VERSION ""

NS_ :

BS_:

BU_: L_DHRR_FD L_UWB_BLE_MST_FD L_UWB_RR_FD L_UWB_BLE_SLV_FD L_UWB_FR_FD L_ROA_FR_FD L_ROA_FD L_DHRL_FD L_UWB_TRNK_FD L_UWB_FRNK_FD L_EDT_FD L_UWB_FL_FD GW_BDC_FD L_UWB_RL_FD L_SAL_FD L_WPC_FD L_TPMS_FD L_DHL_FD L_DHR_FD

BO_ 830 SBCM_RL_FD_01_200ms: 24 GW_BDC_FD
 SG_ SBCM_RL_FD_Crc1Val : 0|16@1+ (1,0) [0|0] "" Vector__XXX
 SG_ USM_RLGhostDoorSta_Copy_0 : 100|2@1+ (1,0) [0|0] "" Vector__XXX
 SG_ DoorLock_PDSLkSwSta_RL_Copy_0 : 104|2@1+ (1,0) [0|0] "" Vector__XXX
 SG_ PDS_TypeOption_RL_Copy_0 : 106|2@1+ (1,0) [0|0] "" Vector__XXX
 SG_ RL_CrashMRActAlarm_Copy_0 : 138|2@1+ (1,0) [0|0] "" Vector__XXX
 SG_ PwrDRBuzzerOut_RL_Copy_0 : 140|2@1+ (1,0) [0|0] "" Vector__XXX
 SG_ PwrDRClosingRLDrSta_Copy_0 : 144|3@1+ (1,0) [0|0] "" Vector__XXX
 SG_ AFH_RL_FldUnfldSta_Copy_0 : 150|2@1+ (1,0) [0|0] "" Vector__XXX
 SG_ SBCM_RL_FD_AlvCnt1Val : 16|8@1+ (1,0) [0|0] "" Vector__XXX
 SG_ DoorLock_RrLtLkOutSta_SBCM_Copy_ : 166|2@1+ (1,0) [0|0] "" Vector__XXX
 SG_ RrLt_DrLkRetryFail_SBCM_Copy_0 : 171|2@1+ (1,0) [0|0] "" Vector__XXX
 SG_ RL_DetectObj_warn : 24|2@1+ (1,0) [0|0] "" Vector__XXX
 SG_ RLRrDrCurtainPosition : 26|2@1+ (1,0) [0|0] "" Vector__XXX
 SG_ RDC_TypeOption : 28|2@1+ (1,0) [0|0] "" Vector__XXX
 SG_ RLRrDrCurtainDownInitState : 30|2@1+ (1,0) [0|0] "" Vector__XXX
 SG_ PwrDRBuzzerOut_RL_New : 32|3@1+ (1,0) [0|0] "" Vector__XXX
 SG_ PwrDrSta_RrLt : 38|2@1+ (1,0) [0|0] "" Vector__XXX
 SG_ SBCM_RL_SlidePosition : 40|8@1+ (1,0) [0|0] "%" Vector__XXX
 SG_ SBCM_RL_DoorAngle : 48|7@1+ (1,0) [0|0] "вк" Vector__XXX
 SG_ RLDoorPushAlarm_Copy_0 : 72|2@1+ (1,0) [0|0] "" Vector__XXX
 SG_ RL_CrashUnlockCmd_Copy_0 : 74|1@1+ (1,0) [0|0] "" Vector__XXX
 SG_ Warn_RrLftDrSwSta_SBCM_Copy_0 : 80|2@1+ (1,0) [0|0] ""  L_UWB_BLE_MST_FD
 SG_ DoorLock_RrLftDrUnLkSta_SBCM_Cop : 82|2@1+ (1,0) [0|0] ""  L_UWB_BLE_MST_FD
 SG_ RL_SEAActivated_Copy_0 : 84|2@1+ (1,0) [0|0] "" Vector__XXX
 SG_ RL_SEAWarn_Copy_0 : 86|2@1+ (1,0) [0|0] "" Vector__XXX
 SG_ RL_SEWWarn_Copy_0 : 88|2@1+ (1,0) [0|0] "" Vector__XXX
 SG_ RL_ReleaseWarn_Copy_0 : 90|2@1+ (1,0) [0|0] "" Vector__XXX
 SG_ RL_SWFailAlarm_Copy_0 : 92|2@1+ (1,0) [0|0] "" Vector__XXX
 SG_ RL_ChildLock_ActnFlSta_Copy_0 : 94|2@1+ (1,0) [0|0] "" Vector__XXX
 SG_ RL_MRActivationAlarm_Copy_0 : 96|2@1+ (1,0) [0|0] "" Vector__XXX
 SG_ RL_ChildLock_Status_Copy_0 : 98|2@1+ (1,0) [0|0] "" Vector__XXX

BO_ 813 SBCM_DRV_FD_01_200ms: 32 GW_BDC_FD
 SG_ SBCM_DRV_FD_Crc1Val : 0|16@1+ (1,0) [0|0] "" Vector__XXX
 SG_ Latch_TypeOption_DRV_Copy_0 : 100|2@1+ (1,0) [0|0] ""  L_UWB_BLE_MST_FD
 SG_ DRV_SWFailAlarm_Copy_0 : 102|2@1+ (1,0) [0|0] "" Vector__XXX
 SG_ USM_PwrDRApprOpnSetSta_Copy_0 : 104|2@1+ (1,0) [0|0] "" Vector__XXX
 SG_ USM_PwrDRApprOpnSetOpt_Copy_0 : 106|2@1+ (1,0) [0|0] "" Vector__XXX
 SG_ USM_PwrDRCloseByRKELockSta_Copy_ : 108|2@1+ (1,0) [0|0] "" Vector__XXX
 SG_ USM_PwrDRCloseByRKELockOpt_Copy_ : 110|2@1+ (1,0) [0|0] "" Vector__XXX
 SG_ USM_PwrDRCloseByBrakeSta_Copy_0 : 112|2@1+ (1,0) [0|0] "" Vector__XXX
 SG_ USM_PwrDRCloseByBrakeOpt_Copy_0 : 114|2@1+ (1,0) [0|0] "" Vector__XXX
 SG_ USM_PwrDRBuzzerSta_Copy_0 : 116|2@1+ (1,0) [0|0] "" Vector__XXX
 SG_ USM_PwrDRBuzzerOpt_Copy_0 : 118|2@1+ (1,0) [0|0] "" Vector__XXX
 SG_ PDS_TypeOption_DRV_Copy_0 : 120|2@1+ (1,0) [0|0] "" Vector__XXX
 SG_ C_DrvDoorApproachOpen_Copy_0 : 122|2@1+ (1,0) [0|0] "" Vector__XXX
 SG_ C_DrvDoorApproachClose_Copy_0 : 124|2@1+ (1,0) [0|0] "" Vector__XXX
 SG_ DoorLock_PDSLkSwSta_DRV_Copy_0 : 126|2@1+ (1,0) [0|0] "" Vector__XXX
 SG_ SBCM_DRV_DiagSta_Copy_0 : 136|2@1+ (1,0) [0|0] "" Vector__XXX
 SG_ DoorLock_CtrlDrLkUnLkSwSta_SBCM_ : 138|2@1+ (1,0) [0|0] "" Vector__XXX
 SG_ SBCM_PsvDrLkReq_Copy_0 : 144|2@1+ (1,0) [0|0] "" Vector__XXX
 SG_ CDMAutoWashModeSet_SBCM_Copy_0 : 146|3@1+ (1,0) [0|0] "" Vector__XXX
 SG_ USM_DrvGhostDoorSta_Copy_0 : 150|2@1+ (1,0) [0|0] "" Vector__XXX
 SG_ Mirror_LH_FoldingSta_Copy_0 : 152|2@1+ (1,0) [0|0] "" Vector__XXX
 SG_ Mirror_LH_UnfoldingSta_Copy_0 : 154|2@1+ (1,0) [0|0] "" Vector__XXX
 SG_ DRV_CrashMRActAlarm_Copy_0 : 156|2@1+ (1,0) [0|0] "" Vector__XXX
 SG_ AFH_DRV_FldUnFldSta_Copy_0 : 158|2@1+ (1,0) [0|0] "" Vector__XXX
 SG_ SBCM_DRV_FD_AlvCnt1Val : 16|8@1+ (1,0) [0|0] "" Vector__XXX
 SG_ MirrorFldReq_Copy_0 : 160|2@1+ (1,0) [0|0] "" Vector__XXX
 SG_ OMU_TypeOption_DRV_Copy_0 : 162|2@1+ (1,0) [0|0] "" Vector__XXX
 SG_ IMS_OSMirPlayBackSta_LH_Copy_0 : 164|4@1+ (1,0) [0|0] "" Vector__XXX
 SG_ ECMMRR_PLUS_Copy_0 : 168|8@1+ (1,0) [0|0] "" Vector__XXX
 SG_ EHL_TxInfo_SBCM_DRV_Copy_0 : 176|3@1+ (1,0) [0|0] "" Vector__XXX
 SG_ IMS_OSMirPlayBackSta_LH_New_Copy : 184|4@1+ (1,0) [0|0] "" Vector__XXX
 SG_ CDM_InsideOpnSwSta_Copy_0 : 200|2@1+ (1,0) [0|0] "" Vector__XXX
 SG_ CDM_TypeOption_Copy_0 : 202|2@1+ (1,0) [0|0] "" Vector__XXX
 SG_ CDM_ImmeChgSw_SBCM_Copy_0 : 208|2@1+ (1,0) [0|0] "" Vector__XXX
 SG_ CDM_FobSrchReq_DRV_Copy_0 : 210|2@1+ (1,0) [0|0] "" Vector__XXX
 SG_ CDM_OpnClsState_SBCM_Copy_0 : 212|2@1+ (1,0) [0|0] "" Vector__XXX
 SG_ CDM_WarnMsg_SBCM_Copy_0 : 214|2@1+ (1,0) [0|0] "" Vector__XXX
 SG_ CDM_AutoWashModeSta_Copy_0 : 216|3@1+ (1,0) [0|0] "" Vector__XXX
 SG_ CDM_CmdStatus_SBCM_Copy_0 : 220|4@1+ (1,0) [0|0] "" Vector__XXX
 SG_ CDM_OutsideOpnSwSta_Copy_0 : 224|2@1+ (1,0) [0|0] "" Vector__XXX
 SG_ PwrDRBuzzerOut_DRV_Copy_0 : 226|2@1+ (1,0) [0|0] "" Vector__XXX
 SG_ Warn_HoodSwSta_SBCM_Copy_0 : 228|2@1+ (1,0) [0|0] ""  L_UWB_BLE_MST_FD
 SG_ Hood_TypeOption_Copy_0 : 230|2@1+ (1,0) [0|0] ""  L_UWB_BLE_MST_FD
 SG_ SBCM_FrunkSta_Copy_0 : 232|2@1+ (1,0) [0|0] "" Vector__XXX
 SG_ Warn_HoodSwFullSta_SBCM_Copy_0 : 234|2@1+ (1,0) [0|0] "" Vector__XXX
 SG_ FrunkWarning_SBCM_Copy_0 : 236|2@1+ (1,0) [0|0] "" Vector__XXX
 SG_ SBCM_Longkey_DRVDrAtClsSwSta_Cop : 238|2@1+ (1,0) [0|0] "" Vector__XXX
 SG_ FrunkReleaseSwSta_SBCM : 24|2@1+ (1,0) [0|0] "" Vector__XXX
 SG_ PwrDRClosingDRVDrSta_Copy_0 : 240|3@1+ (1,0) [0|0] "" Vector__XXX
 SG_ Drv_DrLkRetryFail_SBCM_Copy_0 : 243|2@1+ (1,0) [0|0] "" Vector__XXX
 SG_ CDM_GbtImmeChgSw_SBCM_Copy_0 : 246|2@1+ (1,0) [0|0] "" Vector__XXX
 SG_ CDM_GbtOpnClsState_SBCM_Copy_0 : 248|2@1+ (1,0) [0|0] "" Vector__XXX
 SG_ CDM_GbtWarnMsg_SBCM_Copy_0 : 250|2@1+ (1,0) [0|0] "" Vector__XXX
 SG_ CDM_GbtOutsideOpnSwSta_Copy_0 : 252|2@1+ (1,0) [0|0] "" Vector__XXX
 SG_ DoorLock_DrvLkOutSta_SBCM_Copy_0 : 254|2@1+ (1,0) [0|0] "" Vector__XXX
 SG_ FrunkEmergencySwSta_SBCM : 28|2@1+ (1,0) [0|0] "" Vector__XXX
 SG_ DRV_DetectObj_warn_LH : 30|2@1+ (1,0) [0|0] "" Vector__XXX
 SG_ PwrDROpenClosingDdvSdDRSta : 32|3@1+ (1,0) [0|0] "" Vector__XXX
 SG_ PwrDRBuzzerOut_DRV_New : 35|3@1+ (1,0) [0|0] "" Vector__XXX
 SG_ Coach_TypeOption_DRV : 38|2@1+ (1,0) [0|0] "" Vector__XXX
 SG_ PwrDrSta_Drv : 40|2@1+ (1,0) [0|0] "" Vector__XXX
 SG_ PwrDrSta_DrvSd : 42|2@1+ (1,0) [0|0] "" Vector__XXX
 SG_ USM_PwrDrOpnTypSta : 44|2@1+ (1,0) [0|0] "" Vector__XXX
 SG_ DischrgDr_OpnClsState_SBCM : 46|2@1+ (1,0) [0|0] "" Vector__XXX
 SG_ SBCM_FL_DoorAngle : 48|7@1+ (1,0) [0|0] "вк" Vector__XXX
 SG_ SBCM_DoorType_DRV : 60|2@1+ (1,0) [0|0] "" Vector__XXX
 SG_ CDM_DrType_DRV : 62|2@1+ (1,0) [0|0] "" Vector__XXX
 SG_ DRVDoorPushAlarm_Copy_0 : 72|2@1+ (1,0) [0|0] "" Vector__XXX
 SG_ DRV_CrashUnlockCmd_Copy_0 : 74|1@1+ (1,0) [0|0] "" Vector__XXX
 SG_ C_ApprOpenStatus_Copy_0 : 75|1@1+ (1,0) [0|0] "" Vector__XXX
 SG_ DoorLock_DrvKeyLkSwSta_SBCM_Copy : 80|2@1+ (1,0) [0|0] "" Vector__XXX
 SG_ DoorLock_DrvKeyUnLkSwSta_SBCM_Co : 82|2@1+ (1,0) [0|0] "" Vector__XXX
 SG_ Warn_DrvDrSwSta_SBCM_Copy_0 : 84|2@1+ (1,0) [0|0] ""  L_UWB_BLE_MST_FD
 SG_ DoorLock_DrvDrUnLkSta_SBCM_Copy_ : 86|2@1+ (1,0) [0|0] ""  L_UWB_BLE_MST_FD
 SG_ DRV_SEAWarn_LH_Copy_0 : 88|2@1+ (1,0) [0|0] "" Vector__XXX
 SG_ DRV_SEAWarn_RH_Copy_0 : 90|2@1+ (1,0) [0|0] "" Vector__XXX
 SG_ DRV_SEWWarn_LH_Copy_0 : 92|2@1+ (1,0) [0|0] "" Vector__XXX
 SG_ DRV_SEWWarn_RH_Copy_0 : 94|2@1+ (1,0) [0|0] "" Vector__XXX
 SG_ DRV_MRActivationAlarm_Copy_0 : 96|2@1+ (1,0) [0|0] "" Vector__XXX
 SG_ DRV_ReleaseWarn_Copy_0 : 98|2@1+ (1,0) [0|0] "" Vector__XXX

BO_ 811 SBCM_AST_FD_01_200ms: 32 GW_BDC_FD
 SG_ SBCM_AST_FD_Crc1Val : 0|16@1+ (1,0) [0|0] "" Vector__XXX
 SG_ USM_AstGhostDoorSta_Copy_0 : 100|2@1+ (1,0) [0|0] "" Vector__XXX
 SG_ AST_SWFailAlarm_Copy_0 : 102|2@1+ (1,0) [0|0] "" Vector__XXX
 SG_ DoorLock_PDSLkSwSta_AST_Copy_0 : 104|2@1+ (1,0) [0|0] "" Vector__XXX
 SG_ PDS_TypeOption_AST_Copy_0 : 106|2@1+ (1,0) [0|0] "" Vector__XXX
 SG_ AFCU_AutoWashModeSta_SBCM_AST_Co : 120|3@1+ (1,0) [0|0] "" Vector__XXX
 SG_ CDM_AutoWashModeSta_SBCM_AST_Cop : 123|3@1+ (1,0) [0|0] "" Vector__XXX
 SG_ AFH_AST_FldUnFldSta_Copy_0 : 126|2@1+ (1,0) [0|0] "" Vector__XXX
 SG_ SBCM_AST_DiagSta_Copy_0 : 136|2@1+ (1,0) [0|0] "" Vector__XXX
 SG_ CDM_TypeOption_AST_Copy_0 : 138|2@1+ (1,0) [0|0] "" Vector__XXX
 SG_ CDM_ImmeChgSw_AST_Copy_0 : 144|2@1+ (1,0) [0|0] "" Vector__XXX
 SG_ CDM_FobSrchReq_AST_Copy_0 : 146|2@1+ (1,0) [0|0] "" Vector__XXX
 SG_ CDM_OpnClsState_AST_Copy_0 : 148|2@1+ (1,0) [0|0] "" Vector__XXX
 SG_ CDM_WarnMsg_AST_Copy_0 : 150|2@1+ (1,0) [0|0] "" Vector__XXX
 SG_ Mirror_RH_FoldingSta_Copy_0 : 152|2@1+ (1,0) [0|0] "" Vector__XXX
 SG_ Mirror_RH_UnfoldingSta_Copy_0 : 154|2@1+ (1,0) [0|0] "" Vector__XXX
 SG_ CDM_CmdStatus_AST_Copy_0 : 156|4@1+ (1,0) [0|0] "" Vector__XXX
 SG_ SBCM_AST_FD_AlvCnt1Val : 16|8@1+ (1,0) [0|0] "" Vector__XXX
 SG_ AST_CrashMRActAlarm_Copy_0 : 160|2@1+ (1,0) [0|0] "" Vector__XXX
 SG_ PwrDRBuzzerOut_AST_Copy_0 : 162|2@1+ (1,0) [0|0] "" Vector__XXX
 SG_ IMS_OSMirPlayBackSta_RH_Copy_0 : 164|4@1+ (1,0) [0|0] "" Vector__XXX
 SG_ PwrDRClosingASTDrSta_Copy_0 : 168|3@1+ (1,0) [0|0] "" Vector__XXX
 SG_ CDM_OutsideOpnSwSta_AST_Copy_0 : 172|2@1+ (1,0) [0|0] "" Vector__XXX
 SG_ SBCM_Longkey_ASTDrAtClsSwSta_Cop : 174|2@1+ (1,0) [0|0] "" Vector__XXX
 SG_ Hood_TypeOption_AST_Copy_0 : 176|2@1+ (1,0) [0|0] "" Vector__XXX
 SG_ Warn_HoodSwSta_AST_Copy_0 : 178|2@1+ (1,0) [0|0] "" Vector__XXX
 SG_ FrunkWarning_AST_Copy_0 : 180|2@1+ (1,0) [0|0] "" Vector__XXX
 SG_ SBCM_FrunkSta_AST_Copy_0 : 182|2@1+ (1,0) [0|0] "" Vector__XXX
 SG_ IMS_OSMirPlayBackSta_RH_New_Copy : 184|4@1+ (1,0) [0|0] "" Vector__XXX
 SG_ Ast_DrLkRetryFail_SBCM_Copy_0 : 188|2@1+ (1,0) [0|0] "" Vector__XXX
 SG_ DoorLock_AstLkOutSta_SBCM_Copy_0 : 190|2@1+ (1,0) [0|0] "" Vector__XXX
 SG_ FrunkReleaseSwSta_SBCM_AST : 192|2@1+ (1,0) [0|0] "" Vector__XXX
 SG_ FrunkInsideRelSwSta_SBCM_AST : 194|2@1+ (1,0) [0|0] "" Vector__XXX
 SG_ FrunkEmergencySwSta_SBCM_AST : 196|2@1+ (1,0) [0|0] "" Vector__XXX
 SG_ PwrDrSta_Ast : 24|2@1+ (1,0) [0|0] "" Vector__XXX
 SG_ PwrDrSta_AstSd : 26|2@1+ (1,0) [0|0] "" Vector__XXX
 SG_ DischrgDr_OpnClsState_SBCM_AST : 28|2@1+ (1,0) [0|0] "" Vector__XXX
 SG_ AST_DetectObj_warn_LH : 30|2@1+ (1,0) [0|0] "" Vector__XXX
 SG_ PwrDROpenClosingAstSdDRSta : 32|3@1+ (1,0) [0|0] "" Vector__XXX
 SG_ PwrDRBuzzerOut_AST_New : 35|3@1+ (1,0) [0|0] "" Vector__XXX
 SG_ SBCM_FR_DoorAngle : 40|7@1+ (1,0) [0|0] "вк" Vector__XXX
 SG_ EHL_TxInfo_SBCM_AST : 47|3@1+ (1,0) [0|0] "" Vector__XXX
 SG_ CDM_DrType_AST : 62|2@1+ (1,0) [0|0] "" Vector__XXX
 SG_ ASTDoorPushAlarm_Copy_0 : 72|2@1+ (1,0) [0|0] "" Vector__XXX
 SG_ AST_CrashUnlockCmd_Copy_0 : 74|1@1+ (1,0) [0|0] "" Vector__XXX
 SG_ DoorLock_CtrlDrLkSwSta_SBCM_Copy : 80|2@1+ (1,0) [0|0] "" Vector__XXX
 SG_ DoorLock_CtrlDrUnLkSwSta_SBCM_Co : 82|2@1+ (1,0) [0|0] "" Vector__XXX
 SG_ Warn_AsstDrSwSta_SBCM_Copy_0 : 84|2@1+ (1,0) [0|0] ""  L_UWB_BLE_MST_FD
 SG_ DoorLock_AsstDrUnLkSta_SBCM_Copy : 86|2@1+ (1,0) [0|0] "" Vector__XXX
 SG_ AST_SEAWarn_RH_Copy_0 : 88|2@1+ (1,0) [0|0] "" Vector__XXX
 SG_ AST_SEAWarn_LH_Copy_0 : 90|2@1+ (1,0) [0|0] "" Vector__XXX
 SG_ AST_SEWWarn_LH_Copy_0 : 92|2@1+ (1,0) [0|0] "" Vector__XXX
 SG_ AST_SEWWarn_RH_Copy_0 : 94|2@1+ (1,0) [0|0] "" Vector__XXX
 SG_ AST_MRActivationAlarm_Copy_0 : 96|2@1+ (1,0) [0|0] "" Vector__XXX
 SG_ AST_ReleaseWarn_Copy_0 : 98|2@1+ (1,0) [0|0] "" Vector__XXX

BO_ 2525341953 L_UWB_FR_FD_05_00ms: 32 L_UWB_FR_FD
 SG_ L_UWB_FR_FD_Crc5Val : 0|16@1+ (1,0) [0|0] "" Vector__XXX
 SG_ L_UWB_FR_FD_AlvCnt5Val : 16|8@1+ (1,0) [0|0] "" Vector__XXX
 SG_ FR_SWID_3_IVD_2 : 24|24@1+ (1,0) [0|0] ""  L_UWB_BLE_MST_FD

BO_ 2521141761 L_UWB_BLE_MST_FD_23_200ms: 32 L_UWB_BLE_MST_FD
 SG_ L_UWB_BLE_MST_FD_Crc23Val : 0|16@1+ (1,0) [0|0] "" Vector__XXX
 SG_ L_UWB_BLE_MST_FD_AlvCnt23Val : 16|8@1+ (1,0) [0|0] "" Vector__XXX
 SG_ MST_DTC : 24|8@1+ (1,0) [0|0] ""  L_EDT_FD
 SG_ MST_DTC_BLE : 32|8@1+ (1,0) [0|0] ""  L_EDT_FD
 SG_ Pulse_Shape_Combo_Info : 40|9@1+ (1,0) [0|0] ""  GW_BDC_FD,L_EDT_FD

BO_ 2214592770 L_UWB_RR_FD_03_00ms: 32 L_UWB_RR_FD
 SG_ L_UWB_RR_FD_Crc3Val : 0|16@1+ (1,0) [0|0] "0" Vector__XXX
 SG_ L_UWB_RR_FD_AlvCnt3Val : 16|8@1+ (1,0) [0|0] "0" Vector__XXX
 SG_ UWB_RR_Ranging_Enc_Result2 : 216|40@1+ (1,0) [0|0] ""  GW_BDC_FD,L_UWB_BLE_MST_FD
 SG_ UWB_RR_Ranging_Enc_Result : 24|192@1+ (1,0) [0|0] ""  GW_BDC_FD,L_UWB_BLE_MST_FD

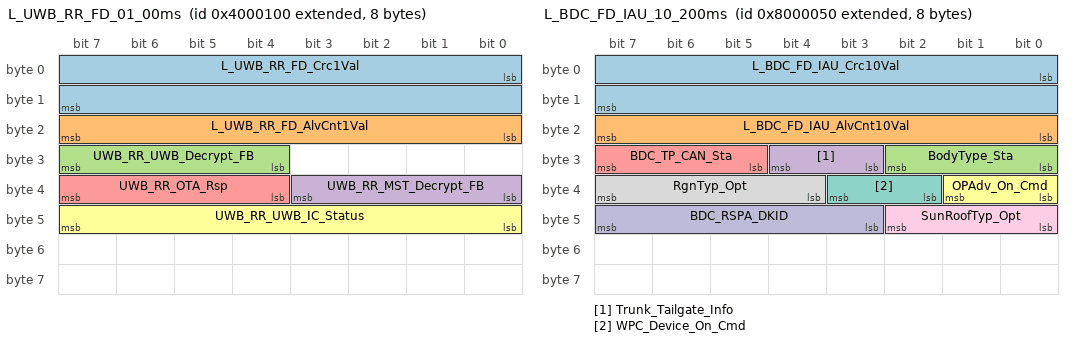
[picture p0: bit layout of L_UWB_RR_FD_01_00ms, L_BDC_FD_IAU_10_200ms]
BO_ 2214592768 L_UWB_RR_FD_01_00ms: 8 L_UWB_RR_FD
 SG_ L_UWB_RR_FD_Crc1Val : 0|16@1+ (1,0) [0|0] "0" Vector__XXX
 SG_ L_UWB_RR_FD_AlvCnt1Val : 16|8@1+ (1,0) [0|0] "0" Vector__XXX
 SG_ UWB_RR_UWB_Decrypt_FB : 28|4@1+ (1,0) [0|0] ""  GW_BDC_FD
 SG_ UWB_RR_MST_Decrypt_FB : 32|4@1+ (1,0) [0|0] ""  L_UWB_BLE_MST_FD
 SG_ UWB_RR_OTA_Rsp : 36|4@1+ (1,0) [0|0] ""  L_UWB_BLE_MST_FD
 SG_ UWB_RR_UWB_IC_Status : 40|8@1+ (1,0) [0|0] ""  L_EDT_FD

BO_ 2683310106 BDC_FD_DEV_1_TX: 32 GW_BDC_FD
 SG_ Devmsg_FD_1_TX : 0|256@1+ (1,0) [0|0] ""  L_EDT_FD,L_UWB_BLE_MST_FD

BO_ 2214592769 L_UWB_RR_FD_02_00ms: 16 L_UWB_RR_FD
 SG_ L_UWB_RR_FD_Crc2Val : 0|16@1+ (1,0) [0|0] "0" Vector__XXX
 SG_ L_UWB_RR_FD_AlvCnt2Val : 16|8@1+ (1,0) [0|0] "0" Vector__XXX
 SG_ UWB_RR_FOB_RSD_Enc_Result : 24|64@1+ (1,0) [0|0] ""  GW_BDC_FD

BO_ 2214592783 L_UWB_RR_FD_Dvp_01_00ms: 32 L_UWB_RR_FD
 SG_ UWB_RR_Dvp_Data : 0|256@1+ (1,0) [0|0] ""  L_EDT_FD

BO_ 2281701456 L_BDC_FD_IAU_10_200ms: 8 GW_BDC_FD
 SG_ L_BDC_FD_IAU_Crc10Val : 0|16@1+ (1,0) [0|0] "0" Vector__XXX
 SG_ L_BDC_FD_IAU_AlvCnt10Val : 16|8@1+ (1,0) [0|0] "0" Vector__XXX
 SG_ BodyType_Sta : 24|3@1+ (1,0) [0|0] ""  L_ROA_FD,L_ROA_FR_FD,L_UWB_BLE_MST_FD
 SG_ Trunk_Tailgate_Info : 27|2@1+ (1,0) [0|0] ""  L_UWB_BLE_MST_FD
 SG_ BDC_TP_CAN_Sta : 29|3@1+ (1,0) [0|0] ""  L_DHL_FD,L_DHRL_FD,L_DHRR_FD,L_DHR_FD,L_UWB_BLE_MST_FD,L_UWB_BLE_SLV_FD,L_UWB_FL_FD,L_UWB_FRNK_FD,L_UWB_FR_FD,L_UWB_RL_FD,L_UWB_RR_FD,L_UWB_TRNK_FD,L_WPC_FD
 SG_ OPAdv_On_Cmd : 32|2@1+ (1,0) [0|0] ""  L_UWB_BLE_MST_FD,L_UWB_BLE_SLV_FD,L_WPC_FD
 SG_ WPC_Device_On_Cmd : 34|2@1+ (1,0) [0|0] ""  L_WPC_FD
 SG_ RgnTyp_Opt : 36|4@1+ (1,0) [0|0] ""  L_ROA_FD,L_ROA_FR_FD,L_UWB_BLE_MST_FD,L_UWB_BLE_SLV_FD
 SG_ SunRoofTyp_Opt : 40|3@1+ (1,0) [0|0] ""  L_ROA_FD,L_ROA_FR_FD,L_UWB_BLE_MST_FD
 SG_ BDC_RSPA_DKID : 43|5@1+ (1,0) [0|0] ""  L_UWB_BLE_MST_FD,L_UWB_BLE_SLV_FD

BO_ 2281701457 L_BDC_FD_IAU_11_200ms: 16 GW_BDC_FD
 SG_ L_BDC_FD_IAU_Crc11Val : 0|16@1+ (1,0) [0|0] "0" Vector__XXX
 SG_ L_BDC_FD_IAU_AlvCnt11Val : 16|8@1+ (1,0) [0|0] "0" Vector__XXX
 SG_ UWB_Ranging_RndNum : 24|48@1+ (1,0) [0|0] ""  L_UWB_BLE_MST_FD

BO_ 2683310089 BDC_FD_IAU_DEV_2_RX: 32 L_EDT_FD
 SG_ Devmsg_FD_IAU_2_RX : 0|256@1+ (1,0) [0|0] ""  GW_BDC_FD

BO_ 2214592786 L_UWB_TRNK_FD_03_00ms: 32 L_UWB_TRNK_FD
 SG_ L_UWB_TRNK_FD_Crc3Val : 0|16@1+ (1,0) [0|0] "0" Vector__XXX
 SG_ L_UWB_TRNK_FD_AlvCnt3Val : 16|8@1+ (1,0) [0|0] "0" Vector__XXX
 SG_ UWB_TRNK_Ranging_Enc_Result2 : 216|40@1+ (1,0) [0|0] ""  GW_BDC_FD,L_UWB_BLE_MST_FD
 SG_ UWB_TRNK_Ranging_Enc_Result : 24|192@1+ (1,0) [0|0] ""  GW_BDC_FD,L_UWB_BLE_MST_FD

BO_ 2214592785 L_UWB_TRNK_FD_02_00ms: 16 L_UWB_TRNK_FD
 SG_ L_UWB_TRNK_FD_Crc2Val : 0|16@1+ (1,0) [0|0] "0" Vector__XXX
 SG_ L_UWB_TRNK_FD_AlvCnt2Val : 16|8@1+ (1,0) [0|0] "0" Vector__XXX
 SG_ UWB_TRNK_FOB_RSD_Enc_Result : 24|64@1+ (1,0) [0|0] ""  GW_BDC_FD

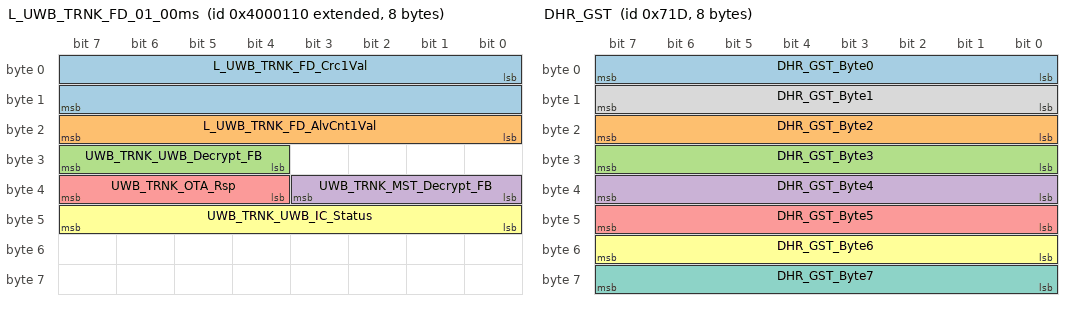
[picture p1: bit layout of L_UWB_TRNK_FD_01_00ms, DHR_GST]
BO_ 2214592784 L_UWB_TRNK_FD_01_00ms: 8 L_UWB_TRNK_FD
 SG_ L_UWB_TRNK_FD_Crc1Val : 0|16@1+ (1,0) [0|0] "0" Vector__XXX
 SG_ L_UWB_TRNK_FD_AlvCnt1Val : 16|8@1+ (1,0) [0|0] "0" Vector__XXX
 SG_ UWB_TRNK_UWB_Decrypt_FB : 28|4@1+ (1,0) [0|0] ""  GW_BDC_FD
 SG_ UWB_TRNK_MST_Decrypt_FB : 32|4@1+ (1,0) [0|0] ""  L_UWB_BLE_MST_FD
 SG_ UWB_TRNK_OTA_Rsp : 36|4@1+ (1,0) [0|0] ""  L_UWB_BLE_MST_FD
 SG_ UWB_TRNK_UWB_IC_Status : 40|8@1+ (1,0) [0|0] ""  L_EDT_FD

BO_ 2214592799 L_UWB_TRNK_FD_Dvp_01_00ms: 32 L_UWB_TRNK_FD
 SG_ UWB_TRNK_Dvp_Data : 0|255@1+ (1,0) [0|0] ""  L_EDT_FD

BO_ 2683310087 BDC_FD_IAU_DEV_1_RX: 32 L_EDT_FD
 SG_ Devmsg_FD_IAU_1_RX : 0|256@1+ (1,0) [0|0] ""  GW_BDC_FD

BO_ 2533738497 L_UWB_FRNK_FD_04_00ms: 32 L_UWB_FRNK_FD
 SG_ L_UWB_FRNK_FD_Crc4Val : 0|16@1+ (1,0) [0|0] "" Vector__XXX
 SG_ L_UWB_FRNK_FD_AlvCnt4Val : 16|8@1+ (1,0) [0|0] "" Vector__XXX
 SG_ FRNK_SWID_3_IVD_1 : 24|232@1+ (1,0) [0|0] ""  L_UWB_BLE_MST_FD

BO_ 2529540097 L_UWB_RR_FD_04_00ms: 32 L_UWB_RR_FD
 SG_ L_UWB_RR_FD_Crc4Val : 0|16@1+ (1,0) [0|0] "" Vector__XXX
 SG_ L_UWB_RR_FD_AlvCnt4Val : 16|8@1+ (1,0) [0|0] "" Vector__XXX
 SG_ RR_SWID_3_IVD_1 : 24|232@1+ (1,0) [0|0] ""  L_UWB_BLE_MST_FD

BO_ 1337 UWB_RR_FD_30_500ms: 16 L_UWB_RR_FD
 SG_ UWB_RR_FD_Crc30Val : 0|16@1+ (1,0) [0|0] "" Vector__XXX
 SG_ UWB_RR_FD_AlvCnt30Val : 16|8@1+ (1,0) [0|0] "" Vector__XXX
 SG_ UWB_RR_ResetOpsta : 24|2@1+ (1,0) [0|0] ""  GW_BDC_FD

BO_ 1336 UWB_RL_FD_30_500ms: 16 L_UWB_RL_FD
 SG_ UWB_RL_FD_Crc30Val : 0|16@1+ (1,0) [0|0] "" Vector__XXX
 SG_ UWB_RL_FD_AlvCnt30Val : 16|8@1+ (1,0) [0|0] "" Vector__XXX
 SG_ UWB_RL_ResetOpsta : 24|2@1+ (1,0) [0|0] ""  GW_BDC_FD

BO_ 850 IAU_FD_05_200ms: 32 GW_BDC_FD
 SG_ IAU_FD_Crc5Val : 0|16@1+ (1,0) [0|0] "" Vector__XXX
 SG_ IAU_DigitalKeyProfileRval_Copy_0 : 112|4@1+ (1,0) [0|0] "" Vector__XXX
 SG_ IAU_SharedPhnRegStat_Copy_0 : 116|2@1+ (1,0) [0|0] ""  L_DHL_FD,L_DHRL_FD,L_DHRR_FD,L_DHR_FD,L_UWB_BLE_MST_FD,L_UWB_BLE_SLV_FD,L_UWB_FL_FD,L_UWB_FRNK_FD,L_UWB_FR_FD,L_UWB_RL_FD,L_UWB_RR_FD,L_UWB_TRNK_FD,L_WPC_FD
 SG_ IAU_CardKeyEnblRVal_Copy_0 : 118|2@1+ (1,0) [0|0] ""  L_DHL_FD,L_DHRL_FD,L_DHRR_FD,L_DHR_FD
 SG_ IAU_DrvDHLPhnDetect_Copy_0 : 120|2@1+ (1,0) [0|0] "" Vector__XXX
 SG_ IAU_AstDHLPhnDetect_Copy_0 : 122|2@1+ (1,0) [0|0] "" Vector__XXX
 SG_ IAU_RLDHLPhnDetect_Copy_0 : 124|2@1+ (1,0) [0|0] "" Vector__XXX
 SG_ IAU_RRDHLPhnDetect_Copy_0 : 126|2@1+ (1,0) [0|0] "" Vector__XXX
 SG_ IAU_Manufacturer_Copy_0 : 128|8@1+ (1,0) [0|0] "" Vector__XXX
 SG_ IAU_VendorCode_Copy_0 : 136|24@1+ (1,0) [0|0] "" Vector__XXX
 SG_ IAU_FD_AlvCnt5Val : 16|8@1+ (1,0) [0|0] "" Vector__XXX
 SG_ IAU_Serial_Copy_0 : 160|32@1+ (1,0) [0|0] "" Vector__XXX
 SG_ IAU_Year_Copy_0 : 192|16@1+ (1,0) [0|0] "" Vector__XXX
 SG_ IAU_Month_Copy_0 : 208|8@1+ (1,0) [0|0] "" Vector__XXX
 SG_ IAU_Date_Copy_0 : 216|16@1+ (1,0) [0|0] "" Vector__XXX
 SG_ IAU_SWVerMajor1_Copy_0 : 232|7@1+ (1,0) [0|0] "" Vector__XXX
 SG_ IAU_DrvDhsRainStat : 24|1@1+ (1,0) [0|0] "" Vector__XXX
 SG_ IAU_SWVerMinor1_Copy_0 : 240|7@1+ (1,0) [0|0] "" Vector__XXX
 SG_ IAU_SWVerMinor2_Copy_0 : 248|7@1+ (1,0) [0|0] "" Vector__XXX
 SG_ IAU_AstDhsRainStat : 25|1@1+ (1,0) [0|0] "" Vector__XXX
 SG_ IAU_RLDhsRainStat : 26|1@1+ (1,0) [0|0] "" Vector__XXX
 SG_ IAU_RRDhsRainStat : 27|1@1+ (1,0) [0|0] "" Vector__XXX

BO_ 1821 DHR_GST: 8 L_DHR_FD
 SG_ DHR_GST_Byte0 : 0|8@1+ (1,0) [0|0] ""  GW_BDC_FD
 SG_ DHR_GST_Byte2 : 16|8@1+ (1,0) [0|0] ""  GW_BDC_FD
 SG_ DHR_GST_Byte3 : 24|8@1+ (1,0) [0|0] ""  GW_BDC_FD
 SG_ DHR_GST_Byte4 : 32|8@1+ (1,0) [0|0] ""  GW_BDC_FD
 SG_ DHR_GST_Byte5 : 40|8@1+ (1,0) [0|0] ""  GW_BDC_FD
 SG_ DHR_GST_Byte6 : 48|8@1+ (1,0) [0|0] ""  GW_BDC_FD
 SG_ DHR_GST_Byte7 : 56|8@1+ (1,0) [0|0] ""  GW_BDC_FD
 SG_ DHR_GST_Byte1 : 8|8@1+ (1,0) [0|0] ""  GW_BDC_FD

CM_ BO_ 830 "[PE] Periodic and On Event";
CM_ SG_ 830 SBCM_RL_FD_Crc1Val "SBCM_RL_FD_CyclicRedundancyCheck1Value";
CM_ SG_ 830 SBCM_RL_FD_AlvCnt1Val "SBCM_RL_FD_AliveCounter1Value";
CM_ SG_ 830 RL_CrashUnlockCmd_Copy_0 "Rear Lefr Crash Unlock Command";
CM_ SG_ 830 Warn_RrLftDrSwSta_SBCM_Copy_0 "Warn_RearLeftDoorSwitchStatus ##2G## -  - C_RLDrSw,CF_Gway_RLDrSw,Warn_RrLftDrSwSta";
CM_ SG_ 830 DoorLock_RrLftDrUnLkSta_SBCM_Cop "DoorLock_RearLeftDoorUnLockStatus ##2G## -  - C_RLUnlockState,DoorLock_RrLftDrUnLkSta";
CM_ SG_ 830 RL_SEAActivated_Copy_0 "RearLeftSEAActivated";
CM_ SG_ 830 RL_SEAWarn_Copy_0 "Rear Left SEA Warning";
CM_ BO_ 813 "[PE] Periodic and On Event";
CM_ SG_ 813 SBCM_DRV_FD_Crc1Val "SBCM_DRV_FD_CyclicRedundancyCheck1Value";
CM_ SG_ 813 C_DrvDoorApproachOpen_Copy_0 "Approach open";
CM_ SG_ 813 DoorLock_CtrlDrLkUnLkSwSta_SBCM_ "Central Door Lock/Unlock Switch State";
CM_ SG_ 813 CDMAutoWashModeSet_SBCM_Copy_0 "Auto wash mode set signal for CDM from SBCM_DRV";
CM_ SG_ 813 SBCM_DRV_FD_AlvCnt1Val "SBCM_DRV_FD_AliveCounter1Value";
CM_ SG_ 813 ECMMRR_PLUS_Copy_0 "ECM Voltage value";
CM_ SG_ 813 EHL_TxInfo_SBCM_DRV_Copy_0 "Electronic hood latch status signal transfer for dual hood latch type (Copy to CANFD)";
CM_ SG_ 813 CDM_TypeOption_Copy_0 "CDM_HS_OptionType";
CM_ SG_ 813 CDM_ImmeChgSw_SBCM_Copy_0 "State of Immediate Charging Switch";
CM_ SG_ 813 CDM_OpnClsState_SBCM_Copy_0 "CDM_HS_ OpenCloseState";
CM_ SG_ 813 CDM_WarnMsg_SBCM_Copy_0 "CDM_HS_WarningMessage";
CM_ SG_ 813 CDM_CmdStatus_SBCM_Copy_0 "CDM_HS_CommandStatus";
CM_ SG_ 813 Hood_TypeOption_Copy_0 "E-Hood_Option Type";
CM_ SG_ 813 FrunkReleaseSwSta_SBCM "FrunkReleaseState";
CM_ SG_ 813 CDM_GbtImmeChgSw_SBCM_Copy_0 "State of Immediate Charging Switch";
CM_ SG_ 813 CDM_GbtOpnClsState_SBCM_Copy_0 "CDM_HS_ OpenCloseState";
CM_ SG_ 813 CDM_GbtWarnMsg_SBCM_Copy_0 "CDM_HS_WarningMessage";
CM_ SG_ 813 FrunkEmergencySwSta_SBCM "FrunkEmergencySwState";
CM_ SG_ 813 C_ApprOpenStatus_Copy_0 "Stop fob searching signal";
CM_ SG_ 813 DoorLock_DrvKeyLkSwSta_SBCM_Copy "DoorLock_DriverKeyLockSwitchStatus ##2G## -  - C_DrvKeyLockSw";
CM_ SG_ 813 DoorLock_DrvKeyUnLkSwSta_SBCM_Co "DoorLock_DriverKeyUnLockSwitchStatus ##2G## -  - C_DrvKeyUnlockSw";
CM_ SG_ 813 Warn_DrvDrSwSta_SBCM_Copy_0 "DoorLock_DriverDoorSwitchStatus ##2G## -  - C_DrvDrSw,CF_Gway_DrvDrSw,Warn_DrvDrSwSta";
CM_ SG_ 813 DoorLock_DrvDrUnLkSta_SBCM_Copy_ "DoorLock_DriverDoorUnLockStatus ##2G## -  - C_DrvUnlockState,CF_Gway_DrvUnlockState";
CM_ BO_ 811 "[PE] Periodic and On Event";
CM_ SG_ 811 SBCM_AST_FD_Crc1Val "SBCM_AST_FD_CyclicRedundancyCheck1Value";
CM_ SG_ 811 SBCM_AST_FD_AlvCnt1Val "SBCM_AST_FD_AliveCounter1Value";
CM_ SG_ 811 SBCM_Longkey_ASTDrAtClsSwSta_Cop "FCS Power Door Long key Status";
CM_ SG_ 811 Hood_TypeOption_AST_Copy_0 "E-Hood_Option Type";
CM_ SG_ 811 FrunkReleaseSwSta_SBCM_AST "FrunkReleaseState (SBCM_AST_FD to SBCM_DRV_FD) RHD Spec";
CM_ SG_ 811 FrunkInsideRelSwSta_SBCM_AST "FrunkInsideReleaseSwState (SBCM_AST_FD to SBCM_DRV_FD) RHD Spec";
CM_ SG_ 811 FrunkEmergencySwSta_SBCM_AST "FrunkEmergencySwState (SBCM_AST_FD to SBCM_DRV_FD) RHD Spec";
CM_ SG_ 811 EHL_TxInfo_SBCM_AST "Electronic hood latch status signal transfer for dual hood latch type";
CM_ SG_ 811 AST_CrashUnlockCmd_Copy_0 "AssistCrashUnlockCommand";
CM_ SG_ 811 DoorLock_CtrlDrLkSwSta_SBCM_Copy "DoorLock_CentralDoorLockAssistSwitchStatus";
CM_ SG_ 811 DoorLock_CtrlDrUnLkSwSta_SBCM_Co "DoorLock_CentralDoorUnLockAssistSwitchStatus";
CM_ SG_ 811 Warn_AsstDrSwSta_SBCM_Copy_0 "Warn_AssistDoorSwitchStatus ##2G## -  - C_AstDrSw,CF_Gway_AstDrSw,Warn_AsstDrSwSta";
CM_ SG_ 811 DoorLock_AsstDrUnLkSta_SBCM_Copy "DoorLock_AssistDoorUnLockStatus ##2G## -  - C_AstUnlockState,DoorLock_AsstDrUnLkSta";
CM_ SG_ 811 AST_SEAWarn_RH_Copy_0 "Assist SEA Warning (LHD)";
CM_ BO_ 2525341953 "[EW] On Event and On Write";
CM_ SG_ 2525341953 L_UWB_FR_FD_Crc5Val "L_UWB_FR_FD_CyclicRedundancyCheck5Value";
CM_ SG_ 2525341953 L_UWB_FR_FD_AlvCnt5Val "L_UWB_FR_FD_AliveCounter5Value";
CM_ SG_ 2525341953 FR_SWID_3_IVD_2 "UWB FR SW Unit 3 IVD2";
CM_ BO_ 2521141761 "[PE] Periodic and On Event";
CM_ SG_ 2521141761 L_UWB_BLE_MST_FD_Crc23Val "L_UWB_BLE_MST_FD_CyclicRedundancyCheck23Value";
CM_ SG_ 2521141761 L_UWB_BLE_MST_FD_AlvCnt23Val "L_UWB_BLE_MST_FD_AliveCounter23Value";
CM_ SG_ 2521141761 MST_DTC "Master DTC Data";
CM_ SG_ 2521141761 MST_DTC_BLE "Master BLE DTC Data";
CM_ SG_ 2521141761 Pulse_Shape_Combo_Info "UWB Pulse_Spape_combo Information";
CM_ BO_ 2214592770 "[EW] On Event and On Write";
CM_ SG_ 2214592770 L_UWB_RR_FD_Crc3Val "L_UWB_RR_FD_CyclicRedundancyCheck3Value";
CM_ SG_ 2214592770 L_UWB_RR_FD_AlvCnt3Val "L_UWB_RR_FD_AliveCounter3Value";
CM_ SG_ 2214592770 UWB_RR_Ranging_Enc_Result2 "UWB Ranging Result2(Encrypted Data) with DK";
CM_ SG_ 2214592770 UWB_RR_Ranging_Enc_Result "UWB Ranging Result with DK";
CM_ BO_ 2214592768 "[EC] On Event and On Change";
CM_ SG_ 2214592768 L_UWB_RR_FD_Crc1Val "L_UWB_RR_FD_CyclicRedundancyCheck1Value";
CM_ SG_ 2214592768 L_UWB_RR_FD_AlvCnt1Val "L_UWB_RR_FD_AliveCounter1Value";
CM_ SG_ 2214592768 UWB_RR_UWB_Decrypt_FB "Decryption Feedback for UWB (to BDC)";
CM_ SG_ 2214592768 UWB_RR_MST_Decrypt_FB "UWB RR Decryption FeedBack (to Master)";
CM_ SG_ 2214592768 UWB_RR_OTA_Rsp "UWB RR OTA response";
CM_ SG_ 2214592768 UWB_RR_UWB_IC_Status "UWB IC Status Message";
CM_ BO_ 2683310106 "[EW] On Event and On Write";
CM_ BO_ 2214592769 "[EC] On Event and On Change";
CM_ SG_ 2214592769 L_UWB_RR_FD_Crc2Val "L_UWB_RR_FD_CyclicRedundancyCheck2Value";
CM_ SG_ 2214592769 L_UWB_RR_FD_AlvCnt2Val "L_UWB_RR_FD_AliveCounter2Value";
CM_ SG_ 2214592769 UWB_RR_FOB_RSD_Enc_Result "UWB Ranging Result with FOB";
CM_ BO_ 2214592783 "[EW] On Event and On Write";
CM_ SG_ 2214592783 UWB_RR_Dvp_Data "Development Message";
CM_ BO_ 2281701456 "[PE] Periodic and On Event";
CM_ SG_ 2281701456 L_BDC_FD_IAU_Crc10Val "L_BDC_FD_IAU_CyclicRedundancyCheck10Value";
CM_ SG_ 2281701456 L_BDC_FD_IAU_AlvCnt10Val "L_BDC_FD_IAU_AliveCounter10Value";
CM_ SG_ 2281701456 BodyType_Sta "Body & Bumper type Status";
CM_ SG_ 2281701456 Trunk_Tailgate_Info "Trunk and Tailgate Type";
CM_ SG_ 2281701456 BDC_TP_CAN_Sta "BDC Processing Status";
CM_ SG_ 2281701456 OPAdv_On_Cmd "BLE Owner Pairing Advertising Reqeust";
CM_ SG_ 2281701456 WPC_Device_On_Cmd "Inform device on WPC";
CM_ SG_ 2281701456 RgnTyp_Opt "BDC EOL Region Type Option";
CM_ SG_ 2281701456 SunRoofTyp_Opt "BDC EOL Sunroof Type Option";
CM_ BO_ 2281701457 "[PE] Periodic and On Event";
CM_ SG_ 2281701457 L_BDC_FD_IAU_Crc11Val "L_BDC_FD_IAU_CyclicRedundancyCheck11Value";
CM_ SG_ 2281701457 L_BDC_FD_IAU_AlvCnt11Val "L_BDC_FD_IAU_AliveCounter11Value";
CM_ SG_ 2281701457 UWB_Ranging_RndNum "Random number for encryption of Digital Key UWB Ragning";
CM_ BO_ 2683310089 "[EW] On Event and On Write";
CM_ BO_ 2214592786 "[EW] On Event and On Write";
CM_ SG_ 2214592786 L_UWB_TRNK_FD_Crc3Val "L_UWB_TRNK_FD_CyclicRedundancyCheck3Value";
CM_ SG_ 2214592786 L_UWB_TRNK_FD_AlvCnt3Val "L_UWB_TRNK_FD_AliveCounter3Value";
CM_ SG_ 2214592786 UWB_TRNK_Ranging_Enc_Result2 "UWB Ranging Result2(Encrypted Data) with DK";
CM_ SG_ 2214592786 UWB_TRNK_Ranging_Enc_Result "UWB Ranging Result with DK";
CM_ BO_ 2214592785 "[EC] On Event and On Change";
CM_ SG_ 2214592785 L_UWB_TRNK_FD_Crc2Val "L_UWB_TRNK_FD_CyclicRedundancyCheck2Value";
CM_ SG_ 2214592785 L_UWB_TRNK_FD_AlvCnt2Val "L_UWB_TRNK_FD_AliveCounter2Value";
CM_ SG_ 2214592785 UWB_TRNK_FOB_RSD_Enc_Result "UWB Ranging Result with FOB";
CM_ BO_ 2214592784 "[EC] On Event and On Change";
CM_ SG_ 2214592784 L_UWB_TRNK_FD_Crc1Val "L_UWB_TRNK_FD_CyclicRedundancyCheck1Value";
CM_ SG_ 2214592784 L_UWB_TRNK_FD_AlvCnt1Val "L_UWB_TRNK_FD_AliveCounter1Value";
CM_ SG_ 2214592784 UWB_TRNK_UWB_Decrypt_FB "Decryption Feedback for UWB (to BDC)";
CM_ SG_ 2214592784 UWB_TRNK_MST_Decrypt_FB "UWB TRNK Decryption FeedBack (to Master)";
CM_ SG_ 2214592784 UWB_TRNK_OTA_Rsp "UWB TRNK OTA response";
CM_ SG_ 2214592784 UWB_TRNK_UWB_IC_Status "UWB IC Status Message";
CM_ BO_ 2214592799 "[EW] On Event and On Write";
CM_ SG_ 2214592799 UWB_TRNK_Dvp_Data "Development Message";
CM_ BO_ 2683310087 "[EW] On Event and On Write";
CM_ BO_ 2533738497 "[EW] On Event and On Write";
CM_ SG_ 2533738497 L_UWB_FRNK_FD_Crc4Val "L_UWB_FRNK_FD_CyclicRedundancyCheck4Value";
CM_ SG_ 2533738497 L_UWB_FRNK_FD_AlvCnt4Val "L_UWB_FRNK_FD_AliveCounter4Value";
CM_ SG_ 2533738497 FRNK_SWID_3_IVD_1 "UWB FRNK SW Unit 3 IVD1";
CM_ BO_ 2529540097 "[EW] On Event and On Write";
CM_ SG_ 2529540097 L_UWB_RR_FD_Crc4Val "L_UWB_RR_FD_CyclicRedundancyCheck4Value";
CM_ SG_ 2529540097 L_UWB_RR_FD_AlvCnt4Val "L_UWB_RR_FD_AliveCounter4Value";
CM_ SG_ 2529540097 RR_SWID_3_IVD_1 "UWB RR SW Unit 3 IVD1";
CM_ BO_ 1337 "[PE] Periodic and On Event";
CM_ SG_ 1337 UWB_RR_FD_Crc30Val "UWB_RR_FD_CyclicRedundancyCheck30Value";
CM_ SG_ 1337 UWB_RR_FD_AlvCnt30Val "UWB_RR_FD_AliveCounter30Value";
CM_ SG_ 1337 UWB_RR_ResetOpsta "This signal indicates whether the reset operation has been completed or not";
CM_ BO_ 1336 "[PE] Periodic and On Event";
CM_ SG_ 1336 UWB_RL_FD_Crc30Val "UWB_RL_FD_CyclicRedundancyCheck30Value";
CM_ SG_ 1336 UWB_RL_FD_AlvCnt30Val "UWB_RL_FD_AliveCounter30Value";
CM_ SG_ 1336 UWB_RL_ResetOpsta "This signal indicates whether the reset operation has been completed or not";
CM_ BO_ 850 "[PE] Periodic and On Event";
CM_ SG_ 850 IAU_FD_Crc5Val "IAU_FD_CyclicRedundancyCheck5Value";
CM_ SG_ 850 IAU_DigitalKeyProfileRval_Copy_0 "This signal indiactes digital key number paired with selected profile";
CM_ SG_ 850 IAU_CardKeyEnblRVal_Copy_0 "Card Key Function Enable / Disable flag (Fob is required for changing flag)";
CM_ SG_ 850 IAU_FD_AlvCnt5Val "IAU_FD_AliveCounter5Value";
CM_ SG_ 850 IAU_SWVerMajor1_Copy_0 "First Word(ASCII) in IAU S/W Ver";
CM_ SG_ 850 IAU_SWVerMinor1_Copy_0 "Second Word(ASCII) in IAU S/W Ver";
CM_ SG_ 850 IAU_SWVerMinor2_Copy_0 "Third Word(ASCII) in IAU S/W Ver";
CM_ BO_ 1821 "[TP] Transport Protocol";
BA_DEF_ BO_  "CANFD_BRS" ENUM  "0","1";
BA_DEF_ BO_  "GenMsgEVName" STRING ;
BA_DEF_ BO_  "NmAsrMessage" ENUM  "No","Yes";
BA_DEF_ BO_  "DiagState" ENUM  "No","Yes";
BA_DEF_ BO_  "DiagResponse" ENUM  "No","Yes";
BA_DEF_ BO_  "DiagRequest" ENUM  "No","Yes";
BA_DEF_ BO_  "TpMessage" ENUM  "No","Yes";
BA_DEF_ BO_  "UsrMsgIDSforwardDeviation" INT 0 100;
BA_DEF_ BO_  "UsrMsgIDSbackwardDeviation" INT 50 1000;
BA_DEF_ BO_  "GenMsgCycleTime" INT 0 2000;
BA_DEF_ BO_  "GenMsgStartDelayTime" INT 0 2000;
BA_DEF_ BO_  "GenMsgSendType" ENUM  "Cyclic","NoMsgSendType";
BA_DEF_ BO_  "GenMsgCycleTimeFast" INT 0 500;
BA_DEF_ BO_  "GenMsgDelayTime" INT 0 20;
BA_DEF_ BO_  "GenMsgILSupport" ENUM  "No","Yes";
BA_DEF_ BO_  "GenMsgNrOfRepetition" INT 0 3;
BA_DEF_ BO_  "TpTxIndex" INT 0 65535;
BA_DEF_ BO_  "VFrameFormat" ENUM  "StandardCAN","ExtendedCAN","reserved","reserved","reserved","reserved","reserved","reserved","reserved","reserved","reserved","reserved","reserved","reserved","StandardCAN_FD","ExtendedCAN_FD";
BA_DEF_ SG_  "UserSigValidity" ENUM  "B+","ACC","IG","IG1","IG2","IG3","IG1 or IG2","IG1 or IG3","Undef";
BA_DEF_ SG_  "TimeoutValue" STRING ;
BA_DEF_ SG_  "UsrSigPurpose" ENUM  "Undef","FN","DIAG","DIAG(Req)","DIAG(Res)","DIAG(Func)","DEV","CCP","NM","TP";
BA_DEF_ SG_  "GenSigStartValue" INT 0 1215752192;
BA_DEF_ SG_  "NetworkRequest" ENUM  "Yes","No";
BA_DEF_ SG_  "NetworkRequestHoldingTime" INT 0 65535;
BA_DEF_ SG_  "Description" STRING ;
BA_DEF_ SG_  "Version" STRING ;
BA_DEF_ SG_  "GenSigEnvVarType" ENUM  "Int","Float","Undef";
BA_DEF_ SG_  "GenSigSendType" ENUM  "Cyclic","OnWrite","OnWriteWithRepetition","OnChange","OnChangeWithRepetition","IfActive","IfActiveWithRepetition","NoSigSendType","OnChangeAndIfActive","OnChangeAndIfActiveWithRepetition";
BA_DEF_ SG_  "GwSigLatencyTime" INT 0 65536;
BA_DEF_ SG_  "GwSigMissingSourceType" ENUM  "Undef","OldValue","DefaultValue","InitialValue";
BA_DEF_ SG_  "NWM-WakeupAllowed" ENUM  "<n.a.>";
BA_DEF_ SG_  "RoutingFactor" INT 1 1215752192;
BA_DEF_ SG_  "SystemSignalLongSymbol" STRING ;
BA_DEF_REL_ BU_SG_REL_  "GenSigTimeoutTime" INT 0 7000;
BA_DEF_DEF_  "CANFD_BRS" "1";
BA_DEF_DEF_  "GenMsgEVName" "@Signame";
BA_DEF_DEF_  "NmAsrMessage" "No";
BA_DEF_DEF_  "DiagState" "No";
BA_DEF_DEF_  "DiagResponse" "No";
BA_DEF_DEF_  "DiagRequest" "No";
BA_DEF_DEF_  "TpMessage" "No";
BA_DEF_DEF_  "UsrMsgIDSforwardDeviation" 10;
BA_DEF_DEF_  "UsrMsgIDSbackwardDeviation" 100;
BA_DEF_DEF_  "GenMsgCycleTime" 200;
BA_DEF_DEF_  "GenMsgStartDelayTime" 0;
BA_DEF_DEF_  "GenMsgSendType" "NoMsgSendType";
BA_DEF_DEF_  "GenMsgCycleTimeFast" 40;
BA_DEF_DEF_  "GenMsgDelayTime" 20;
BA_DEF_DEF_  "GenMsgILSupport" "Yes";
BA_DEF_DEF_  "GenMsgNrOfRepetition" 3;
BA_DEF_DEF_  "TpTxIndex" 0;
BA_DEF_DEF_  "VFrameFormat" "StandardCAN";
BA_DEF_DEF_  "UserSigValidity" "IG";
BA_DEF_DEF_  "TimeoutValue" "";
BA_DEF_DEF_  "UsrSigPurpose" "FN";
BA_DEF_DEF_  "GenSigStartValue" 0;
BA_DEF_DEF_  "NetworkRequest" "No";
BA_DEF_DEF_  "NetworkRequestHoldingTime" 0;
BA_DEF_DEF_  "Description" "";
BA_DEF_DEF_  "Version" "";
BA_DEF_DEF_  "GenSigEnvVarType" "Undef";
BA_DEF_DEF_  "GenSigSendType" "NoSigSendType";
BA_DEF_DEF_  "GwSigLatencyTime" 40;
BA_DEF_DEF_  "GwSigMissingSourceType" "Undef";
BA_DEF_DEF_  "NWM-WakeupAllowed" "<n.a.>";
BA_DEF_DEF_  "RoutingFactor" 1;
BA_DEF_DEF_REL_ "GenSigTimeoutTime" 500;
BA_DEF_DEF_  "SystemSignalLongSymbol" "";
BA_ "GenMsgSendType" BO_ 830 0;
BA_ "VFrameFormat" BO_ 830 14;
BA_ "GenMsgSendType" BO_ 813 0;
BA_ "VFrameFormat" BO_ 813 14;
BA_ "GenMsgSendType" BO_ 811 0;
BA_ "VFrameFormat" BO_ 811 14;
BA_ "GenMsgDelayTime" BO_ 2525341953 10;
BA_ "GenMsgCycleTime" BO_ 2525341953 0;
BA_ "VFrameFormat" BO_ 2525341953 15;
BA_ "GenMsgSendType" BO_ 2521141761 0;
BA_ "VFrameFormat" BO_ 2521141761 15;
BA_ "GenMsgDelayTime" BO_ 2214592770 10;
BA_ "GenMsgCycleTime" BO_ 2214592770 0;
BA_ "VFrameFormat" BO_ 2214592770 15;
BA_ "GenMsgCycleTime" BO_ 2214592768 0;
BA_ "VFrameFormat" BO_ 2214592768 15;
BA_ "GenMsgDelayTime" BO_ 2683310106 10;
BA_ "GenMsgNrOfRepetition" BO_ 2683310106 0;
BA_ "GenMsgCycleTime" BO_ 2683310106 0;
BA_ "VFrameFormat" BO_ 2683310106 15;
BA_ "GenMsgCycleTime" BO_ 2214592769 0;
BA_ "VFrameFormat" BO_ 2214592769 15;
BA_ "GenMsgDelayTime" BO_ 2214592783 10;
BA_ "GenMsgCycleTime" BO_ 2214592783 0;
BA_ "VFrameFormat" BO_ 2214592783 15;
BA_ "GenMsgSendType" BO_ 2281701456 0;
BA_ "VFrameFormat" BO_ 2281701456 15;
BA_ "GenMsgSendType" BO_ 2281701457 0;
BA_ "VFrameFormat" BO_ 2281701457 15;
BA_ "GenMsgDelayTime" BO_ 2683310089 10;
BA_ "GenMsgNrOfRepetition" BO_ 2683310089 0;
BA_ "GenMsgCycleTime" BO_ 2683310089 0;
BA_ "VFrameFormat" BO_ 2683310089 15;
BA_ "GenMsgDelayTime" BO_ 2214592786 10;
BA_ "GenMsgCycleTime" BO_ 2214592786 0;
BA_ "VFrameFormat" BO_ 2214592786 15;
BA_ "GenMsgCycleTime" BO_ 2214592785 0;
BA_ "VFrameFormat" BO_ 2214592785 15;
BA_ "GenMsgCycleTime" BO_ 2214592784 0;
BA_ "VFrameFormat" BO_ 2214592784 15;
BA_ "GenMsgDelayTime" BO_ 2214592799 10;
BA_ "GenMsgCycleTime" BO_ 2214592799 0;
BA_ "VFrameFormat" BO_ 2214592799 15;
BA_ "GenMsgDelayTime" BO_ 2683310087 10;
BA_ "GenMsgNrOfRepetition" BO_ 2683310087 0;
BA_ "GenMsgCycleTime" BO_ 2683310087 0;
BA_ "VFrameFormat" BO_ 2683310087 15;
BA_ "GenMsgDelayTime" BO_ 2533738497 10;
BA_ "GenMsgCycleTime" BO_ 2533738497 0;
BA_ "VFrameFormat" BO_ 2533738497 15;
BA_ "GenMsgDelayTime" BO_ 2529540097 10;
BA_ "GenMsgCycleTime" BO_ 2529540097 0;
BA_ "VFrameFormat" BO_ 2529540097 15;
BA_ "GenMsgCycleTime" BO_ 1337 500;
BA_ "GenMsgSendType" BO_ 1337 0;
BA_ "VFrameFormat" BO_ 1337 14;
BA_ "GenMsgCycleTime" BO_ 1336 500;
BA_ "GenMsgSendType" BO_ 1336 0;
BA_ "VFrameFormat" BO_ 1336 14;
BA_ "GenMsgStartDelayTime" BO_ 850 40;
BA_ "GenMsgSendType" BO_ 850 0;
BA_ "VFrameFormat" BO_ 850 14;
BA_ "TpTxIndex" BO_ 1821 183;
BA_ "TpMessage" BO_ 1821 1;
BA_ "GenMsgILSupport" BO_ 1821 0;
BA_ "DiagResponse" BO_ 1821 1;
BA_ "GenMsgNrOfRepetition" BO_ 1821 0;
BA_ "GenMsgCycleTimeFast" BO_ 1821 0;
BA_ "GenMsgCycleTime" BO_ 1821 0;
BA_ "VFrameFormat" BO_ 1821 14;
BA_ "Version" SG_ 830 SBCM_RL_FD_Crc1Val "22.10.20";
BA_ "UserSigValidity" SG_ 830 SBCM_RL_FD_Crc1Val 3;
BA_ "GenSigStartValue" SG_ 830 SBCM_RL_FD_Crc1Val 65535;
BA_ "GenSigSendType" SG_ 830 SBCM_RL_FD_Crc1Val 4;
BA_ "Description" SG_ 830 SBCM_RL_FD_Crc1Val "The data area for CRC calculation is based on the data length (DLC) of the message DB.

The CRC shall be calculated over the entire data block (excluding the CRC bytes) including the user data, alive counter and Data ID



- CRC Polynomial (0x1021) , Ini";
BA_ "Version" SG_ 830 USM_RLGhostDoorSta_Copy_0 "21.07.07";
BA_ "NetworkRequestHoldingTime" SG_ 830 USM_RLGhostDoorSta_Copy_0 5000;
BA_ "NetworkRequest" SG_ 830 USM_RLGhostDoorSta_Copy_0 0;
BA_ "UserSigValidity" SG_ 830 USM_RLGhostDoorSta_Copy_0 0;
BA_ "GenSigSendType" SG_ 830 USM_RLGhostDoorSta_Copy_0 4;
BA_ "Version" SG_ 830 DoorLock_PDSLkSwSta_RL_Copy_0 "21.09.05";
BA_ "NetworkRequest" SG_ 830 DoorLock_PDSLkSwSta_RL_Copy_0 0;
BA_ "UserSigValidity" SG_ 830 DoorLock_PDSLkSwSta_RL_Copy_0 0;
BA_ "GenSigSendType" SG_ 830 DoorLock_PDSLkSwSta_RL_Copy_0 4;
BA_ "Version" SG_ 830 PDS_TypeOption_RL_Copy_0 "21.07.07";
BA_ "NetworkRequest" SG_ 830 PDS_TypeOption_RL_Copy_0 0;
BA_ "UserSigValidity" SG_ 830 PDS_TypeOption_RL_Copy_0 0;
BA_ "GenSigSendType" SG_ 830 PDS_TypeOption_RL_Copy_0 4;
BA_ "Version" SG_ 830 RL_CrashMRActAlarm_Copy_0 "21.07.07";
BA_ "NetworkRequestHoldingTime" SG_ 830 RL_CrashMRActAlarm_Copy_0 5000;
BA_ "NetworkRequest" SG_ 830 RL_CrashMRActAlarm_Copy_0 0;
BA_ "UserSigValidity" SG_ 830 RL_CrashMRActAlarm_Copy_0 0;
BA_ "GenSigSendType" SG_ 830 RL_CrashMRActAlarm_Copy_0 4;
BA_ "Version" SG_ 830 PwrDRBuzzerOut_RL_Copy_0 "21.07.07";
BA_ "NetworkRequestHoldingTime" SG_ 830 PwrDRBuzzerOut_RL_Copy_0 5000;
BA_ "NetworkRequest" SG_ 830 PwrDRBuzzerOut_RL_Copy_0 0;
BA_ "UserSigValidity" SG_ 830 PwrDRBuzzerOut_RL_Copy_0 0;
BA_ "GenSigSendType" SG_ 830 PwrDRBuzzerOut_RL_Copy_0 4;
BA_ "Version" SG_ 830 PwrDRClosingRLDrSta_Copy_0 "23.07.06";
BA_ "NetworkRequestHoldingTime" SG_ 830 PwrDRClosingRLDrSta_Copy_0 5000;
BA_ "NetworkRequest" SG_ 830 PwrDRClosingRLDrSta_Copy_0 0;
BA_ "UserSigValidity" SG_ 830 PwrDRClosingRLDrSta_Copy_0 0;
BA_ "GenSigSendType" SG_ 830 PwrDRClosingRLDrSta_Copy_0 4;
BA_ "Version" SG_ 830 AFH_RL_FldUnfldSta_Copy_0 "24.07.06";
BA_ "NetworkRequestHoldingTime" SG_ 830 AFH_RL_FldUnfldSta_Copy_0 5000;
BA_ "NetworkRequest" SG_ 830 AFH_RL_FldUnfldSta_Copy_0 0;
BA_ "UserSigValidity" SG_ 830 AFH_RL_FldUnfldSta_Copy_0 0;
BA_ "GenSigSendType" SG_ 830 AFH_RL_FldUnfldSta_Copy_0 4;
BA_ "Version" SG_ 830 SBCM_RL_FD_AlvCnt1Val "22.10.20";
BA_ "UserSigValidity" SG_ 830 SBCM_RL_FD_AlvCnt1Val 3;
BA_ "GenSigSendType" SG_ 830 SBCM_RL_FD_AlvCnt1Val 4;
BA_ "Description" SG_ 830 SBCM_RL_FD_AlvCnt1Val "For the first transmission request for a data element the counter shall be initialized with 0 and shall be incremented by 1 for every subsequent send request. 

When the counter reaches the maximum value(0xFF), then it shall restart with 0 for the next s";
BA_ "Version" SG_ 830 DoorLock_RrLtLkOutSta_SBCM_Copy_ "23.02.09";
BA_ "NetworkRequestHoldingTime" SG_ 830 DoorLock_RrLtLkOutSta_SBCM_Copy_ 5000;
BA_ "NetworkRequest" SG_ 830 DoorLock_RrLtLkOutSta_SBCM_Copy_ 0;
BA_ "UserSigValidity" SG_ 830 DoorLock_RrLtLkOutSta_SBCM_Copy_ 0;
BA_ "GenSigSendType" SG_ 830 DoorLock_RrLtLkOutSta_SBCM_Copy_ 4;
BA_ "Description" SG_ 830 DoorLock_RrLtLkOutSta_SBCM_Copy_ "- Door Lock or Unlock Output State 

0x0 : Off (Door lock/unlock output Off state)

0x1 : On (Door lock/unlock output On state)";
BA_ "SystemSignalLongSymbol" SG_ 830 DoorLock_RrLtLkOutSta_SBCM_Copy_ "DoorLock_RrLtLkOutSta_SBCM_Copy_0";
BA_ "Version" SG_ 830 RrLt_DrLkRetryFail_SBCM_Copy_0 "23.03.00";
BA_ "NetworkRequestHoldingTime" SG_ 830 RrLt_DrLkRetryFail_SBCM_Copy_0 5000;
BA_ "NetworkRequest" SG_ 830 RrLt_DrLkRetryFail_SBCM_Copy_0 0;
BA_ "UserSigValidity" SG_ 830 RrLt_DrLkRetryFail_SBCM_Copy_0 0;
BA_ "TimeoutValue" SG_ 830 RrLt_DrLkRetryFail_SBCM_Copy_0 "0x0";
BA_ "GenSigSendType" SG_ 830 RrLt_DrLkRetryFail_SBCM_Copy_0 4;
BA_ "Version" SG_ 830 RL_DetectObj_warn "23.10.11";
BA_ "NetworkRequestHoldingTime" SG_ 830 RL_DetectObj_warn 5000;
BA_ "NetworkRequest" SG_ 830 RL_DetectObj_warn 0;
BA_ "UserSigValidity" SG_ 830 RL_DetectObj_warn 0;
BA_ "GenSigSendType" SG_ 830 RL_DetectObj_warn 4;
BA_ "Version" SG_ 830 RLRrDrCurtainPosition "23.07.06";
BA_ "NetworkRequestHoldingTime" SG_ 830 RLRrDrCurtainPosition 5000;
BA_ "NetworkRequest" SG_ 830 RLRrDrCurtainPosition 0;
BA_ "UserSigValidity" SG_ 830 RLRrDrCurtainPosition 0;
BA_ "GenSigSendType" SG_ 830 RLRrDrCurtainPosition 4;
BA_ "Version" SG_ 830 RDC_TypeOption "23.07.06";
BA_ "NetworkRequestHoldingTime" SG_ 830 RDC_TypeOption 5000;
BA_ "NetworkRequest" SG_ 830 RDC_TypeOption 0;
BA_ "UserSigValidity" SG_ 830 RDC_TypeOption 0;
BA_ "GenSigSendType" SG_ 830 RDC_TypeOption 4;
BA_ "Version" SG_ 830 RLRrDrCurtainDownInitState "24.01.05";
BA_ "NetworkRequestHoldingTime" SG_ 830 RLRrDrCurtainDownInitState 5000;
BA_ "NetworkRequest" SG_ 830 RLRrDrCurtainDownInitState 0;
BA_ "UserSigValidity" SG_ 830 RLRrDrCurtainDownInitState 0;
BA_ "GenSigSendType" SG_ 830 RLRrDrCurtainDownInitState 4;
BA_ "Version" SG_ 830 PwrDRBuzzerOut_RL_New "24.01.05";
BA_ "NetworkRequestHoldingTime" SG_ 830 PwrDRBuzzerOut_RL_New 5000;
BA_ "NetworkRequest" SG_ 830 PwrDRBuzzerOut_RL_New 0;
BA_ "UserSigValidity" SG_ 830 PwrDRBuzzerOut_RL_New 0;
BA_ "GenSigSendType" SG_ 830 PwrDRBuzzerOut_RL_New 4;
BA_ "Description" SG_ 830 PwrDRBuzzerOut_RL_New "JG~";
BA_ "Version" SG_ 830 PwrDrSta_RrLt "24.01.05";
BA_ "NetworkRequestHoldingTime" SG_ 830 PwrDrSta_RrLt 5000;
BA_ "NetworkRequest" SG_ 830 PwrDrSta_RrLt 0;
BA_ "UserSigValidity" SG_ 830 PwrDrSta_RrLt 0;
BA_ "GenSigSendType" SG_ 830 PwrDrSta_RrLt 4;
BA_ "Description" SG_ 830 PwrDrSta_RrLt "JG~";
BA_ "Version" SG_ 830 SBCM_RL_SlidePosition "24.01.05";
BA_ "NetworkRequestHoldingTime" SG_ 830 SBCM_RL_SlidePosition 5000;
BA_ "NetworkRequest" SG_ 830 SBCM_RL_SlidePosition 0;
BA_ "UserSigValidity" SG_ 830 SBCM_RL_SlidePosition 0;
BA_ "GenSigStartValue" SG_ 830 SBCM_RL_SlidePosition 255;
BA_ "GenSigSendType" SG_ 830 SBCM_RL_SlidePosition 4;
BA_ "Description" SG_ 830 SBCM_RL_SlidePosition "DHMC_RL_SlidePosition";
BA_ "Version" SG_ 830 SBCM_RL_DoorAngle "24.01.05";
BA_ "NetworkRequestHoldingTime" SG_ 830 SBCM_RL_DoorAngle 5000;
BA_ "NetworkRequest" SG_ 830 SBCM_RL_DoorAngle 0;
BA_ "UserSigValidity" SG_ 830 SBCM_RL_DoorAngle 0;
BA_ "GenSigStartValue" SG_ 830 SBCM_RL_DoorAngle 100;
BA_ "GenSigSendType" SG_ 830 SBCM_RL_DoorAngle 4;
BA_ "Description" SG_ 830 SBCM_RL_DoorAngle "PDSM_RL_DoorAngle";
BA_ "Version" SG_ 830 RLDoorPushAlarm_Copy_0 "21.07.07";
BA_ "NetworkRequestHoldingTime" SG_ 830 RLDoorPushAlarm_Copy_0 5000;
BA_ "NetworkRequest" SG_ 830 RLDoorPushAlarm_Copy_0 0;
BA_ "UserSigValidity" SG_ 830 RLDoorPushAlarm_Copy_0 0;
BA_ "GenSigSendType" SG_ 830 RLDoorPushAlarm_Copy_0 4;
BA_ "Version" SG_ 830 RL_CrashUnlockCmd_Copy_0 "21.07.07";
BA_ "NetworkRequest" SG_ 830 RL_CrashUnlockCmd_Copy_0 0;
BA_ "UserSigValidity" SG_ 830 RL_CrashUnlockCmd_Copy_0 0;
BA_ "GenSigSendType" SG_ 830 RL_CrashUnlockCmd_Copy_0 4;
BA_ "Description" SG_ 830 RL_CrashUnlockCmd_Copy_0 "RearLefrCrashUnlockCommand";
BA_ "Version" SG_ 830 Warn_RrLftDrSwSta_SBCM_Copy_0 "21.09.05";
BA_ "NetworkRequest" SG_ 830 Warn_RrLftDrSwSta_SBCM_Copy_0 0;
BA_ "UserSigValidity" SG_ 830 Warn_RrLftDrSwSta_SBCM_Copy_0 0;
BA_ "GenSigSendType" SG_ 830 Warn_RrLftDrSwSta_SBCM_Copy_0 4;
BA_ "Description" SG_ 830 Warn_RrLftDrSwSta_SBCM_Copy_0 "Warning Rear Left Door Switch Status";
BA_ "Version" SG_ 830 DoorLock_RrLftDrUnLkSta_SBCM_Cop "21.07.07";
BA_ "NetworkRequest" SG_ 830 DoorLock_RrLftDrUnLkSta_SBCM_Cop 0;
BA_ "UserSigValidity" SG_ 830 DoorLock_RrLftDrUnLkSta_SBCM_Cop 0;
BA_ "GenSigSendType" SG_ 830 DoorLock_RrLftDrUnLkSta_SBCM_Cop 4;
BA_ "Description" SG_ 830 DoorLock_RrLftDrUnLkSta_SBCM_Cop "Rear Left Door Unlock Status";
BA_ "SystemSignalLongSymbol" SG_ 830 DoorLock_RrLftDrUnLkSta_SBCM_Cop "DoorLock_RrLftDrUnLkSta_SBCM_Copy_0";
BA_ "Version" SG_ 830 RL_SEAActivated_Copy_0 "21.07.07";
BA_ "NetworkRequest" SG_ 830 RL_SEAActivated_Copy_0 0;
BA_ "UserSigValidity" SG_ 830 RL_SEAActivated_Copy_0 0;
BA_ "GenSigSendType" SG_ 830 RL_SEAActivated_Copy_0 4;
BA_ "Description" SG_ 830 RL_SEAActivated_Copy_0 "Rear Left SEA Activated";
BA_ "Version" SG_ 830 RL_SEAWarn_Copy_0 "21.07.07";
BA_ "NetworkRequest" SG_ 830 RL_SEAWarn_Copy_0 0;
BA_ "UserSigValidity" SG_ 830 RL_SEAWarn_Copy_0 0;
BA_ "GenSigSendType" SG_ 830 RL_SEAWarn_Copy_0 4;
BA_ "Description" SG_ 830 RL_SEAWarn_Copy_0 "RearLeftSEAWarning";
BA_ "Version" SG_ 830 RL_SEWWarn_Copy_0 "21.07.07";
BA_ "NetworkRequest" SG_ 830 RL_SEWWarn_Copy_0 0;
BA_ "UserSigValidity" SG_ 830 RL_SEWWarn_Copy_0 0;
BA_ "GenSigSendType" SG_ 830 RL_SEWWarn_Copy_0 4;
BA_ "Version" SG_ 830 RL_ReleaseWarn_Copy_0 "21.09.05";
BA_ "NetworkRequestHoldingTime" SG_ 830 RL_ReleaseWarn_Copy_0 5000;
BA_ "NetworkRequest" SG_ 830 RL_ReleaseWarn_Copy_0 0;
BA_ "UserSigValidity" SG_ 830 RL_ReleaseWarn_Copy_0 0;
BA_ "GenSigSendType" SG_ 830 RL_ReleaseWarn_Copy_0 4;
BA_ "Version" SG_ 830 RL_SWFailAlarm_Copy_0 "21.07.07";
BA_ "NetworkRequestHoldingTime" SG_ 830 RL_SWFailAlarm_Copy_0 5000;
BA_ "NetworkRequest" SG_ 830 RL_SWFailAlarm_Copy_0 0;
BA_ "UserSigValidity" SG_ 830 RL_SWFailAlarm_Copy_0 0;
BA_ "GenSigSendType" SG_ 830 RL_SWFailAlarm_Copy_0 4;
BA_ "Version" SG_ 830 RL_ChildLock_ActnFlSta_Copy_0 "21.07.07";
BA_ "NetworkRequestHoldingTime" SG_ 830 RL_ChildLock_ActnFlSta_Copy_0 5000;
BA_ "NetworkRequest" SG_ 830 RL_ChildLock_ActnFlSta_Copy_0 0;
BA_ "UserSigValidity" SG_ 830 RL_ChildLock_ActnFlSta_Copy_0 0;
BA_ "GenSigSendType" SG_ 830 RL_ChildLock_ActnFlSta_Copy_0 4;
BA_ "Version" SG_ 830 RL_MRActivationAlarm_Copy_0 "21.07.07";
BA_ "NetworkRequestHoldingTime" SG_ 830 RL_MRActivationAlarm_Copy_0 5000;
BA_ "NetworkRequest" SG_ 830 RL_MRActivationAlarm_Copy_0 0;
BA_ "UserSigValidity" SG_ 830 RL_MRActivationAlarm_Copy_0 0;
BA_ "GenSigSendType" SG_ 830 RL_MRActivationAlarm_Copy_0 4;
BA_ "Version" SG_ 830 RL_ChildLock_Status_Copy_0 "21.07.07";
BA_ "NetworkRequestHoldingTime" SG_ 830 RL_ChildLock_Status_Copy_0 5000;
BA_ "NetworkRequest" SG_ 830 RL_ChildLock_Status_Copy_0 0;
BA_ "UserSigValidity" SG_ 830 RL_ChildLock_Status_Copy_0 0;
BA_ "GenSigSendType" SG_ 830 RL_ChildLock_Status_Copy_0 4;
BA_ "Version" SG_ 813 SBCM_DRV_FD_Crc1Val "22.10.20";
BA_ "UserSigValidity" SG_ 813 SBCM_DRV_FD_Crc1Val 3;
BA_ "GenSigStartValue" SG_ 813 SBCM_DRV_FD_Crc1Val 65535;
BA_ "GenSigSendType" SG_ 813 SBCM_DRV_FD_Crc1Val 4;
BA_ "Description" SG_ 813 SBCM_DRV_FD_Crc1Val "The data area for CRC calculation is based on the data length (DLC) of the message DB.

The CRC shall be calculated over the entire data block (excluding the CRC bytes) including the user data, alive counter and Data ID



- CRC Polynomial (0x1021) , Ini";
BA_ "Version" SG_ 813 Latch_TypeOption_DRV_Copy_0 "21.07.07";
BA_ "NetworkRequest" SG_ 813 Latch_TypeOption_DRV_Copy_0 0;
BA_ "UserSigValidity" SG_ 813 Latch_TypeOption_DRV_Copy_0 0;
BA_ "GenSigSendType" SG_ 813 Latch_TypeOption_DRV_Copy_0 4;
BA_ "Description" SG_ 813 Latch_TypeOption_DRV_Copy_0 "If the E-Lacth is applied, the signal will be send for identify the door lock/unlock function and option.";
BA_ "Version" SG_ 813 DRV_SWFailAlarm_Copy_0 "21.07.07";
BA_ "NetworkRequestHoldingTime" SG_ 813 DRV_SWFailAlarm_Copy_0 5000;
BA_ "NetworkRequest" SG_ 813 DRV_SWFailAlarm_Copy_0 0;
BA_ "UserSigValidity" SG_ 813 DRV_SWFailAlarm_Copy_0 0;
BA_ "GenSigSendType" SG_ 813 DRV_SWFailAlarm_Copy_0 4;
BA_ "Version" SG_ 813 USM_PwrDRApprOpnSetSta_Copy_0 "21.07.07";
BA_ "NetworkRequestHoldingTime" SG_ 813 USM_PwrDRApprOpnSetSta_Copy_0 5000;
BA_ "NetworkRequest" SG_ 813 USM_PwrDRApprOpnSetSta_Copy_0 0;
BA_ "UserSigValidity" SG_ 813 USM_PwrDRApprOpnSetSta_Copy_0 0;
BA_ "GenSigSendType" SG_ 813 USM_PwrDRApprOpnSetSta_Copy_0 4;
BA_ "Version" SG_ 813 USM_PwrDRApprOpnSetOpt_Copy_0 "21.07.07";
BA_ "NetworkRequestHoldingTime" SG_ 813 USM_PwrDRApprOpnSetOpt_Copy_0 5000;
BA_ "NetworkRequest" SG_ 813 USM_PwrDRApprOpnSetOpt_Copy_0 0;
BA_ "UserSigValidity" SG_ 813 USM_PwrDRApprOpnSetOpt_Copy_0 0;
BA_ "GenSigSendType" SG_ 813 USM_PwrDRApprOpnSetOpt_Copy_0 4;
BA_ "Version" SG_ 813 USM_PwrDRCloseByRKELockSta_Copy_ "22.10.01";
BA_ "NetworkRequestHoldingTime" SG_ 813 USM_PwrDRCloseByRKELockSta_Copy_ 5000;
BA_ "NetworkRequest" SG_ 813 USM_PwrDRCloseByRKELockSta_Copy_ 0;
BA_ "UserSigValidity" SG_ 813 USM_PwrDRCloseByRKELockSta_Copy_ 0;
BA_ "GenSigSendType" SG_ 813 USM_PwrDRCloseByRKELockSta_Copy_ 4;
BA_ "SystemSignalLongSymbol" SG_ 813 USM_PwrDRCloseByRKELockSta_Copy_ "USM_PwrDRCloseByRKELockSta_Copy_0";
BA_ "Version" SG_ 813 USM_PwrDRCloseByRKELockOpt_Copy_ "22.10.01";
BA_ "NetworkRequestHoldingTime" SG_ 813 USM_PwrDRCloseByRKELockOpt_Copy_ 5000;
BA_ "NetworkRequest" SG_ 813 USM_PwrDRCloseByRKELockOpt_Copy_ 0;
BA_ "UserSigValidity" SG_ 813 USM_PwrDRCloseByRKELockOpt_Copy_ 0;
BA_ "GenSigSendType" SG_ 813 USM_PwrDRCloseByRKELockOpt_Copy_ 4;
BA_ "SystemSignalLongSymbol" SG_ 813 USM_PwrDRCloseByRKELockOpt_Copy_ "USM_PwrDRCloseByRKELockOpt_Copy_0";
BA_ "Version" SG_ 813 USM_PwrDRCloseByBrakeSta_Copy_0 "21.07.07";
BA_ "NetworkRequestHoldingTime" SG_ 813 USM_PwrDRCloseByBrakeSta_Copy_0 5000;
BA_ "NetworkRequest" SG_ 813 USM_PwrDRCloseByBrakeSta_Copy_0 0;
BA_ "UserSigValidity" SG_ 813 USM_PwrDRCloseByBrakeSta_Copy_0 0;
BA_ "GenSigSendType" SG_ 813 USM_PwrDRCloseByBrakeSta_Copy_0 4;
BA_ "Version" SG_ 813 USM_PwrDRCloseByBrakeOpt_Copy_0 "21.07.07";
BA_ "NetworkRequestHoldingTime" SG_ 813 USM_PwrDRCloseByBrakeOpt_Copy_0 5000;
BA_ "NetworkRequest" SG_ 813 USM_PwrDRCloseByBrakeOpt_Copy_0 0;
BA_ "UserSigValidity" SG_ 813 USM_PwrDRCloseByBrakeOpt_Copy_0 0;
BA_ "GenSigSendType" SG_ 813 USM_PwrDRCloseByBrakeOpt_Copy_0 4;
BA_ "Version" SG_ 813 USM_PwrDRBuzzerSta_Copy_0 "21.07.07";
BA_ "NetworkRequestHoldingTime" SG_ 813 USM_PwrDRBuzzerSta_Copy_0 5000;
BA_ "NetworkRequest" SG_ 813 USM_PwrDRBuzzerSta_Copy_0 0;
BA_ "UserSigValidity" SG_ 813 USM_PwrDRBuzzerSta_Copy_0 0;
BA_ "GenSigSendType" SG_ 813 USM_PwrDRBuzzerSta_Copy_0 4;
BA_ "Version" SG_ 813 USM_PwrDRBuzzerOpt_Copy_0 "21.07.07";
BA_ "NetworkRequestHoldingTime" SG_ 813 USM_PwrDRBuzzerOpt_Copy_0 5000;
BA_ "NetworkRequest" SG_ 813 USM_PwrDRBuzzerOpt_Copy_0 0;
BA_ "UserSigValidity" SG_ 813 USM_PwrDRBuzzerOpt_Copy_0 0;
BA_ "GenSigSendType" SG_ 813 USM_PwrDRBuzzerOpt_Copy_0 4;
BA_ "Version" SG_ 813 PDS_TypeOption_DRV_Copy_0 "23.04.02";
BA_ "NetworkRequest" SG_ 813 PDS_TypeOption_DRV_Copy_0 0;
BA_ "UserSigValidity" SG_ 813 PDS_TypeOption_DRV_Copy_0 0;
BA_ "GenSigSendType" SG_ 813 PDS_TypeOption_DRV_Copy_0 4;
BA_ "Version" SG_ 813 C_DrvDoorApproachOpen_Copy_0 "21.07.07";
BA_ "UserSigValidity" SG_ 813 C_DrvDoorApproachOpen_Copy_0 0;
BA_ "GenSigSendType" SG_ 813 C_DrvDoorApproachOpen_Copy_0 4;
BA_ "Description" SG_ 813 C_DrvDoorApproachOpen_Copy_0 "Fob searching start and stop signal for PDS.";
BA_ "Version" SG_ 813 C_DrvDoorApproachClose_Copy_0 "21.07.07";
BA_ "UserSigValidity" SG_ 813 C_DrvDoorApproachClose_Copy_0 0;
BA_ "GenSigSendType" SG_ 813 C_DrvDoorApproachClose_Copy_0 4;
BA_ "Description" SG_ 813 C_DrvDoorApproachClose_Copy_0 "To close the door automatically, request the fob searching signal";
BA_ "Version" SG_ 813 DoorLock_PDSLkSwSta_DRV_Copy_0 "21.07.07";
BA_ "NetworkRequest" SG_ 813 DoorLock_PDSLkSwSta_DRV_Copy_0 0;
BA_ "UserSigValidity" SG_ 813 DoorLock_PDSLkSwSta_DRV_Copy_0 0;
BA_ "GenSigSendType" SG_ 813 DoorLock_PDSLkSwSta_DRV_Copy_0 4;
BA_ "Version" SG_ 813 SBCM_DRV_DiagSta_Copy_0 "21.07.07";
BA_ "NetworkRequestHoldingTime" SG_ 813 SBCM_DRV_DiagSta_Copy_0 5000;
BA_ "NetworkRequest" SG_ 813 SBCM_DRV_DiagSta_Copy_0 0;
BA_ "UserSigValidity" SG_ 813 SBCM_DRV_DiagSta_Copy_0 0;
BA_ "GenSigSendType" SG_ 813 SBCM_DRV_DiagSta_Copy_0 4;
BA_ "Version" SG_ 813 DoorLock_CtrlDrLkUnLkSwSta_SBCM_ "21.07.07";
BA_ "NetworkRequestHoldingTime" SG_ 813 DoorLock_CtrlDrLkUnLkSwSta_SBCM_ 5000;
BA_ "NetworkRequest" SG_ 813 DoorLock_CtrlDrLkUnLkSwSta_SBCM_ 0;
BA_ "UserSigValidity" SG_ 813 DoorLock_CtrlDrLkUnLkSwSta_SBCM_ 0;
BA_ "GenSigSendType" SG_ 813 DoorLock_CtrlDrLkUnLkSwSta_SBCM_ 4;
BA_ "Description" SG_ 813 DoorLock_CtrlDrLkUnLkSwSta_SBCM_ "Central Door Lock/Unlock Switch State";
BA_ "SystemSignalLongSymbol" SG_ 813 DoorLock_CtrlDrLkUnLkSwSta_SBCM_ "DoorLock_CtrlDrLkUnLkSwSta_SBCM_Copy_0";
BA_ "Version" SG_ 813 SBCM_PsvDrLkReq_Copy_0 "21.07.07";
BA_ "NetworkRequest" SG_ 813 SBCM_PsvDrLkReq_Copy_0 0;
BA_ "UserSigValidity" SG_ 813 SBCM_PsvDrLkReq_Copy_0 0;
BA_ "GenSigSendType" SG_ 813 SBCM_PsvDrLkReq_Copy_0 4;
BA_ "Version" SG_ 813 CDMAutoWashModeSet_SBCM_Copy_0 "22.07.00";
BA_ "UserSigValidity" SG_ 813 CDMAutoWashModeSet_SBCM_Copy_0 3;
BA_ "GenSigSendType" SG_ 813 CDMAutoWashModeSet_SBCM_Copy_0 4;
BA_ "Version" SG_ 813 USM_DrvGhostDoorSta_Copy_0 "21.07.07";
BA_ "NetworkRequestHoldingTime" SG_ 813 USM_DrvGhostDoorSta_Copy_0 5000;
BA_ "NetworkRequest" SG_ 813 USM_DrvGhostDoorSta_Copy_0 0;
BA_ "UserSigValidity" SG_ 813 USM_DrvGhostDoorSta_Copy_0 0;
BA_ "GenSigSendType" SG_ 813 USM_DrvGhostDoorSta_Copy_0 4;
BA_ "Version" SG_ 813 Mirror_LH_FoldingSta_Copy_0 "21.07.07";
BA_ "NetworkRequestHoldingTime" SG_ 813 Mirror_LH_FoldingSta_Copy_0 5000;
BA_ "NetworkRequest" SG_ 813 Mirror_LH_FoldingSta_Copy_0 0;
BA_ "UserSigValidity" SG_ 813 Mirror_LH_FoldingSta_Copy_0 0;
BA_ "GenSigSendType" SG_ 813 Mirror_LH_FoldingSta_Copy_0 4;
BA_ "Version" SG_ 813 Mirror_LH_UnfoldingSta_Copy_0 "21.07.07";
BA_ "NetworkRequestHoldingTime" SG_ 813 Mirror_LH_UnfoldingSta_Copy_0 5000;
BA_ "NetworkRequest" SG_ 813 Mirror_LH_UnfoldingSta_Copy_0 0;
BA_ "UserSigValidity" SG_ 813 Mirror_LH_UnfoldingSta_Copy_0 0;
BA_ "GenSigSendType" SG_ 813 Mirror_LH_UnfoldingSta_Copy_0 4;
BA_ "Version" SG_ 813 DRV_CrashMRActAlarm_Copy_0 "21.07.07";
BA_ "NetworkRequestHoldingTime" SG_ 813 DRV_CrashMRActAlarm_Copy_0 5000;
BA_ "NetworkRequest" SG_ 813 DRV_CrashMRActAlarm_Copy_0 0;
BA_ "UserSigValidity" SG_ 813 DRV_CrashMRActAlarm_Copy_0 0;
BA_ "GenSigSendType" SG_ 813 DRV_CrashMRActAlarm_Copy_0 4;
BA_ "Version" SG_ 813 AFH_DRV_FldUnFldSta_Copy_0 "24.07.06";
BA_ "NetworkRequestHoldingTime" SG_ 813 AFH_DRV_FldUnFldSta_Copy_0 5000;
BA_ "NetworkRequest" SG_ 813 AFH_DRV_FldUnFldSta_Copy_0 0;
BA_ "UserSigValidity" SG_ 813 AFH_DRV_FldUnFldSta_Copy_0 0;
BA_ "GenSigSendType" SG_ 813 AFH_DRV_FldUnFldSta_Copy_0 4;
BA_ "Version" SG_ 813 SBCM_DRV_FD_AlvCnt1Val "22.10.20";
BA_ "UserSigValidity" SG_ 813 SBCM_DRV_FD_AlvCnt1Val 3;
BA_ "GenSigSendType" SG_ 813 SBCM_DRV_FD_AlvCnt1Val 4;
BA_ "Description" SG_ 813 SBCM_DRV_FD_AlvCnt1Val "For the first transmission request for a data element the counter shall be initialized with 0 and shall be incremented by 1 for every subsequent send request. 

When the counter reaches the maximum value(0xFF), then it shall restart with 0 for the next s";
BA_ "Version" SG_ 813 MirrorFldReq_Copy_0 "21.07.07";
BA_ "NetworkRequestHoldingTime" SG_ 813 MirrorFldReq_Copy_0 5000;
BA_ "NetworkRequest" SG_ 813 MirrorFldReq_Copy_0 0;
BA_ "UserSigValidity" SG_ 813 MirrorFldReq_Copy_0 0;
BA_ "GenSigSendType" SG_ 813 MirrorFldReq_Copy_0 4;
BA_ "Version" SG_ 813 OMU_TypeOption_DRV_Copy_0 "21.07.07";
BA_ "NetworkRequestHoldingTime" SG_ 813 OMU_TypeOption_DRV_Copy_0 5000;
BA_ "NetworkRequest" SG_ 813 OMU_TypeOption_DRV_Copy_0 0;
BA_ "UserSigValidity" SG_ 813 OMU_TypeOption_DRV_Copy_0 0;
BA_ "GenSigSendType" SG_ 813 OMU_TypeOption_DRV_Copy_0 4;
BA_ "Version" SG_ 813 IMS_OSMirPlayBackSta_LH_Copy_0 "21.07.07";
BA_ "NetworkRequestHoldingTime" SG_ 813 IMS_OSMirPlayBackSta_LH_Copy_0 5000;
BA_ "NetworkRequest" SG_ 813 IMS_OSMirPlayBackSta_LH_Copy_0 0;
BA_ "UserSigValidity" SG_ 813 IMS_OSMirPlayBackSta_LH_Copy_0 0;
BA_ "GenSigSendType" SG_ 813 IMS_OSMirPlayBackSta_LH_Copy_0 4;
BA_ "Version" SG_ 813 ECMMRR_PLUS_Copy_0 "21.07.07";
BA_ "NetworkRequestHoldingTime" SG_ 813 ECMMRR_PLUS_Copy_0 5000;
BA_ "NetworkRequest" SG_ 813 ECMMRR_PLUS_Copy_0 0;
BA_ "UserSigValidity" SG_ 813 ECMMRR_PLUS_Copy_0 0;
BA_ "GenSigSendType" SG_ 813 ECMMRR_PLUS_Copy_0 4;
BA_ "Description" SG_ 813 ECMMRR_PLUS_Copy_0 "This signal for passenger outside mirror OEC function(or ECM)

SBCM_DRV receive the ECM voltage value via H/wiring and then send this signal to SBCM_AST";
BA_ "Version" SG_ 813 EHL_TxInfo_SBCM_DRV_Copy_0 "24.07.03";
BA_ "NetworkRequestHoldingTime" SG_ 813 EHL_TxInfo_SBCM_DRV_Copy_0 5000;
BA_ "NetworkRequest" SG_ 813 EHL_TxInfo_SBCM_DRV_Copy_0 0;
BA_ "UserSigValidity" SG_ 813 EHL_TxInfo_SBCM_DRV_Copy_0 0;
BA_ "GenSigSendType" SG_ 813 EHL_TxInfo_SBCM_DRV_Copy_0 4;
BA_ "Description" SG_ 813 EHL_TxInfo_SBCM_DRV_Copy_0 "Electronic hood latch status signal transfer for dual hood latch type

(Copy to CANFD)";
BA_ "Version" SG_ 813 IMS_OSMirPlayBackSta_LH_New_Copy "23.01.03";
BA_ "NetworkRequestHoldingTime" SG_ 813 IMS_OSMirPlayBackSta_LH_New_Copy 5000;
BA_ "NetworkRequest" SG_ 813 IMS_OSMirPlayBackSta_LH_New_Copy 0;
BA_ "UserSigValidity" SG_ 813 IMS_OSMirPlayBackSta_LH_New_Copy 0;
BA_ "GenSigSendType" SG_ 813 IMS_OSMirPlayBackSta_LH_New_Copy 4;
BA_ "Description" SG_ 813 IMS_OSMirPlayBackSta_LH_New_Copy "Applied from standard DB 2.0";
BA_ "SystemSignalLongSymbol" SG_ 813 IMS_OSMirPlayBackSta_LH_New_Copy "IMS_OSMirPlayBackSta_LH_New_Copy_0";
BA_ "Version" SG_ 813 CDM_InsideOpnSwSta_Copy_0 "23.04.05";
BA_ "NetworkRequestHoldingTime" SG_ 813 CDM_InsideOpnSwSta_Copy_0 5000;
BA_ "NetworkRequest" SG_ 813 CDM_InsideOpnSwSta_Copy_0 0;
BA_ "UserSigValidity" SG_ 813 CDM_InsideOpnSwSta_Copy_0 0;
BA_ "GenSigSendType" SG_ 813 CDM_InsideOpnSwSta_Copy_0 4;
BA_ "Version" SG_ 813 CDM_TypeOption_Copy_0 "23.04.02";
BA_ "NetworkRequestHoldingTime" SG_ 813 CDM_TypeOption_Copy_0 5000;
BA_ "NetworkRequest" SG_ 813 CDM_TypeOption_Copy_0 0;
BA_ "UserSigValidity" SG_ 813 CDM_TypeOption_Copy_0 0;
BA_ "GenSigSendType" SG_ 813 CDM_TypeOption_Copy_0 4;
BA_ "Description" SG_ 813 CDM_TypeOption_Copy_0 "0x1 : On (CDM is applied)

0x2 : On_2EA (CDM 2EA are applied)";
BA_ "Version" SG_ 813 CDM_ImmeChgSw_SBCM_Copy_0 "23.04.05";
BA_ "UserSigValidity" SG_ 813 CDM_ImmeChgSw_SBCM_Copy_0 0;
BA_ "GenSigSendType" SG_ 813 CDM_ImmeChgSw_SBCM_Copy_0 4;
BA_ "Description" SG_ 813 CDM_ImmeChgSw_SBCM_Copy_0 "State of Immediate Charging Switch";
BA_ "Version" SG_ 813 CDM_FobSrchReq_DRV_Copy_0 "24.05.03";
BA_ "NetworkRequestHoldingTime" SG_ 813 CDM_FobSrchReq_DRV_Copy_0 5000;
BA_ "NetworkRequest" SG_ 813 CDM_FobSrchReq_DRV_Copy_0 0;
BA_ "UserSigValidity" SG_ 813 CDM_FobSrchReq_DRV_Copy_0 0;
BA_ "GenSigSendType" SG_ 813 CDM_FobSrchReq_DRV_Copy_0 4;
BA_ "Version" SG_ 813 CDM_OpnClsState_SBCM_Copy_0 "23.04.05";
BA_ "UserSigValidity" SG_ 813 CDM_OpnClsState_SBCM_Copy_0 0;
BA_ "GenSigSendType" SG_ 813 CDM_OpnClsState_SBCM_Copy_0 4;
BA_ "Description" SG_ 813 CDM_OpnClsState_SBCM_Copy_0 "This signal indicates CDM Open/Close Status";
BA_ "Version" SG_ 813 CDM_WarnMsg_SBCM_Copy_0 "23.04.05";
BA_ "UserSigValidity" SG_ 813 CDM_WarnMsg_SBCM_Copy_0 0;
BA_ "GenSigSendType" SG_ 813 CDM_WarnMsg_SBCM_Copy_0 4;
BA_ "Description" SG_ 813 CDM_WarnMsg_SBCM_Copy_0 "Command for CDM Warning on cluster";
BA_ "Version" SG_ 813 CDM_AutoWashModeSta_Copy_0 "22.02.00";
BA_ "NetworkRequestHoldingTime" SG_ 813 CDM_AutoWashModeSta_Copy_0 5000;
BA_ "NetworkRequest" SG_ 813 CDM_AutoWashModeSta_Copy_0 0;
BA_ "UserSigValidity" SG_ 813 CDM_AutoWashModeSta_Copy_0 0;
BA_ "GenSigSendType" SG_ 813 CDM_AutoWashModeSta_Copy_0 4;
BA_ "Version" SG_ 813 CDM_CmdStatus_SBCM_Copy_0 "23.04.05";
BA_ "UserSigValidity" SG_ 813 CDM_CmdStatus_SBCM_Copy_0 0;
BA_ "GenSigStartValue" SG_ 813 CDM_CmdStatus_SBCM_Copy_0 15;
BA_ "GenSigSendType" SG_ 813 CDM_CmdStatus_SBCM_Copy_0 4;
BA_ "Description" SG_ 813 CDM_CmdStatus_SBCM_Copy_0 "User Condition Check For CDM Operation";
BA_ "Version" SG_ 813 CDM_OutsideOpnSwSta_Copy_0 "23.04.05";
BA_ "NetworkRequestHoldingTime" SG_ 813 CDM_OutsideOpnSwSta_Copy_0 5000;
BA_ "NetworkRequest" SG_ 813 CDM_OutsideOpnSwSta_Copy_0 0;
BA_ "UserSigValidity" SG_ 813 CDM_OutsideOpnSwSta_Copy_0 0;
BA_ "GenSigSendType" SG_ 813 CDM_OutsideOpnSwSta_Copy_0 4;
BA_ "Description" SG_ 813 CDM_OutsideOpnSwSta_Copy_0 "Charing Dorr O/S SW State";
BA_ "Version" SG_ 813 PwrDRBuzzerOut_DRV_Copy_0 "21.07.07";
BA_ "NetworkRequestHoldingTime" SG_ 813 PwrDRBuzzerOut_DRV_Copy_0 5000;
BA_ "NetworkRequest" SG_ 813 PwrDRBuzzerOut_DRV_Copy_0 0;
BA_ "UserSigValidity" SG_ 813 PwrDRBuzzerOut_DRV_Copy_0 0;
BA_ "GenSigSendType" SG_ 813 PwrDRBuzzerOut_DRV_Copy_0 4;
BA_ "Version" SG_ 813 Warn_HoodSwSta_SBCM_Copy_0 "21.09.08";
BA_ "NetworkRequestHoldingTime" SG_ 813 Warn_HoodSwSta_SBCM_Copy_0 5000;
BA_ "NetworkRequest" SG_ 813 Warn_HoodSwSta_SBCM_Copy_0 0;
BA_ "UserSigValidity" SG_ 813 Warn_HoodSwSta_SBCM_Copy_0 0;
BA_ "GenSigSendType" SG_ 813 Warn_HoodSwSta_SBCM_Copy_0 4;
BA_ "Version" SG_ 813 Hood_TypeOption_Copy_0 "22.03.01";
BA_ "NetworkRequestHoldingTime" SG_ 813 Hood_TypeOption_Copy_0 5000;
BA_ "NetworkRequest" SG_ 813 Hood_TypeOption_Copy_0 0;
BA_ "UserSigValidity" SG_ 813 Hood_TypeOption_Copy_0 0;
BA_ "GenSigSendType" SG_ 813 Hood_TypeOption_Copy_0 4;
BA_ "Description" SG_ 813 Hood_TypeOption_Copy_0 "If the E-Hood is applied, the signal will be send.";
BA_ "Version" SG_ 813 SBCM_FrunkSta_Copy_0 "22.01.06";
BA_ "NetworkRequestHoldingTime" SG_ 813 SBCM_FrunkSta_Copy_0 5000;
BA_ "NetworkRequest" SG_ 813 SBCM_FrunkSta_Copy_0 0;
BA_ "UserSigValidity" SG_ 813 SBCM_FrunkSta_Copy_0 0;
BA_ "GenSigSendType" SG_ 813 SBCM_FrunkSta_Copy_0 4;
BA_ "Version" SG_ 813 Warn_HoodSwFullSta_SBCM_Copy_0 "22.01.06";
BA_ "NetworkRequestHoldingTime" SG_ 813 Warn_HoodSwFullSta_SBCM_Copy_0 5000;
BA_ "NetworkRequest" SG_ 813 Warn_HoodSwFullSta_SBCM_Copy_0 0;
BA_ "UserSigValidity" SG_ 813 Warn_HoodSwFullSta_SBCM_Copy_0 0;
BA_ "GenSigSendType" SG_ 813 Warn_HoodSwFullSta_SBCM_Copy_0 4;
BA_ "Version" SG_ 813 FrunkWarning_SBCM_Copy_0 "22.03.01";
BA_ "NetworkRequestHoldingTime" SG_ 813 FrunkWarning_SBCM_Copy_0 5000;
BA_ "NetworkRequest" SG_ 813 FrunkWarning_SBCM_Copy_0 0;
BA_ "UserSigValidity" SG_ 813 FrunkWarning_SBCM_Copy_0 0;
BA_ "GenSigSendType" SG_ 813 FrunkWarning_SBCM_Copy_0 4;
BA_ "Version" SG_ 813 SBCM_Longkey_DRVDrAtClsSwSta_Cop "22.04.02";
BA_ "NetworkRequestHoldingTime" SG_ 813 SBCM_Longkey_DRVDrAtClsSwSta_Cop 5000;
BA_ "NetworkRequest" SG_ 813 SBCM_Longkey_DRVDrAtClsSwSta_Cop 0;
BA_ "UserSigValidity" SG_ 813 SBCM_Longkey_DRVDrAtClsSwSta_Cop 0;
BA_ "GenSigSendType" SG_ 813 SBCM_Longkey_DRVDrAtClsSwSta_Cop 4;
BA_ "Description" SG_ 813 SBCM_Longkey_DRVDrAtClsSwSta_Cop "FCS Power Door Long key Status";
BA_ "SystemSignalLongSymbol" SG_ 813 SBCM_Longkey_DRVDrAtClsSwSta_Cop "SBCM_Longkey_DRVDrAtClsSwSta_Copy_0";
BA_ "Version" SG_ 813 FrunkReleaseSwSta_SBCM "23.04.04";
BA_ "NetworkRequestHoldingTime" SG_ 813 FrunkReleaseSwSta_SBCM 50000;
BA_ "NetworkRequest" SG_ 813 FrunkReleaseSwSta_SBCM 0;
BA_ "UserSigValidity" SG_ 813 FrunkReleaseSwSta_SBCM 0;
BA_ "GenSigSendType" SG_ 813 FrunkReleaseSwSta_SBCM 4;
BA_ "Description" SG_ 813 FrunkReleaseSwSta_SBCM "FrunkReleaseState";
BA_ "Version" SG_ 813 PwrDRClosingDRVDrSta_Copy_0 "23.10.11";
BA_ "NetworkRequestHoldingTime" SG_ 813 PwrDRClosingDRVDrSta_Copy_0 5000;
BA_ "NetworkRequest" SG_ 813 PwrDRClosingDRVDrSta_Copy_0 0;
BA_ "UserSigValidity" SG_ 813 PwrDRClosingDRVDrSta_Copy_0 0;
BA_ "GenSigSendType" SG_ 813 PwrDRClosingDRVDrSta_Copy_0 4;
BA_ "Version" SG_ 813 Drv_DrLkRetryFail_SBCM_Copy_0 "23.03.00";
BA_ "NetworkRequestHoldingTime" SG_ 813 Drv_DrLkRetryFail_SBCM_Copy_0 5000;
BA_ "NetworkRequest" SG_ 813 Drv_DrLkRetryFail_SBCM_Copy_0 0;
BA_ "UserSigValidity" SG_ 813 Drv_DrLkRetryFail_SBCM_Copy_0 0;
BA_ "TimeoutValue" SG_ 813 Drv_DrLkRetryFail_SBCM_Copy_0 "0x0";
BA_ "GenSigSendType" SG_ 813 Drv_DrLkRetryFail_SBCM_Copy_0 4;
BA_ "Version" SG_ 813 CDM_GbtImmeChgSw_SBCM_Copy_0 "23.04.02";
BA_ "UserSigValidity" SG_ 813 CDM_GbtImmeChgSw_SBCM_Copy_0 0;
BA_ "GenSigSendType" SG_ 813 CDM_GbtImmeChgSw_SBCM_Copy_0 4;
BA_ "Description" SG_ 813 CDM_GbtImmeChgSw_SBCM_Copy_0 "State of Immediate Charging Switch";
BA_ "Version" SG_ 813 CDM_GbtOpnClsState_SBCM_Copy_0 "23.04.02";
BA_ "UserSigValidity" SG_ 813 CDM_GbtOpnClsState_SBCM_Copy_0 0;
BA_ "GenSigSendType" SG_ 813 CDM_GbtOpnClsState_SBCM_Copy_0 4;
BA_ "Description" SG_ 813 CDM_GbtOpnClsState_SBCM_Copy_0 "This signal indicates CDM Open/Close Status(Gbt)";
BA_ "Version" SG_ 813 CDM_GbtWarnMsg_SBCM_Copy_0 "23.04.02";
BA_ "UserSigValidity" SG_ 813 CDM_GbtWarnMsg_SBCM_Copy_0 0;
BA_ "GenSigSendType" SG_ 813 CDM_GbtWarnMsg_SBCM_Copy_0 4;
BA_ "Description" SG_ 813 CDM_GbtWarnMsg_SBCM_Copy_0 "Command for CDM Warning on cluster(Gbt)";
BA_ "Version" SG_ 813 CDM_GbtOutsideOpnSwSta_Copy_0 "24.01.03";
BA_ "NetworkRequestHoldingTime" SG_ 813 CDM_GbtOutsideOpnSwSta_Copy_0 5000;
BA_ "NetworkRequest" SG_ 813 CDM_GbtOutsideOpnSwSta_Copy_0 0;
BA_ "UserSigValidity" SG_ 813 CDM_GbtOutsideOpnSwSta_Copy_0 0;
BA_ "GenSigSendType" SG_ 813 CDM_GbtOutsideOpnSwSta_Copy_0 4;
BA_ "Version" SG_ 813 DoorLock_DrvLkOutSta_SBCM_Copy_0 "23.02.09";
BA_ "NetworkRequestHoldingTime" SG_ 813 DoorLock_DrvLkOutSta_SBCM_Copy_0 5000;
BA_ "NetworkRequest" SG_ 813 DoorLock_DrvLkOutSta_SBCM_Copy_0 0;
BA_ "UserSigValidity" SG_ 813 DoorLock_DrvLkOutSta_SBCM_Copy_0 0;
BA_ "GenSigSendType" SG_ 813 DoorLock_DrvLkOutSta_SBCM_Copy_0 4;
BA_ "Description" SG_ 813 DoorLock_DrvLkOutSta_SBCM_Copy_0 "- Door Lock or Unlock Output State 

0x0 : Off (Door lock/unlock output Off state)

0x1 : On (Door lock/unlock output On state)";
BA_ "Version" SG_ 813 FrunkEmergencySwSta_SBCM "23.04.04";
BA_ "NetworkRequestHoldingTime" SG_ 813 FrunkEmergencySwSta_SBCM 5000;
BA_ "NetworkRequest" SG_ 813 FrunkEmergencySwSta_SBCM 0;
BA_ "UserSigValidity" SG_ 813 FrunkEmergencySwSta_SBCM 0;
BA_ "GenSigSendType" SG_ 813 FrunkEmergencySwSta_SBCM 4;
BA_ "Description" SG_ 813 FrunkEmergencySwSta_SBCM "FrunkEmergencySwState";
BA_ "Version" SG_ 813 DRV_DetectObj_warn_LH "23.10.11";
BA_ "NetworkRequestHoldingTime" SG_ 813 DRV_DetectObj_warn_LH 5000;
BA_ "NetworkRequest" SG_ 813 DRV_DetectObj_warn_LH 0;
BA_ "UserSigValidity" SG_ 813 DRV_DetectObj_warn_LH 0;
BA_ "GenSigSendType" SG_ 813 DRV_DetectObj_warn_LH 4;
BA_ "Version" SG_ 813 PwrDROpenClosingDdvSdDRSta "23.10.11";
BA_ "NetworkRequestHoldingTime" SG_ 813 PwrDROpenClosingDdvSdDRSta 5000;
BA_ "NetworkRequest" SG_ 813 PwrDROpenClosingDdvSdDRSta 0;
BA_ "UserSigValidity" SG_ 813 PwrDROpenClosingDdvSdDRSta 0;
BA_ "GenSigSendType" SG_ 813 PwrDROpenClosingDdvSdDRSta 4;
BA_ "Version" SG_ 813 PwrDRBuzzerOut_DRV_New "24.01.05";
BA_ "NetworkRequestHoldingTime" SG_ 813 PwrDRBuzzerOut_DRV_New 5000;
BA_ "NetworkRequest" SG_ 813 PwrDRBuzzerOut_DRV_New 0;
BA_ "UserSigValidity" SG_ 813 PwrDRBuzzerOut_DRV_New 0;
BA_ "GenSigSendType" SG_ 813 PwrDRBuzzerOut_DRV_New 4;
BA_ "Description" SG_ 813 PwrDRBuzzerOut_DRV_New "JG~ └√┐ы";
BA_ "Version" SG_ 813 Coach_TypeOption_DRV "24.01.07";
BA_ "NetworkRequestHoldingTime" SG_ 813 Coach_TypeOption_DRV 5000;
BA_ "NetworkRequest" SG_ 813 Coach_TypeOption_DRV 0;
BA_ "UserSigValidity" SG_ 813 Coach_TypeOption_DRV 0;
BA_ "GenSigStartValue" SG_ 813 Coach_TypeOption_DRV 3;
BA_ "GenSigSendType" SG_ 813 Coach_TypeOption_DRV 4;
BA_ "Version" SG_ 813 PwrDrSta_Drv "24.01.05";
BA_ "NetworkRequestHoldingTime" SG_ 813 PwrDrSta_Drv 5000;
BA_ "NetworkRequest" SG_ 813 PwrDrSta_Drv 0;
BA_ "UserSigValidity" SG_ 813 PwrDrSta_Drv 0;
BA_ "GenSigSendType" SG_ 813 PwrDrSta_Drv 4;
BA_ "Version" SG_ 813 PwrDrSta_DrvSd "24.01.05";
BA_ "NetworkRequestHoldingTime" SG_ 813 PwrDrSta_DrvSd 5000;
BA_ "NetworkRequest" SG_ 813 PwrDrSta_DrvSd 0;
BA_ "UserSigValidity" SG_ 813 PwrDrSta_DrvSd 0;
BA_ "GenSigSendType" SG_ 813 PwrDrSta_DrvSd 4;
BA_ "Version" SG_ 813 USM_PwrDrOpnTypSta "24.01.05";
BA_ "NetworkRequestHoldingTime" SG_ 813 USM_PwrDrOpnTypSta 5000;
BA_ "NetworkRequest" SG_ 813 USM_PwrDrOpnTypSta 0;
BA_ "UserSigValidity" SG_ 813 USM_PwrDrOpnTypSta 0;
BA_ "GenSigSendType" SG_ 813 USM_PwrDrOpnTypSta 4;
BA_ "Version" SG_ 813 DischrgDr_OpnClsState_SBCM "24.01.04";
BA_ "NetworkRequestHoldingTime" SG_ 813 DischrgDr_OpnClsState_SBCM 5000;
BA_ "NetworkRequest" SG_ 813 DischrgDr_OpnClsState_SBCM 0;
BA_ "UserSigValidity" SG_ 813 DischrgDr_OpnClsState_SBCM 0;
BA_ "GenSigSendType" SG_ 813 DischrgDr_OpnClsState_SBCM 4;
BA_ "Version" SG_ 813 SBCM_FL_DoorAngle "24.01.05";
BA_ "NetworkRequestHoldingTime" SG_ 813 SBCM_FL_DoorAngle 5000;
BA_ "NetworkRequest" SG_ 813 SBCM_FL_DoorAngle 0;
BA_ "UserSigValidity" SG_ 813 SBCM_FL_DoorAngle 0;
BA_ "GenSigStartValue" SG_ 813 SBCM_FL_DoorAngle 100;
BA_ "GenSigSendType" SG_ 813 SBCM_FL_DoorAngle 4;
BA_ "Description" SG_ 813 SBCM_FL_DoorAngle "PDSM_FL_DoorAngle";
BA_ "Version" SG_ 813 SBCM_DoorType_DRV "24.01.07";
BA_ "NetworkRequestHoldingTime" SG_ 813 SBCM_DoorType_DRV 5000;
BA_ "NetworkRequest" SG_ 813 SBCM_DoorType_DRV 0;
BA_ "UserSigValidity" SG_ 813 SBCM_DoorType_DRV 0;
BA_ "GenSigStartValue" SG_ 813 SBCM_DoorType_DRV 2;
BA_ "GenSigSendType" SG_ 813 SBCM_DoorType_DRV 4;
BA_ "Description" SG_ 813 SBCM_DoorType_DRV "SBCM Applied Type";
BA_ "Version" SG_ 813 CDM_DrType_DRV "24.05.01";
BA_ "NetworkRequestHoldingTime" SG_ 813 CDM_DrType_DRV 5000;
BA_ "NetworkRequest" SG_ 813 CDM_DrType_DRV 0;
BA_ "UserSigValidity" SG_ 813 CDM_DrType_DRV 7;
BA_ "GenSigSendType" SG_ 813 CDM_DrType_DRV 4;
BA_ "Version" SG_ 813 DRVDoorPushAlarm_Copy_0 "21.07.07";
BA_ "NetworkRequestHoldingTime" SG_ 813 DRVDoorPushAlarm_Copy_0 5000;
BA_ "NetworkRequest" SG_ 813 DRVDoorPushAlarm_Copy_0 0;
BA_ "UserSigValidity" SG_ 813 DRVDoorPushAlarm_Copy_0 0;
BA_ "GenSigSendType" SG_ 813 DRVDoorPushAlarm_Copy_0 4;
BA_ "Version" SG_ 813 DRV_CrashUnlockCmd_Copy_0 "21.07.07";
BA_ "NetworkRequest" SG_ 813 DRV_CrashUnlockCmd_Copy_0 0;
BA_ "UserSigValidity" SG_ 813 DRV_CrashUnlockCmd_Copy_0 0;
BA_ "GenSigSendType" SG_ 813 DRV_CrashUnlockCmd_Copy_0 4;
BA_ "Description" SG_ 813 DRV_CrashUnlockCmd_Copy_0 "Drive Crash Unlock Command";
BA_ "Version" SG_ 813 C_ApprOpenStatus_Copy_0 "21.07.07";
BA_ "UserSigValidity" SG_ 813 C_ApprOpenStatus_Copy_0 0;
BA_ "GenSigSendType" SG_ 813 C_ApprOpenStatus_Copy_0 4;
BA_ "Description" SG_ 813 C_ApprOpenStatus_Copy_0 "This is for Power Door System enable/disable signal.";
BA_ "Version" SG_ 813 DoorLock_DrvKeyLkSwSta_SBCM_Copy "21.07.07";
BA_ "NetworkRequest" SG_ 813 DoorLock_DrvKeyLkSwSta_SBCM_Copy 0;
BA_ "UserSigValidity" SG_ 813 DoorLock_DrvKeyLkSwSta_SBCM_Copy 0;
BA_ "GenSigSendType" SG_ 813 DoorLock_DrvKeyLkSwSta_SBCM_Copy 4;
BA_ "Description" SG_ 813 DoorLock_DrvKeyLkSwSta_SBCM_Copy "Door Lock Driver Mechanical Key Input Signal";
BA_ "SystemSignalLongSymbol" SG_ 813 DoorLock_DrvKeyLkSwSta_SBCM_Copy "DoorLock_DrvKeyLkSwSta_SBCM_Copy_0";
BA_ "Version" SG_ 813 DoorLock_DrvKeyUnLkSwSta_SBCM_Co "21.07.07";
BA_ "NetworkRequest" SG_ 813 DoorLock_DrvKeyUnLkSwSta_SBCM_Co 0;
BA_ "UserSigValidity" SG_ 813 DoorLock_DrvKeyUnLkSwSta_SBCM_Co 0;
BA_ "GenSigSendType" SG_ 813 DoorLock_DrvKeyUnLkSwSta_SBCM_Co 4;
BA_ "Description" SG_ 813 DoorLock_DrvKeyUnLkSwSta_SBCM_Co "Door Drive Mechanical Key Unlock Switch State";
BA_ "SystemSignalLongSymbol" SG_ 813 DoorLock_DrvKeyUnLkSwSta_SBCM_Co "DoorLock_DrvKeyUnLkSwSta_SBCM_Copy_0";
BA_ "Version" SG_ 813 Warn_DrvDrSwSta_SBCM_Copy_0 "21.09.05";
BA_ "NetworkRequest" SG_ 813 Warn_DrvDrSwSta_SBCM_Copy_0 0;
BA_ "UserSigValidity" SG_ 813 Warn_DrvDrSwSta_SBCM_Copy_0 0;
BA_ "GenSigSendType" SG_ 813 Warn_DrvDrSwSta_SBCM_Copy_0 4;
BA_ "Description" SG_ 813 Warn_DrvDrSwSta_SBCM_Copy_0 "Warning Drive Door Switch State";
BA_ "Version" SG_ 813 DoorLock_DrvDrUnLkSta_SBCM_Copy_ "21.09.05";
BA_ "NetworkRequest" SG_ 813 DoorLock_DrvDrUnLkSta_SBCM_Copy_ 0;
BA_ "UserSigValidity" SG_ 813 DoorLock_DrvDrUnLkSta_SBCM_Copy_ 0;
BA_ "GenSigSendType" SG_ 813 DoorLock_DrvDrUnLkSta_SBCM_Copy_ 4;
BA_ "Description" SG_ 813 DoorLock_DrvDrUnLkSta_SBCM_Copy_ "Drive Door Lock Unlock Status";
BA_ "SystemSignalLongSymbol" SG_ 813 DoorLock_DrvDrUnLkSta_SBCM_Copy_ "DoorLock_DrvDrUnLkSta_SBCM_Copy_0";
BA_ "Version" SG_ 813 DRV_SEAWarn_LH_Copy_0 "21.07.07";
BA_ "NetworkRequest" SG_ 813 DRV_SEAWarn_LH_Copy_0 0;
BA_ "UserSigValidity" SG_ 813 DRV_SEAWarn_LH_Copy_0 0;
BA_ "GenSigSendType" SG_ 813 DRV_SEAWarn_LH_Copy_0 4;
BA_ "Description" SG_ 813 DRV_SEAWarn_LH_Copy_0 "Drive (FLH) Door SEA Warning";
BA_ "Version" SG_ 813 DRV_SEAWarn_RH_Copy_0 "21.07.07";
BA_ "NetworkRequest" SG_ 813 DRV_SEAWarn_RH_Copy_0 0;
BA_ "UserSigValidity" SG_ 813 DRV_SEAWarn_RH_Copy_0 0;
BA_ "GenSigSendType" SG_ 813 DRV_SEAWarn_RH_Copy_0 4;
BA_ "Description" SG_ 813 DRV_SEAWarn_RH_Copy_0 "Drive (FRH) Door SEA Warning";
BA_ "Version" SG_ 813 DRV_SEWWarn_LH_Copy_0 "21.07.07";
BA_ "NetworkRequest" SG_ 813 DRV_SEWWarn_LH_Copy_0 0;
BA_ "UserSigValidity" SG_ 813 DRV_SEWWarn_LH_Copy_0 0;
BA_ "GenSigSendType" SG_ 813 DRV_SEWWarn_LH_Copy_0 4;
BA_ "Description" SG_ 813 DRV_SEWWarn_LH_Copy_0 "Drive (FLH) Door Safety Exit Warning";
BA_ "Version" SG_ 813 DRV_SEWWarn_RH_Copy_0 "21.07.07";
BA_ "NetworkRequest" SG_ 813 DRV_SEWWarn_RH_Copy_0 0;
BA_ "UserSigValidity" SG_ 813 DRV_SEWWarn_RH_Copy_0 0;
BA_ "GenSigSendType" SG_ 813 DRV_SEWWarn_RH_Copy_0 4;
BA_ "Description" SG_ 813 DRV_SEWWarn_RH_Copy_0 "Drive (FRH) Door Safety Exit Warning";
BA_ "Version" SG_ 813 DRV_MRActivationAlarm_Copy_0 "21.07.07";
BA_ "NetworkRequestHoldingTime" SG_ 813 DRV_MRActivationAlarm_Copy_0 5000;
BA_ "NetworkRequest" SG_ 813 DRV_MRActivationAlarm_Copy_0 0;
BA_ "UserSigValidity" SG_ 813 DRV_MRActivationAlarm_Copy_0 0;
BA_ "GenSigSendType" SG_ 813 DRV_MRActivationAlarm_Copy_0 4;
BA_ "Version" SG_ 813 DRV_ReleaseWarn_Copy_0 "21.09.05";
BA_ "NetworkRequestHoldingTime" SG_ 813 DRV_ReleaseWarn_Copy_0 5000;
BA_ "NetworkRequest" SG_ 813 DRV_ReleaseWarn_Copy_0 0;
BA_ "UserSigValidity" SG_ 813 DRV_ReleaseWarn_Copy_0 0;
BA_ "GenSigSendType" SG_ 813 DRV_ReleaseWarn_Copy_0 4;
BA_ "Version" SG_ 811 SBCM_AST_FD_Crc1Val "22.10.20";
BA_ "UserSigValidity" SG_ 811 SBCM_AST_FD_Crc1Val 3;
BA_ "GenSigStartValue" SG_ 811 SBCM_AST_FD_Crc1Val 65535;
BA_ "GenSigSendType" SG_ 811 SBCM_AST_FD_Crc1Val 4;
BA_ "Description" SG_ 811 SBCM_AST_FD_Crc1Val "The data area for CRC calculation is based on the data length (DLC) of the message DB.

The CRC shall be calculated over the entire data block (excluding the CRC bytes) including the user data, alive counter and Data ID



- CRC Polynomial (0x1021) , Ini";
BA_ "Version" SG_ 811 USM_AstGhostDoorSta_Copy_0 "21.07.07";
BA_ "NetworkRequestHoldingTime" SG_ 811 USM_AstGhostDoorSta_Copy_0 5000;
BA_ "NetworkRequest" SG_ 811 USM_AstGhostDoorSta_Copy_0 0;
BA_ "UserSigValidity" SG_ 811 USM_AstGhostDoorSta_Copy_0 0;
BA_ "GenSigSendType" SG_ 811 USM_AstGhostDoorSta_Copy_0 4;
BA_ "Version" SG_ 811 AST_SWFailAlarm_Copy_0 "21.07.07";
BA_ "NetworkRequestHoldingTime" SG_ 811 AST_SWFailAlarm_Copy_0 5000;
BA_ "NetworkRequest" SG_ 811 AST_SWFailAlarm_Copy_0 0;
BA_ "UserSigValidity" SG_ 811 AST_SWFailAlarm_Copy_0 0;
BA_ "GenSigSendType" SG_ 811 AST_SWFailAlarm_Copy_0 4;
BA_ "Version" SG_ 811 DoorLock_PDSLkSwSta_AST_Copy_0 "21.09.05";
BA_ "NetworkRequest" SG_ 811 DoorLock_PDSLkSwSta_AST_Copy_0 0;
BA_ "UserSigValidity" SG_ 811 DoorLock_PDSLkSwSta_AST_Copy_0 0;
BA_ "GenSigSendType" SG_ 811 DoorLock_PDSLkSwSta_AST_Copy_0 4;
BA_ "Version" SG_ 811 PDS_TypeOption_AST_Copy_0 "21.07.07";
BA_ "NetworkRequest" SG_ 811 PDS_TypeOption_AST_Copy_0 0;
BA_ "UserSigValidity" SG_ 811 PDS_TypeOption_AST_Copy_0 0;
BA_ "GenSigSendType" SG_ 811 PDS_TypeOption_AST_Copy_0 4;
BA_ "Version" SG_ 811 AFCU_AutoWashModeSta_SBCM_AST_Co "22.07.00";
BA_ "NetworkRequestHoldingTime" SG_ 811 AFCU_AutoWashModeSta_SBCM_AST_Co 5000;
BA_ "NetworkRequest" SG_ 811 AFCU_AutoWashModeSta_SBCM_AST_Co 0;
BA_ "UserSigValidity" SG_ 811 AFCU_AutoWashModeSta_SBCM_AST_Co 0;
BA_ "GenSigSendType" SG_ 811 AFCU_AutoWashModeSta_SBCM_AST_Co 4;
BA_ "SystemSignalLongSymbol" SG_ 811 AFCU_AutoWashModeSta_SBCM_AST_Co "AFCU_AutoWashModeSta_SBCM_AST_Copy_0";
BA_ "Version" SG_ 811 CDM_AutoWashModeSta_SBCM_AST_Cop "22.07.00";
BA_ "NetworkRequestHoldingTime" SG_ 811 CDM_AutoWashModeSta_SBCM_AST_Cop 5000;
BA_ "NetworkRequest" SG_ 811 CDM_AutoWashModeSta_SBCM_AST_Cop 0;
BA_ "UserSigValidity" SG_ 811 CDM_AutoWashModeSta_SBCM_AST_Cop 0;
BA_ "GenSigSendType" SG_ 811 CDM_AutoWashModeSta_SBCM_AST_Cop 4;
BA_ "SystemSignalLongSymbol" SG_ 811 CDM_AutoWashModeSta_SBCM_AST_Cop "CDM_AutoWashModeSta_SBCM_AST_Copy_0";
BA_ "Version" SG_ 811 AFH_AST_FldUnFldSta_Copy_0 "24.07.06";
BA_ "NetworkRequestHoldingTime" SG_ 811 AFH_AST_FldUnFldSta_Copy_0 5000;
BA_ "NetworkRequest" SG_ 811 AFH_AST_FldUnFldSta_Copy_0 0;
BA_ "UserSigValidity" SG_ 811 AFH_AST_FldUnFldSta_Copy_0 0;
BA_ "GenSigSendType" SG_ 811 AFH_AST_FldUnFldSta_Copy_0 4;
BA_ "Version" SG_ 811 SBCM_AST_DiagSta_Copy_0 "21.07.07";
BA_ "NetworkRequestHoldingTime" SG_ 811 SBCM_AST_DiagSta_Copy_0 5000;
BA_ "NetworkRequest" SG_ 811 SBCM_AST_DiagSta_Copy_0 0;
BA_ "UserSigValidity" SG_ 811 SBCM_AST_DiagSta_Copy_0 0;
BA_ "GenSigSendType" SG_ 811 SBCM_AST_DiagSta_Copy_0 4;
BA_ "Version" SG_ 811 CDM_TypeOption_AST_Copy_0 "24.07.03";
BA_ "NetworkRequestHoldingTime" SG_ 811 CDM_TypeOption_AST_Copy_0 5000;
BA_ "NetworkRequest" SG_ 811 CDM_TypeOption_AST_Copy_0 0;
BA_ "UserSigValidity" SG_ 811 CDM_TypeOption_AST_Copy_0 7;
BA_ "GenSigSendType" SG_ 811 CDM_TypeOption_AST_Copy_0 4;
BA_ "Version" SG_ 811 CDM_ImmeChgSw_AST_Copy_0 "21.07.07";
BA_ "NetworkRequestHoldingTime" SG_ 811 CDM_ImmeChgSw_AST_Copy_0 5000;
BA_ "NetworkRequest" SG_ 811 CDM_ImmeChgSw_AST_Copy_0 0;
BA_ "UserSigValidity" SG_ 811 CDM_ImmeChgSw_AST_Copy_0 7;
BA_ "GenSigSendType" SG_ 811 CDM_ImmeChgSw_AST_Copy_0 4;
BA_ "Version" SG_ 811 CDM_FobSrchReq_AST_Copy_0 "24.05.03";
BA_ "NetworkRequestHoldingTime" SG_ 811 CDM_FobSrchReq_AST_Copy_0 5000;
BA_ "NetworkRequest" SG_ 811 CDM_FobSrchReq_AST_Copy_0 0;
BA_ "UserSigValidity" SG_ 811 CDM_FobSrchReq_AST_Copy_0 0;
BA_ "GenSigSendType" SG_ 811 CDM_FobSrchReq_AST_Copy_0 4;
BA_ "Version" SG_ 811 CDM_OpnClsState_AST_Copy_0 "21.07.07";
BA_ "NetworkRequestHoldingTime" SG_ 811 CDM_OpnClsState_AST_Copy_0 5000;
BA_ "NetworkRequest" SG_ 811 CDM_OpnClsState_AST_Copy_0 0;
BA_ "UserSigValidity" SG_ 811 CDM_OpnClsState_AST_Copy_0 7;
BA_ "GenSigSendType" SG_ 811 CDM_OpnClsState_AST_Copy_0 4;
BA_ "Version" SG_ 811 CDM_WarnMsg_AST_Copy_0 "21.07.07";
BA_ "NetworkRequestHoldingTime" SG_ 811 CDM_WarnMsg_AST_Copy_0 5000;
BA_ "NetworkRequest" SG_ 811 CDM_WarnMsg_AST_Copy_0 0;
BA_ "UserSigValidity" SG_ 811 CDM_WarnMsg_AST_Copy_0 7;
BA_ "GenSigSendType" SG_ 811 CDM_WarnMsg_AST_Copy_0 4;
BA_ "Version" SG_ 811 Mirror_RH_FoldingSta_Copy_0 "21.07.07";
BA_ "NetworkRequestHoldingTime" SG_ 811 Mirror_RH_FoldingSta_Copy_0 5000;
BA_ "NetworkRequest" SG_ 811 Mirror_RH_FoldingSta_Copy_0 0;
BA_ "UserSigValidity" SG_ 811 Mirror_RH_FoldingSta_Copy_0 0;
BA_ "GenSigSendType" SG_ 811 Mirror_RH_FoldingSta_Copy_0 4;
BA_ "Version" SG_ 811 Mirror_RH_UnfoldingSta_Copy_0 "21.07.07";
BA_ "NetworkRequestHoldingTime" SG_ 811 Mirror_RH_UnfoldingSta_Copy_0 5000;
BA_ "NetworkRequest" SG_ 811 Mirror_RH_UnfoldingSta_Copy_0 0;
BA_ "UserSigValidity" SG_ 811 Mirror_RH_UnfoldingSta_Copy_0 0;
BA_ "GenSigSendType" SG_ 811 Mirror_RH_UnfoldingSta_Copy_0 4;
BA_ "Version" SG_ 811 CDM_CmdStatus_AST_Copy_0 "22.08.03";
BA_ "NetworkRequestHoldingTime" SG_ 811 CDM_CmdStatus_AST_Copy_0 5000;
BA_ "NetworkRequest" SG_ 811 CDM_CmdStatus_AST_Copy_0 0;
BA_ "UserSigValidity" SG_ 811 CDM_CmdStatus_AST_Copy_0 7;
BA_ "GenSigStartValue" SG_ 811 CDM_CmdStatus_AST_Copy_0 15;
BA_ "GenSigSendType" SG_ 811 CDM_CmdStatus_AST_Copy_0 4;
BA_ "Version" SG_ 811 SBCM_AST_FD_AlvCnt1Val "22.10.20";
BA_ "UserSigValidity" SG_ 811 SBCM_AST_FD_AlvCnt1Val 3;
BA_ "GenSigSendType" SG_ 811 SBCM_AST_FD_AlvCnt1Val 4;
BA_ "Description" SG_ 811 SBCM_AST_FD_AlvCnt1Val "For the first transmission request for a data element the counter shall be initialized with 0 and shall be incremented by 1 for every subsequent send request. 

When the counter reaches the maximum value(0xFF), then it shall restart with 0 for the next s";
BA_ "Version" SG_ 811 AST_CrashMRActAlarm_Copy_0 "21.07.07";
BA_ "NetworkRequestHoldingTime" SG_ 811 AST_CrashMRActAlarm_Copy_0 5000;
BA_ "NetworkRequest" SG_ 811 AST_CrashMRActAlarm_Copy_0 0;
BA_ "UserSigValidity" SG_ 811 AST_CrashMRActAlarm_Copy_0 0;
BA_ "GenSigSendType" SG_ 811 AST_CrashMRActAlarm_Copy_0 4;
BA_ "Version" SG_ 811 PwrDRBuzzerOut_AST_Copy_0 "21.07.07";
BA_ "NetworkRequestHoldingTime" SG_ 811 PwrDRBuzzerOut_AST_Copy_0 5000;
BA_ "NetworkRequest" SG_ 811 PwrDRBuzzerOut_AST_Copy_0 0;
BA_ "UserSigValidity" SG_ 811 PwrDRBuzzerOut_AST_Copy_0 0;
BA_ "GenSigSendType" SG_ 811 PwrDRBuzzerOut_AST_Copy_0 4;
BA_ "Version" SG_ 811 IMS_OSMirPlayBackSta_RH_Copy_0 "21.07.07";
BA_ "NetworkRequestHoldingTime" SG_ 811 IMS_OSMirPlayBackSta_RH_Copy_0 5000;
BA_ "NetworkRequest" SG_ 811 IMS_OSMirPlayBackSta_RH_Copy_0 0;
BA_ "UserSigValidity" SG_ 811 IMS_OSMirPlayBackSta_RH_Copy_0 0;
BA_ "GenSigSendType" SG_ 811 IMS_OSMirPlayBackSta_RH_Copy_0 4;
BA_ "Version" SG_ 811 PwrDRClosingASTDrSta_Copy_0 "23.07.06";
BA_ "NetworkRequestHoldingTime" SG_ 811 PwrDRClosingASTDrSta_Copy_0 5000;
BA_ "NetworkRequest" SG_ 811 PwrDRClosingASTDrSta_Copy_0 0;
BA_ "UserSigValidity" SG_ 811 PwrDRClosingASTDrSta_Copy_0 0;
BA_ "GenSigSendType" SG_ 811 PwrDRClosingASTDrSta_Copy_0 4;
BA_ "Version" SG_ 811 CDM_OutsideOpnSwSta_AST_Copy_0 "23.02.02";
BA_ "NetworkRequestHoldingTime" SG_ 811 CDM_OutsideOpnSwSta_AST_Copy_0 5000;
BA_ "NetworkRequest" SG_ 811 CDM_OutsideOpnSwSta_AST_Copy_0 0;
BA_ "UserSigValidity" SG_ 811 CDM_OutsideOpnSwSta_AST_Copy_0 7;
BA_ "GenSigSendType" SG_ 811 CDM_OutsideOpnSwSta_AST_Copy_0 4;
BA_ "Description" SG_ 811 CDM_OutsideOpnSwSta_AST_Copy_0 "Charging Door O/S SW State";
BA_ "Version" SG_ 811 SBCM_Longkey_ASTDrAtClsSwSta_Cop "22.04.02";
BA_ "NetworkRequestHoldingTime" SG_ 811 SBCM_Longkey_ASTDrAtClsSwSta_Cop 5000;
BA_ "NetworkRequest" SG_ 811 SBCM_Longkey_ASTDrAtClsSwSta_Cop 0;
BA_ "UserSigValidity" SG_ 811 SBCM_Longkey_ASTDrAtClsSwSta_Cop 0;
BA_ "GenSigSendType" SG_ 811 SBCM_Longkey_ASTDrAtClsSwSta_Cop 4;
BA_ "SystemSignalLongSymbol" SG_ 811 SBCM_Longkey_ASTDrAtClsSwSta_Cop "SBCM_Longkey_ASTDrAtClsSwSta_Copy_0";
BA_ "Version" SG_ 811 Hood_TypeOption_AST_Copy_0 "22.10.19";
BA_ "NetworkRequestHoldingTime" SG_ 811 Hood_TypeOption_AST_Copy_0 5000;
BA_ "NetworkRequest" SG_ 811 Hood_TypeOption_AST_Copy_0 0;
BA_ "UserSigValidity" SG_ 811 Hood_TypeOption_AST_Copy_0 0;
BA_ "GenSigSendType" SG_ 811 Hood_TypeOption_AST_Copy_0 4;
BA_ "Description" SG_ 811 Hood_TypeOption_AST_Copy_0 "If the E-Hood is applied, the signal will be send.

Frunk signal from SBCM_AST to SBCM_DRV (RHD specification)";
BA_ "Version" SG_ 811 Warn_HoodSwSta_AST_Copy_0 "22.10.19";
BA_ "NetworkRequestHoldingTime" SG_ 811 Warn_HoodSwSta_AST_Copy_0 5000;
BA_ "NetworkRequest" SG_ 811 Warn_HoodSwSta_AST_Copy_0 0;
BA_ "UserSigValidity" SG_ 811 Warn_HoodSwSta_AST_Copy_0 0;
BA_ "GenSigSendType" SG_ 811 Warn_HoodSwSta_AST_Copy_0 4;
BA_ "Description" SG_ 811 Warn_HoodSwSta_AST_Copy_0 "Frunk signal from SBCM_AST to SBCM_DRV (RHD specification)";
BA_ "Version" SG_ 811 FrunkWarning_AST_Copy_0 "22.10.19";
BA_ "NetworkRequestHoldingTime" SG_ 811 FrunkWarning_AST_Copy_0 5000;
BA_ "NetworkRequest" SG_ 811 FrunkWarning_AST_Copy_0 0;
BA_ "UserSigValidity" SG_ 811 FrunkWarning_AST_Copy_0 0;
BA_ "GenSigSendType" SG_ 811 FrunkWarning_AST_Copy_0 4;
BA_ "Description" SG_ 811 FrunkWarning_AST_Copy_0 "Frunk signal from SBCM_AST to SBCM_DRV (RHD specification)";
BA_ "Version" SG_ 811 SBCM_FrunkSta_AST_Copy_0 "22.10.19";
BA_ "NetworkRequestHoldingTime" SG_ 811 SBCM_FrunkSta_AST_Copy_0 5000;
BA_ "NetworkRequest" SG_ 811 SBCM_FrunkSta_AST_Copy_0 0;
BA_ "UserSigValidity" SG_ 811 SBCM_FrunkSta_AST_Copy_0 0;
BA_ "GenSigSendType" SG_ 811 SBCM_FrunkSta_AST_Copy_0 4;
BA_ "Description" SG_ 811 SBCM_FrunkSta_AST_Copy_0 "Frunk signal from SBCM_AST to SBCM_DRV (RHD specification)";
BA_ "Version" SG_ 811 IMS_OSMirPlayBackSta_RH_New_Copy "23.01.03";
BA_ "NetworkRequestHoldingTime" SG_ 811 IMS_OSMirPlayBackSta_RH_New_Copy 5000;
BA_ "NetworkRequest" SG_ 811 IMS_OSMirPlayBackSta_RH_New_Copy 0;
BA_ "UserSigValidity" SG_ 811 IMS_OSMirPlayBackSta_RH_New_Copy 0;
BA_ "GenSigSendType" SG_ 811 IMS_OSMirPlayBackSta_RH_New_Copy 4;
BA_ "Description" SG_ 811 IMS_OSMirPlayBackSta_RH_New_Copy "Applied from standard DB 2.0";
BA_ "SystemSignalLongSymbol" SG_ 811 IMS_OSMirPlayBackSta_RH_New_Copy "IMS_OSMirPlayBackSta_RH_New_Copy_0";
BA_ "Version" SG_ 811 Ast_DrLkRetryFail_SBCM_Copy_0 "23.03.00";
BA_ "NetworkRequestHoldingTime" SG_ 811 Ast_DrLkRetryFail_SBCM_Copy_0 5000;
BA_ "NetworkRequest" SG_ 811 Ast_DrLkRetryFail_SBCM_Copy_0 0;
BA_ "UserSigValidity" SG_ 811 Ast_DrLkRetryFail_SBCM_Copy_0 0;
BA_ "TimeoutValue" SG_ 811 Ast_DrLkRetryFail_SBCM_Copy_0 "0x0";
BA_ "GenSigSendType" SG_ 811 Ast_DrLkRetryFail_SBCM_Copy_0 4;
BA_ "Version" SG_ 811 DoorLock_AstLkOutSta_SBCM_Copy_0 "23.02.09";
BA_ "NetworkRequestHoldingTime" SG_ 811 DoorLock_AstLkOutSta_SBCM_Copy_0 5000;
BA_ "NetworkRequest" SG_ 811 DoorLock_AstLkOutSta_SBCM_Copy_0 0;
BA_ "UserSigValidity" SG_ 811 DoorLock_AstLkOutSta_SBCM_Copy_0 0;
BA_ "GenSigSendType" SG_ 811 DoorLock_AstLkOutSta_SBCM_Copy_0 4;
BA_ "Description" SG_ 811 DoorLock_AstLkOutSta_SBCM_Copy_0 "- Door Lock or Unlock Output State 

0x0 : Off (Door lock/unlock output Off state)

0x1 : On (Door lock/unlock output On state)";
BA_ "Version" SG_ 811 FrunkReleaseSwSta_SBCM_AST "23.03.01";
BA_ "NetworkRequestHoldingTime" SG_ 811 FrunkReleaseSwSta_SBCM_AST 5000;
BA_ "NetworkRequest" SG_ 811 FrunkReleaseSwSta_SBCM_AST 0;
BA_ "UserSigValidity" SG_ 811 FrunkReleaseSwSta_SBCM_AST 0;
BA_ "GenSigSendType" SG_ 811 FrunkReleaseSwSta_SBCM_AST 4;
BA_ "Description" SG_ 811 FrunkReleaseSwSta_SBCM_AST "FrunkReleaseState (SBCM_AST_FD to SBCM_DRV_FD) RHD Spec";
BA_ "Version" SG_ 811 FrunkInsideRelSwSta_SBCM_AST "23.03.01";
BA_ "NetworkRequestHoldingTime" SG_ 811 FrunkInsideRelSwSta_SBCM_AST 5000;
BA_ "NetworkRequest" SG_ 811 FrunkInsideRelSwSta_SBCM_AST 0;
BA_ "UserSigValidity" SG_ 811 FrunkInsideRelSwSta_SBCM_AST 0;
BA_ "GenSigSendType" SG_ 811 FrunkInsideRelSwSta_SBCM_AST 4;
BA_ "Description" SG_ 811 FrunkInsideRelSwSta_SBCM_AST "FrunkInsideReleaseSwState (SBCM_AST_FD to SBCM_DRV_FD) RHD Spec";
BA_ "Version" SG_ 811 FrunkEmergencySwSta_SBCM_AST "23.03.01";
BA_ "NetworkRequestHoldingTime" SG_ 811 FrunkEmergencySwSta_SBCM_AST 5000;
BA_ "NetworkRequest" SG_ 811 FrunkEmergencySwSta_SBCM_AST 0;
BA_ "UserSigValidity" SG_ 811 FrunkEmergencySwSta_SBCM_AST 0;
BA_ "GenSigSendType" SG_ 811 FrunkEmergencySwSta_SBCM_AST 4;
BA_ "Description" SG_ 811 FrunkEmergencySwSta_SBCM_AST "FrunkEmergencySwState (SBCM_AST_FD to SBCM_DRV_FD) RHD Spec";
BA_ "Version" SG_ 811 PwrDrSta_Ast "24.01.05";
BA_ "NetworkRequestHoldingTime" SG_ 811 PwrDrSta_Ast 5000;
BA_ "NetworkRequest" SG_ 811 PwrDrSta_Ast 0;
BA_ "UserSigValidity" SG_ 811 PwrDrSta_Ast 0;
BA_ "GenSigSendType" SG_ 811 PwrDrSta_Ast 4;
BA_ "Version" SG_ 811 PwrDrSta_AstSd "24.01.05";
BA_ "NetworkRequestHoldingTime" SG_ 811 PwrDrSta_AstSd 5000;
BA_ "NetworkRequest" SG_ 811 PwrDrSta_AstSd 0;
BA_ "UserSigValidity" SG_ 811 PwrDrSta_AstSd 0;
BA_ "GenSigSendType" SG_ 811 PwrDrSta_AstSd 4;
BA_ "Version" SG_ 811 DischrgDr_OpnClsState_SBCM_AST "24.07.03";
BA_ "NetworkRequestHoldingTime" SG_ 811 DischrgDr_OpnClsState_SBCM_AST 5000;
BA_ "NetworkRequest" SG_ 811 DischrgDr_OpnClsState_SBCM_AST 0;
BA_ "UserSigValidity" SG_ 811 DischrgDr_OpnClsState_SBCM_AST 0;
BA_ "GenSigSendType" SG_ 811 DischrgDr_OpnClsState_SBCM_AST 4;
BA_ "Version" SG_ 811 AST_DetectObj_warn_LH "23.10.11";
BA_ "NetworkRequestHoldingTime" SG_ 811 AST_DetectObj_warn_LH 5000;
BA_ "NetworkRequest" SG_ 811 AST_DetectObj_warn_LH 0;
BA_ "UserSigValidity" SG_ 811 AST_DetectObj_warn_LH 0;
BA_ "GenSigSendType" SG_ 811 AST_DetectObj_warn_LH 4;
BA_ "Version" SG_ 811 PwrDROpenClosingAstSdDRSta "23.10.11";
BA_ "NetworkRequestHoldingTime" SG_ 811 PwrDROpenClosingAstSdDRSta 5000;
BA_ "NetworkRequest" SG_ 811 PwrDROpenClosingAstSdDRSta 0;
BA_ "UserSigValidity" SG_ 811 PwrDROpenClosingAstSdDRSta 0;
BA_ "GenSigSendType" SG_ 811 PwrDROpenClosingAstSdDRSta 4;
BA_ "Version" SG_ 811 PwrDRBuzzerOut_AST_New "24.01.05";
BA_ "NetworkRequestHoldingTime" SG_ 811 PwrDRBuzzerOut_AST_New 5000;
BA_ "NetworkRequest" SG_ 811 PwrDRBuzzerOut_AST_New 0;
BA_ "UserSigValidity" SG_ 811 PwrDRBuzzerOut_AST_New 0;
BA_ "GenSigSendType" SG_ 811 PwrDRBuzzerOut_AST_New 4;
BA_ "Description" SG_ 811 PwrDRBuzzerOut_AST_New "JG~";
BA_ "Version" SG_ 811 SBCM_FR_DoorAngle "24.01.05";
BA_ "NetworkRequestHoldingTime" SG_ 811 SBCM_FR_DoorAngle 5000;
BA_ "NetworkRequest" SG_ 811 SBCM_FR_DoorAngle 0;
BA_ "UserSigValidity" SG_ 811 SBCM_FR_DoorAngle 0;
BA_ "GenSigStartValue" SG_ 811 SBCM_FR_DoorAngle 100;
BA_ "GenSigSendType" SG_ 811 SBCM_FR_DoorAngle 4;
BA_ "Description" SG_ 811 SBCM_FR_DoorAngle "PDSM_FR_DoorAngle";
BA_ "Version" SG_ 811 EHL_TxInfo_SBCM_AST "24.07.03";
BA_ "NetworkRequestHoldingTime" SG_ 811 EHL_TxInfo_SBCM_AST 5000;
BA_ "NetworkRequest" SG_ 811 EHL_TxInfo_SBCM_AST 0;
BA_ "UserSigValidity" SG_ 811 EHL_TxInfo_SBCM_AST 0;
BA_ "GenSigSendType" SG_ 811 EHL_TxInfo_SBCM_AST 4;
BA_ "Description" SG_ 811 EHL_TxInfo_SBCM_AST "Electronic hood latch status signal transfer for dual hood latch type";
BA_ "Version" SG_ 811 CDM_DrType_AST "24.05.01";
BA_ "NetworkRequestHoldingTime" SG_ 811 CDM_DrType_AST 5000;
BA_ "NetworkRequest" SG_ 811 CDM_DrType_AST 0;
BA_ "UserSigValidity" SG_ 811 CDM_DrType_AST 7;
BA_ "GenSigSendType" SG_ 811 CDM_DrType_AST 4;
BA_ "Version" SG_ 811 ASTDoorPushAlarm_Copy_0 "21.07.07";
BA_ "NetworkRequestHoldingTime" SG_ 811 ASTDoorPushAlarm_Copy_0 5000;
BA_ "NetworkRequest" SG_ 811 ASTDoorPushAlarm_Copy_0 0;
BA_ "UserSigValidity" SG_ 811 ASTDoorPushAlarm_Copy_0 0;
BA_ "GenSigSendType" SG_ 811 ASTDoorPushAlarm_Copy_0 4;
BA_ "Version" SG_ 811 AST_CrashUnlockCmd_Copy_0 "21.07.07";
BA_ "NetworkRequest" SG_ 811 AST_CrashUnlockCmd_Copy_0 0;
BA_ "UserSigValidity" SG_ 811 AST_CrashUnlockCmd_Copy_0 0;
BA_ "GenSigSendType" SG_ 811 AST_CrashUnlockCmd_Copy_0 4;
BA_ "Description" SG_ 811 AST_CrashUnlockCmd_Copy_0 "Assist Crash Unlock Command";
BA_ "Version" SG_ 811 DoorLock_CtrlDrLkSwSta_SBCM_Copy "21.07.07";
BA_ "NetworkRequest" SG_ 811 DoorLock_CtrlDrLkSwSta_SBCM_Copy 0;
BA_ "UserSigValidity" SG_ 811 DoorLock_CtrlDrLkSwSta_SBCM_Copy 0;
BA_ "GenSigSendType" SG_ 811 DoorLock_CtrlDrLkSwSta_SBCM_Copy 4;
BA_ "Description" SG_ 811 DoorLock_CtrlDrLkSwSta_SBCM_Copy "Central Door Lock Assist Switch Status";
BA_ "SystemSignalLongSymbol" SG_ 811 DoorLock_CtrlDrLkSwSta_SBCM_Copy "DoorLock_CtrlDrLkSwSta_SBCM_Copy_0";
BA_ "Version" SG_ 811 DoorLock_CtrlDrUnLkSwSta_SBCM_Co "21.07.07";
BA_ "NetworkRequest" SG_ 811 DoorLock_CtrlDrUnLkSwSta_SBCM_Co 0;
BA_ "UserSigValidity" SG_ 811 DoorLock_CtrlDrUnLkSwSta_SBCM_Co 0;
BA_ "GenSigSendType" SG_ 811 DoorLock_CtrlDrUnLkSwSta_SBCM_Co 4;
BA_ "Description" SG_ 811 DoorLock_CtrlDrUnLkSwSta_SBCM_Co "Central Door Unlock Assist Switch Status";
BA_ "SystemSignalLongSymbol" SG_ 811 DoorLock_CtrlDrUnLkSwSta_SBCM_Co "DoorLock_CtrlDrUnLkSwSta_SBCM_Copy_0";
BA_ "Version" SG_ 811 Warn_AsstDrSwSta_SBCM_Copy_0 "21.09.05";
BA_ "NetworkRequest" SG_ 811 Warn_AsstDrSwSta_SBCM_Copy_0 0;
BA_ "UserSigValidity" SG_ 811 Warn_AsstDrSwSta_SBCM_Copy_0 0;
BA_ "GenSigSendType" SG_ 811 Warn_AsstDrSwSta_SBCM_Copy_0 4;
BA_ "Description" SG_ 811 Warn_AsstDrSwSta_SBCM_Copy_0 "Warning Assist Door Switch Status";
BA_ "Version" SG_ 811 DoorLock_AsstDrUnLkSta_SBCM_Copy "21.07.07";
BA_ "NetworkRequest" SG_ 811 DoorLock_AsstDrUnLkSta_SBCM_Copy 0;
BA_ "UserSigValidity" SG_ 811 DoorLock_AsstDrUnLkSta_SBCM_Copy 0;
BA_ "GenSigSendType" SG_ 811 DoorLock_AsstDrUnLkSta_SBCM_Copy 4;
BA_ "Description" SG_ 811 DoorLock_AsstDrUnLkSta_SBCM_Copy "Assist Door Unlock Status";
BA_ "SystemSignalLongSymbol" SG_ 811 DoorLock_AsstDrUnLkSta_SBCM_Copy "DoorLock_AsstDrUnLkSta_SBCM_Copy_0";
BA_ "Version" SG_ 811 AST_SEAWarn_RH_Copy_0 "21.07.07";
BA_ "NetworkRequest" SG_ 811 AST_SEAWarn_RH_Copy_0 0;
BA_ "UserSigValidity" SG_ 811 AST_SEAWarn_RH_Copy_0 0;
BA_ "GenSigSendType" SG_ 811 AST_SEAWarn_RH_Copy_0 4;
BA_ "Description" SG_ 811 AST_SEAWarn_RH_Copy_0 "Assist (FRH) SEA Warning";
BA_ "Version" SG_ 811 AST_SEAWarn_LH_Copy_0 "21.07.07";
BA_ "NetworkRequest" SG_ 811 AST_SEAWarn_LH_Copy_0 0;
BA_ "UserSigValidity" SG_ 811 AST_SEAWarn_LH_Copy_0 0;
BA_ "GenSigSendType" SG_ 811 AST_SEAWarn_LH_Copy_0 4;
BA_ "Description" SG_ 811 AST_SEAWarn_LH_Copy_0 "Assist (FLH) Door SEA Warning";
BA_ "Version" SG_ 811 AST_SEWWarn_LH_Copy_0 "21.07.07";
BA_ "NetworkRequest" SG_ 811 AST_SEWWarn_LH_Copy_0 0;
BA_ "UserSigValidity" SG_ 811 AST_SEWWarn_LH_Copy_0 0;
BA_ "GenSigSendType" SG_ 811 AST_SEWWarn_LH_Copy_0 4;
BA_ "Version" SG_ 811 AST_SEWWarn_RH_Copy_0 "21.07.07";
BA_ "NetworkRequest" SG_ 811 AST_SEWWarn_RH_Copy_0 0;
BA_ "UserSigValidity" SG_ 811 AST_SEWWarn_RH_Copy_0 0;
BA_ "GenSigSendType" SG_ 811 AST_SEWWarn_RH_Copy_0 4;
BA_ "Version" SG_ 811 AST_MRActivationAlarm_Copy_0 "21.07.07";
BA_ "NetworkRequestHoldingTime" SG_ 811 AST_MRActivationAlarm_Copy_0 5000;
BA_ "NetworkRequest" SG_ 811 AST_MRActivationAlarm_Copy_0 0;
BA_ "UserSigValidity" SG_ 811 AST_MRActivationAlarm_Copy_0 0;
BA_ "GenSigSendType" SG_ 811 AST_MRActivationAlarm_Copy_0 4;
BA_ "Version" SG_ 811 AST_ReleaseWarn_Copy_0 "21.09.05";
BA_ "NetworkRequestHoldingTime" SG_ 811 AST_ReleaseWarn_Copy_0 5000;
BA_ "NetworkRequest" SG_ 811 AST_ReleaseWarn_Copy_0 0;
BA_ "UserSigValidity" SG_ 811 AST_ReleaseWarn_Copy_0 0;
BA_ "GenSigSendType" SG_ 811 AST_ReleaseWarn_Copy_0 4;
BA_ "Version" SG_ 2525341953 L_UWB_FR_FD_Crc5Val "24.07.05";
BA_ "RoutingFactor" SG_ 2525341953 L_UWB_FR_FD_Crc5Val 0;
BA_ "UserSigValidity" SG_ 2525341953 L_UWB_FR_FD_Crc5Val 3;
BA_ "GenSigStartValue" SG_ 2525341953 L_UWB_FR_FD_Crc5Val 65535;
BA_ "GenSigSendType" SG_ 2525341953 L_UWB_FR_FD_Crc5Val 2;
BA_ "Description" SG_ 2525341953 L_UWB_FR_FD_Crc5Val "The data area for CRC calculation is based on the data length (DLC) of the message DB.

The CRC shall be calculated over the entire data block (excluding the CRC bytes) including the user data, alive counter and Data ID



- CRC Polynomial (0x1021) , Ini";
BA_ "Version" SG_ 2525341953 L_UWB_FR_FD_AlvCnt5Val "24.07.05";
BA_ "RoutingFactor" SG_ 2525341953 L_UWB_FR_FD_AlvCnt5Val 0;
BA_ "UserSigValidity" SG_ 2525341953 L_UWB_FR_FD_AlvCnt5Val 3;
BA_ "GenSigSendType" SG_ 2525341953 L_UWB_FR_FD_AlvCnt5Val 2;
BA_ "Description" SG_ 2525341953 L_UWB_FR_FD_AlvCnt5Val "For the first transmission request for a data element the counter shall be initialized with 0 and shall be incremented by 1 for every subsequent send request. 

When the counter reaches the maximum value(0xFF), then it shall restart with 0 for the next s";
BA_ "Version" SG_ 2525341953 FR_SWID_3_IVD_2 "24.07.05";
BA_ "RoutingFactor" SG_ 2525341953 FR_SWID_3_IVD_2 0;
BA_ "UserSigValidity" SG_ 2525341953 FR_SWID_3_IVD_2 0;
BA_ "GenSigSendType" SG_ 2525341953 FR_SWID_3_IVD_2 2;
BA_ "Version" SG_ 2521141761 L_UWB_BLE_MST_FD_Crc23Val "24.07.05";
BA_ "UserSigValidity" SG_ 2521141761 L_UWB_BLE_MST_FD_Crc23Val 3;
BA_ "GenSigStartValue" SG_ 2521141761 L_UWB_BLE_MST_FD_Crc23Val 65535;
BA_ "GenSigSendType" SG_ 2521141761 L_UWB_BLE_MST_FD_Crc23Val 4;
BA_ "Description" SG_ 2521141761 L_UWB_BLE_MST_FD_Crc23Val "The data area for CRC calculation is based on the data length (DLC) of the message DB.

The CRC shall be calculated over the entire data block (excluding the CRC bytes) including the user data, alive counter and Data ID



- CRC Polynomial (0x1021) , Ini";
BA_ "Version" SG_ 2521141761 L_UWB_BLE_MST_FD_AlvCnt23Val "24.07.05";
BA_ "UserSigValidity" SG_ 2521141761 L_UWB_BLE_MST_FD_AlvCnt23Val 3;
BA_ "GenSigSendType" SG_ 2521141761 L_UWB_BLE_MST_FD_AlvCnt23Val 4;
BA_ "Description" SG_ 2521141761 L_UWB_BLE_MST_FD_AlvCnt23Val "For the first transmission request for a data element the counter shall be initialized with 0 and shall be incremented by 1 for every subsequent send request. 

When the counter reaches the maximum value(0xFF), then it shall restart with 0 for the next s";
BA_ "Version" SG_ 2521141761 MST_DTC "24.07.05";
BA_ "UserSigValidity" SG_ 2521141761 MST_DTC 0;
BA_ "GenSigSendType" SG_ 2521141761 MST_DTC 4;
BA_ "Description" SG_ 2521141761 MST_DTC "Master DTC Data : defined UWB_BLE_SyRS";
BA_ "Version" SG_ 2521141761 MST_DTC_BLE "24.07.05";
BA_ "UserSigValidity" SG_ 2521141761 MST_DTC_BLE 0;
BA_ "GenSigSendType" SG_ 2521141761 MST_DTC_BLE 4;
BA_ "Description" SG_ 2521141761 MST_DTC_BLE "Master BLE DTC Data : defined UWB_BLE_SyRS";
BA_ "Version" SG_ 2521141761 Pulse_Shape_Combo_Info "24.07.05";
BA_ "UserSigValidity" SG_ 2521141761 Pulse_Shape_Combo_Info 0;
BA_ "GenSigSendType" SG_ 2521141761 Pulse_Shape_Combo_Info 4;
BA_ "Description" SG_ 2521141761 Pulse_Shape_Combo_Info "UWB Pulse_Spape_combo Information";
BA_ "Version" SG_ 2214592770 L_UWB_RR_FD_Crc3Val "23.01.02";
BA_ "UserSigValidity" SG_ 2214592770 L_UWB_RR_FD_Crc3Val 3;
BA_ "GenSigStartValue" SG_ 2214592770 L_UWB_RR_FD_Crc3Val 65535;
BA_ "GenSigSendType" SG_ 2214592770 L_UWB_RR_FD_Crc3Val 2;
BA_ "Description" SG_ 2214592770 L_UWB_RR_FD_Crc3Val "The data area for CRC calculation is based on the data length (DLC) of the message DB.

The CRC shall be calculated over the entire data block (excluding the CRC bytes) including the user data, alive counter and Data ID



- CRC Polynomial (0x1021) , Ini";
BA_ "Version" SG_ 2214592770 L_UWB_RR_FD_AlvCnt3Val "23.01.02";
BA_ "UserSigValidity" SG_ 2214592770 L_UWB_RR_FD_AlvCnt3Val 3;
BA_ "GenSigSendType" SG_ 2214592770 L_UWB_RR_FD_AlvCnt3Val 2;
BA_ "Description" SG_ 2214592770 L_UWB_RR_FD_AlvCnt3Val "For the first transmission request for a data element the counter shall be initialized with 0 and shall be incremented by 1 for every subsequent send request. 

When the counter reaches the maximum value(0xFF), then it shall restart with 0 for the next s";
BA_ "Version" SG_ 2214592770 UWB_RR_Ranging_Enc_Result2 "24.04.06";
BA_ "UserSigValidity" SG_ 2214592770 UWB_RR_Ranging_Enc_Result2 0;
BA_ "GenSigSendType" SG_ 2214592770 UWB_RR_Ranging_Enc_Result2 2;
BA_ "Description" SG_ 2214592770 UWB_RR_Ranging_Enc_Result2 "UWB Ranging Result2(Encrypted Data) with DK";
BA_ "Version" SG_ 2214592770 UWB_RR_Ranging_Enc_Result "23.01.02";
BA_ "UserSigValidity" SG_ 2214592770 UWB_RR_Ranging_Enc_Result 0;
BA_ "GenSigSendType" SG_ 2214592770 UWB_RR_Ranging_Enc_Result 2;
BA_ "Version" SG_ 2214592768 L_UWB_RR_FD_Crc1Val "23.01.02";
BA_ "UserSigValidity" SG_ 2214592768 L_UWB_RR_FD_Crc1Val 3;
BA_ "GenSigStartValue" SG_ 2214592768 L_UWB_RR_FD_Crc1Val 65535;
BA_ "GenSigSendType" SG_ 2214592768 L_UWB_RR_FD_Crc1Val 4;
BA_ "Description" SG_ 2214592768 L_UWB_RR_FD_Crc1Val "The data area for CRC calculation is based on the data length (DLC) of the message DB.

The CRC shall be calculated over the entire data block (excluding the CRC bytes) including the user data, alive counter and Data ID



- CRC Polynomial (0x1021) , Ini";
BA_ "Version" SG_ 2214592768 L_UWB_RR_FD_AlvCnt1Val "23.01.02";
BA_ "UserSigValidity" SG_ 2214592768 L_UWB_RR_FD_AlvCnt1Val 3;
BA_ "GenSigSendType" SG_ 2214592768 L_UWB_RR_FD_AlvCnt1Val 4;
BA_ "Description" SG_ 2214592768 L_UWB_RR_FD_AlvCnt1Val "For the first transmission request for a data element the counter shall be initialized with 0 and shall be incremented by 1 for every subsequent send request. 

When the counter reaches the maximum value(0xFF), then it shall restart with 0 for the next s";
BA_ "Version" SG_ 2214592768 UWB_RR_UWB_Decrypt_FB "23.01.02";
BA_ "UserSigValidity" SG_ 2214592768 UWB_RR_UWB_Decrypt_FB 0;
BA_ "GenSigSendType" SG_ 2214592768 UWB_RR_UWB_Decrypt_FB 4;
BA_ "Version" SG_ 2214592768 UWB_RR_MST_Decrypt_FB "23.01.02";
BA_ "UserSigValidity" SG_ 2214592768 UWB_RR_MST_Decrypt_FB 0;
BA_ "GenSigSendType" SG_ 2214592768 UWB_RR_MST_Decrypt_FB 4;
BA_ "Version" SG_ 2214592768 UWB_RR_OTA_Rsp "24.07.05";
BA_ "UserSigValidity" SG_ 2214592768 UWB_RR_OTA_Rsp 0;
BA_ "GenSigSendType" SG_ 2214592768 UWB_RR_OTA_Rsp 4;
BA_ "Description" SG_ 2214592768 UWB_RR_OTA_Rsp "UWB RR OTA response";
BA_ "Version" SG_ 2214592768 UWB_RR_UWB_IC_Status "24.04.03";
BA_ "UserSigValidity" SG_ 2214592768 UWB_RR_UWB_IC_Status 0;
BA_ "GenSigSendType" SG_ 2214592768 UWB_RR_UWB_IC_Status 4;
BA_ "Description" SG_ 2214592768 UWB_RR_UWB_IC_Status "UWB IC Status Message";
BA_ "Version" SG_ 2683310106 Devmsg_FD_1_TX "23.10.02";
BA_ "RoutingFactor" SG_ 2683310106 Devmsg_FD_1_TX 0;
BA_ "NetworkRequestHoldingTime" SG_ 2683310106 Devmsg_FD_1_TX 5000;
BA_ "NetworkRequest" SG_ 2683310106 Devmsg_FD_1_TX 0;
BA_ "UserSigValidity" SG_ 2683310106 Devmsg_FD_1_TX 0;
BA_ "GenSigSendType" SG_ 2683310106 Devmsg_FD_1_TX 2;
BA_ "UsrSigPurpose" SG_ 2683310106 Devmsg_FD_1_TX 7;
BA_ "Description" SG_ 2683310106 Devmsg_FD_1_TX "Development message for BDC_FD";
BA_ "Version" SG_ 2214592769 L_UWB_RR_FD_Crc2Val "23.01.02";
BA_ "UserSigValidity" SG_ 2214592769 L_UWB_RR_FD_Crc2Val 3;
BA_ "GenSigStartValue" SG_ 2214592769 L_UWB_RR_FD_Crc2Val 65535;
BA_ "GenSigSendType" SG_ 2214592769 L_UWB_RR_FD_Crc2Val 4;
BA_ "Description" SG_ 2214592769 L_UWB_RR_FD_Crc2Val "The data area for CRC calculation is based on the data length (DLC) of the message DB.

The CRC shall be calculated over the entire data block (excluding the CRC bytes) including the user data, alive counter and Data ID



- CRC Polynomial (0x1021) , Ini";
BA_ "Version" SG_ 2214592769 L_UWB_RR_FD_AlvCnt2Val "23.01.02";
BA_ "UserSigValidity" SG_ 2214592769 L_UWB_RR_FD_AlvCnt2Val 3;
BA_ "GenSigSendType" SG_ 2214592769 L_UWB_RR_FD_AlvCnt2Val 4;
BA_ "Description" SG_ 2214592769 L_UWB_RR_FD_AlvCnt2Val "For the first transmission request for a data element the counter shall be initialized with 0 and shall be incremented by 1 for every subsequent send request. 

When the counter reaches the maximum value(0xFF), then it shall restart with 0 for the next s";
BA_ "Version" SG_ 2214592769 UWB_RR_FOB_RSD_Enc_Result "23.01.02";
BA_ "UserSigValidity" SG_ 2214592769 UWB_RR_FOB_RSD_Enc_Result 0;
BA_ "GenSigSendType" SG_ 2214592769 UWB_RR_FOB_RSD_Enc_Result 4;
BA_ "Version" SG_ 2214592783 UWB_RR_Dvp_Data "23.10.02";
BA_ "UserSigValidity" SG_ 2214592783 UWB_RR_Dvp_Data 0;
BA_ "GenSigSendType" SG_ 2214592783 UWB_RR_Dvp_Data 2;
BA_ "Version" SG_ 2281701456 L_BDC_FD_IAU_Crc10Val "23.01.02";
BA_ "UserSigValidity" SG_ 2281701456 L_BDC_FD_IAU_Crc10Val 3;
BA_ "GenSigStartValue" SG_ 2281701456 L_BDC_FD_IAU_Crc10Val 65535;
BA_ "GenSigSendType" SG_ 2281701456 L_BDC_FD_IAU_Crc10Val 4;
BA_ "Description" SG_ 2281701456 L_BDC_FD_IAU_Crc10Val "The data area for CRC calculation is based on the data length (DLC) of the message DB.

The CRC shall be calculated over the entire data block (excluding the CRC bytes) including the user data, alive counter and Data ID



- CRC Polynomial (0x1021) , Ini";
BA_ "Version" SG_ 2281701456 L_BDC_FD_IAU_AlvCnt10Val "23.01.02";
BA_ "UserSigValidity" SG_ 2281701456 L_BDC_FD_IAU_AlvCnt10Val 3;
BA_ "GenSigSendType" SG_ 2281701456 L_BDC_FD_IAU_AlvCnt10Val 4;
BA_ "Description" SG_ 2281701456 L_BDC_FD_IAU_AlvCnt10Val "For the first transmission request for a data element the counter shall be initialized with 0 and shall be incremented by 1 for every subsequent send request. 

When the counter reaches the maximum value(0xFF), then it shall restart with 0 for the next s";
BA_ "Version" SG_ 2281701456 BodyType_Sta "23.01.02";
BA_ "UserSigValidity" SG_ 2281701456 BodyType_Sta 0;
BA_ "GenSigSendType" SG_ 2281701456 BodyType_Sta 4;
BA_ "Version" SG_ 2281701456 Trunk_Tailgate_Info "24.05.06";
BA_ "UserSigValidity" SG_ 2281701456 Trunk_Tailgate_Info 0;
BA_ "GenSigSendType" SG_ 2281701456 Trunk_Tailgate_Info 4;
BA_ "Description" SG_ 2281701456 Trunk_Tailgate_Info "Trunk and Tailgate Type";
BA_ "Version" SG_ 2281701456 BDC_TP_CAN_Sta "23.01.02";
BA_ "UserSigValidity" SG_ 2281701456 BDC_TP_CAN_Sta 0;
BA_ "GenSigSendType" SG_ 2281701456 BDC_TP_CAN_Sta 4;
BA_ "Version" SG_ 2281701456 OPAdv_On_Cmd "23.01.02";
BA_ "UserSigValidity" SG_ 2281701456 OPAdv_On_Cmd 0;
BA_ "GenSigSendType" SG_ 2281701456 OPAdv_On_Cmd 4;
BA_ "Version" SG_ 2281701456 WPC_Device_On_Cmd "23.01.02";
BA_ "UserSigValidity" SG_ 2281701456 WPC_Device_On_Cmd 0;
BA_ "GenSigSendType" SG_ 2281701456 WPC_Device_On_Cmd 4;
BA_ "Version" SG_ 2281701456 RgnTyp_Opt "23.02.02";
BA_ "UserSigValidity" SG_ 2281701456 RgnTyp_Opt 0;
BA_ "GenSigSendType" SG_ 2281701456 RgnTyp_Opt 4;
BA_ "Version" SG_ 2281701456 SunRoofTyp_Opt "23.06.01";
BA_ "UserSigValidity" SG_ 2281701456 SunRoofTyp_Opt 0;
BA_ "GenSigSendType" SG_ 2281701456 SunRoofTyp_Opt 4;
BA_ "Description" SG_ 2281701456 SunRoofTyp_Opt "Optional signal for sunroof system with voice control function (C_SunroofOpt)

BDC transmits 0x1 only when LIN communication type Panorama Roof or Panorama Roof with Rear blind is applied. (Others are sent as 0x0)";
BA_ "Version" SG_ 2281701456 BDC_RSPA_DKID "23.11.00";
BA_ "NetworkRequest" SG_ 2281701456 BDC_RSPA_DKID 0;
BA_ "UserSigValidity" SG_ 2281701456 BDC_RSPA_DKID 0;
BA_ "TimeoutValue" SG_ 2281701456 BDC_RSPA_DKID "0x0";
BA_ "GenSigSendType" SG_ 2281701456 BDC_RSPA_DKID 4;
BA_ "Description" SG_ 2281701456 BDC_RSPA_DKID "The DK ID  which operate  RSPA control";
BA_ "Version" SG_ 2281701457 L_BDC_FD_IAU_Crc11Val "23.01.02";
BA_ "UserSigValidity" SG_ 2281701457 L_BDC_FD_IAU_Crc11Val 3;
BA_ "GenSigStartValue" SG_ 2281701457 L_BDC_FD_IAU_Crc11Val 65535;
BA_ "GenSigSendType" SG_ 2281701457 L_BDC_FD_IAU_Crc11Val 4;
BA_ "Description" SG_ 2281701457 L_BDC_FD_IAU_Crc11Val "The data area for CRC calculation is based on the data length (DLC) of the message DB.

The CRC shall be calculated over the entire data block (excluding the CRC bytes) including the user data, alive counter and Data ID



- CRC Polynomial (0x1021) , Ini";
BA_ "Version" SG_ 2281701457 L_BDC_FD_IAU_AlvCnt11Val "23.01.02";
BA_ "UserSigValidity" SG_ 2281701457 L_BDC_FD_IAU_AlvCnt11Val 3;
BA_ "GenSigSendType" SG_ 2281701457 L_BDC_FD_IAU_AlvCnt11Val 4;
BA_ "Description" SG_ 2281701457 L_BDC_FD_IAU_AlvCnt11Val "For the first transmission request for a data element the counter shall be initialized with 0 and shall be incremented by 1 for every subsequent send request. 

When the counter reaches the maximum value(0xFF), then it shall restart with 0 for the next s";
BA_ "Version" SG_ 2281701457 UWB_Ranging_RndNum "23.02.06";
BA_ "UserSigValidity" SG_ 2281701457 UWB_Ranging_RndNum 0;
BA_ "GenSigSendType" SG_ 2281701457 UWB_Ranging_RndNum 4;
BA_ "Description" SG_ 2281701457 UWB_Ranging_RndNum "Valid Value Range : 0x0~0xFFFFFFFFFFFFFFFF";
BA_ "Version" SG_ 2683310089 Devmsg_FD_IAU_2_RX "23.10.12";
BA_ "NetworkRequestHoldingTime" SG_ 2683310089 Devmsg_FD_IAU_2_RX 5000;
BA_ "NetworkRequest" SG_ 2683310089 Devmsg_FD_IAU_2_RX 0;
BA_ "UserSigValidity" SG_ 2683310089 Devmsg_FD_IAU_2_RX 0;
BA_ "GenSigSendType" SG_ 2683310089 Devmsg_FD_IAU_2_RX 2;
BA_ "UsrSigPurpose" SG_ 2683310089 Devmsg_FD_IAU_2_RX 7;
BA_ "Description" SG_ 2683310089 Devmsg_FD_IAU_2_RX "Development message for BDC_FD";
BA_ "Version" SG_ 2214592786 L_UWB_TRNK_FD_Crc3Val "23.01.02";
BA_ "UserSigValidity" SG_ 2214592786 L_UWB_TRNK_FD_Crc3Val 3;
BA_ "GenSigStartValue" SG_ 2214592786 L_UWB_TRNK_FD_Crc3Val 65535;
BA_ "GenSigSendType" SG_ 2214592786 L_UWB_TRNK_FD_Crc3Val 2;
BA_ "Description" SG_ 2214592786 L_UWB_TRNK_FD_Crc3Val "The data area for CRC calculation is based on the data length (DLC) of the message DB.

The CRC shall be calculated over the entire data block (excluding the CRC bytes) including the user data, alive counter and Data ID



- CRC Polynomial (0x1021) , Ini";
BA_ "Version" SG_ 2214592786 L_UWB_TRNK_FD_AlvCnt3Val "23.01.02";
BA_ "UserSigValidity" SG_ 2214592786 L_UWB_TRNK_FD_AlvCnt3Val 3;
BA_ "GenSigSendType" SG_ 2214592786 L_UWB_TRNK_FD_AlvCnt3Val 2;
BA_ "Description" SG_ 2214592786 L_UWB_TRNK_FD_AlvCnt3Val "For the first transmission request for a data element the counter shall be initialized with 0 and shall be incremented by 1 for every subsequent send request. 

When the counter reaches the maximum value(0xFF), then it shall restart with 0 for the next s";
BA_ "Version" SG_ 2214592786 UWB_TRNK_Ranging_Enc_Result2 "24.04.06";
BA_ "UserSigValidity" SG_ 2214592786 UWB_TRNK_Ranging_Enc_Result2 0;
BA_ "GenSigSendType" SG_ 2214592786 UWB_TRNK_Ranging_Enc_Result2 2;
BA_ "Description" SG_ 2214592786 UWB_TRNK_Ranging_Enc_Result2 "UWB Ranging Result2(Encrypted Data) with DK";
BA_ "Version" SG_ 2214592786 UWB_TRNK_Ranging_Enc_Result "23.01.02";
BA_ "UserSigValidity" SG_ 2214592786 UWB_TRNK_Ranging_Enc_Result 0;
BA_ "GenSigSendType" SG_ 2214592786 UWB_TRNK_Ranging_Enc_Result 2;
BA_ "Version" SG_ 2214592785 L_UWB_TRNK_FD_Crc2Val "23.01.02";
BA_ "UserSigValidity" SG_ 2214592785 L_UWB_TRNK_FD_Crc2Val 3;
BA_ "GenSigStartValue" SG_ 2214592785 L_UWB_TRNK_FD_Crc2Val 65535;
BA_ "GenSigSendType" SG_ 2214592785 L_UWB_TRNK_FD_Crc2Val 4;
BA_ "Description" SG_ 2214592785 L_UWB_TRNK_FD_Crc2Val "The data area for CRC calculation is based on the data length (DLC) of the message DB.

The CRC shall be calculated over the entire data block (excluding the CRC bytes) including the user data, alive counter and Data ID



- CRC Polynomial (0x1021) , Ini";
BA_ "Version" SG_ 2214592785 L_UWB_TRNK_FD_AlvCnt2Val "23.01.02";
BA_ "UserSigValidity" SG_ 2214592785 L_UWB_TRNK_FD_AlvCnt2Val 3;
BA_ "GenSigSendType" SG_ 2214592785 L_UWB_TRNK_FD_AlvCnt2Val 4;
BA_ "Description" SG_ 2214592785 L_UWB_TRNK_FD_AlvCnt2Val "For the first transmission request for a data element the counter shall be initialized with 0 and shall be incremented by 1 for every subsequent send request. 

When the counter reaches the maximum value(0xFF), then it shall restart with 0 for the next s";
BA_ "Version" SG_ 2214592785 UWB_TRNK_FOB_RSD_Enc_Result "23.01.02";
BA_ "UserSigValidity" SG_ 2214592785 UWB_TRNK_FOB_RSD_Enc_Result 0;
BA_ "GenSigSendType" SG_ 2214592785 UWB_TRNK_FOB_RSD_Enc_Result 4;
BA_ "Version" SG_ 2214592784 L_UWB_TRNK_FD_Crc1Val "23.01.02";
BA_ "UserSigValidity" SG_ 2214592784 L_UWB_TRNK_FD_Crc1Val 3;
BA_ "GenSigStartValue" SG_ 2214592784 L_UWB_TRNK_FD_Crc1Val 65535;
BA_ "GenSigSendType" SG_ 2214592784 L_UWB_TRNK_FD_Crc1Val 4;
BA_ "Description" SG_ 2214592784 L_UWB_TRNK_FD_Crc1Val "The data area for CRC calculation is based on the data length (DLC) of the message DB.

The CRC shall be calculated over the entire data block (excluding the CRC bytes) including the user data, alive counter and Data ID



- CRC Polynomial (0x1021) , Ini";
BA_ "Version" SG_ 2214592784 L_UWB_TRNK_FD_AlvCnt1Val "23.01.02";
BA_ "UserSigValidity" SG_ 2214592784 L_UWB_TRNK_FD_AlvCnt1Val 3;
BA_ "GenSigSendType" SG_ 2214592784 L_UWB_TRNK_FD_AlvCnt1Val 4;
BA_ "Description" SG_ 2214592784 L_UWB_TRNK_FD_AlvCnt1Val "For the first transmission request for a data element the counter shall be initialized with 0 and shall be incremented by 1 for every subsequent send request. 

When the counter reaches the maximum value(0xFF), then it shall restart with 0 for the next s";
BA_ "Version" SG_ 2214592784 UWB_TRNK_UWB_Decrypt_FB "23.01.02";
BA_ "UserSigValidity" SG_ 2214592784 UWB_TRNK_UWB_Decrypt_FB 0;
BA_ "GenSigSendType" SG_ 2214592784 UWB_TRNK_UWB_Decrypt_FB 4;
BA_ "Version" SG_ 2214592784 UWB_TRNK_MST_Decrypt_FB "23.01.02";
BA_ "UserSigValidity" SG_ 2214592784 UWB_TRNK_MST_Decrypt_FB 0;
BA_ "GenSigSendType" SG_ 2214592784 UWB_TRNK_MST_Decrypt_FB 4;
BA_ "Version" SG_ 2214592784 UWB_TRNK_OTA_Rsp "24.07.05";
BA_ "UserSigValidity" SG_ 2214592784 UWB_TRNK_OTA_Rsp 0;
BA_ "GenSigSendType" SG_ 2214592784 UWB_TRNK_OTA_Rsp 4;
BA_ "Description" SG_ 2214592784 UWB_TRNK_OTA_Rsp "UWB TRNK OTA response";
BA_ "Version" SG_ 2214592784 UWB_TRNK_UWB_IC_Status "24.04.03";
BA_ "UserSigValidity" SG_ 2214592784 UWB_TRNK_UWB_IC_Status 0;
BA_ "GenSigSendType" SG_ 2214592784 UWB_TRNK_UWB_IC_Status 4;
BA_ "Description" SG_ 2214592784 UWB_TRNK_UWB_IC_Status "UWB IC Status Message";
BA_ "Version" SG_ 2214592799 UWB_TRNK_Dvp_Data "23.01.02";
BA_ "UserSigValidity" SG_ 2214592799 UWB_TRNK_Dvp_Data 0;
BA_ "GenSigSendType" SG_ 2214592799 UWB_TRNK_Dvp_Data 2;
BA_ "Version" SG_ 2683310087 Devmsg_FD_IAU_1_RX "23.10.12";
BA_ "NetworkRequestHoldingTime" SG_ 2683310087 Devmsg_FD_IAU_1_RX 5000;
BA_ "NetworkRequest" SG_ 2683310087 Devmsg_FD_IAU_1_RX 0;
BA_ "UserSigValidity" SG_ 2683310087 Devmsg_FD_IAU_1_RX 0;
BA_ "GenSigSendType" SG_ 2683310087 Devmsg_FD_IAU_1_RX 2;
BA_ "UsrSigPurpose" SG_ 2683310087 Devmsg_FD_IAU_1_RX 7;
BA_ "Description" SG_ 2683310087 Devmsg_FD_IAU_1_RX "Development message for BDC_FD";
BA_ "Version" SG_ 2533738497 L_UWB_FRNK_FD_Crc4Val "24.07.05";
BA_ "RoutingFactor" SG_ 2533738497 L_UWB_FRNK_FD_Crc4Val 0;
BA_ "UserSigValidity" SG_ 2533738497 L_UWB_FRNK_FD_Crc4Val 3;
BA_ "GenSigStartValue" SG_ 2533738497 L_UWB_FRNK_FD_Crc4Val 65535;
BA_ "GenSigSendType" SG_ 2533738497 L_UWB_FRNK_FD_Crc4Val 2;
BA_ "Description" SG_ 2533738497 L_UWB_FRNK_FD_Crc4Val "The data area for CRC calculation is based on the data length (DLC) of the message DB.

The CRC shall be calculated over the entire data block (excluding the CRC bytes) including the user data, alive counter and Data ID



- CRC Polynomial (0x1021) , Ini";
BA_ "Version" SG_ 2533738497 L_UWB_FRNK_FD_AlvCnt4Val "24.07.05";
BA_ "RoutingFactor" SG_ 2533738497 L_UWB_FRNK_FD_AlvCnt4Val 0;
BA_ "UserSigValidity" SG_ 2533738497 L_UWB_FRNK_FD_AlvCnt4Val 3;
BA_ "GenSigSendType" SG_ 2533738497 L_UWB_FRNK_FD_AlvCnt4Val 2;
BA_ "Description" SG_ 2533738497 L_UWB_FRNK_FD_AlvCnt4Val "For the first transmission request for a data element the counter shall be initialized with 0 and shall be incremented by 1 for every subsequent send request. 

When the counter reaches the maximum value(0xFF), then it shall restart with 0 for the next s";
BA_ "Version" SG_ 2533738497 FRNK_SWID_3_IVD_1 "24.07.05";
BA_ "RoutingFactor" SG_ 2533738497 FRNK_SWID_3_IVD_1 0;
BA_ "UserSigValidity" SG_ 2533738497 FRNK_SWID_3_IVD_1 0;
BA_ "GenSigSendType" SG_ 2533738497 FRNK_SWID_3_IVD_1 2;
BA_ "Version" SG_ 2529540097 L_UWB_RR_FD_Crc4Val "24.07.05";
BA_ "RoutingFactor" SG_ 2529540097 L_UWB_RR_FD_Crc4Val 0;
BA_ "UserSigValidity" SG_ 2529540097 L_UWB_RR_FD_Crc4Val 3;
BA_ "GenSigStartValue" SG_ 2529540097 L_UWB_RR_FD_Crc4Val 65535;
BA_ "GenSigSendType" SG_ 2529540097 L_UWB_RR_FD_Crc4Val 2;
BA_ "Description" SG_ 2529540097 L_UWB_RR_FD_Crc4Val "The data area for CRC calculation is based on the data length (DLC) of the message DB.

The CRC shall be calculated over the entire data block (excluding the CRC bytes) including the user data, alive counter and Data ID



- CRC Polynomial (0x1021) , Ini";
BA_ "Version" SG_ 2529540097 L_UWB_RR_FD_AlvCnt4Val "24.07.05";
BA_ "RoutingFactor" SG_ 2529540097 L_UWB_RR_FD_AlvCnt4Val 0;
BA_ "UserSigValidity" SG_ 2529540097 L_UWB_RR_FD_AlvCnt4Val 3;
BA_ "GenSigSendType" SG_ 2529540097 L_UWB_RR_FD_AlvCnt4Val 2;
BA_ "Description" SG_ 2529540097 L_UWB_RR_FD_AlvCnt4Val "For the first transmission request for a data element the counter shall be initialized with 0 and shall be incremented by 1 for every subsequent send request. 

When the counter reaches the maximum value(0xFF), then it shall restart with 0 for the next s";
BA_ "Version" SG_ 2529540097 RR_SWID_3_IVD_1 "24.07.05";
BA_ "RoutingFactor" SG_ 2529540097 RR_SWID_3_IVD_1 0;
BA_ "UserSigValidity" SG_ 2529540097 RR_SWID_3_IVD_1 0;
BA_ "GenSigSendType" SG_ 2529540097 RR_SWID_3_IVD_1 2;
BA_ "Version" SG_ 1337 UWB_RR_FD_Crc30Val "24.05.05";
BA_ "UserSigValidity" SG_ 1337 UWB_RR_FD_Crc30Val 3;
BA_ "GenSigStartValue" SG_ 1337 UWB_RR_FD_Crc30Val 65535;
BA_ "GenSigSendType" SG_ 1337 UWB_RR_FD_Crc30Val 4;
BA_ "Description" SG_ 1337 UWB_RR_FD_Crc30Val "The data area for CRC calculation is based on the data length (DLC) of the message DB.

The CRC shall be calculated over the entire data block (excluding the CRC bytes) including the user data, alive counter and Data ID



- CRC Polynomial (0x1021) , Ini";
BA_ "Version" SG_ 1337 UWB_RR_FD_AlvCnt30Val "24.05.05";
BA_ "UserSigValidity" SG_ 1337 UWB_RR_FD_AlvCnt30Val 3;
BA_ "GenSigSendType" SG_ 1337 UWB_RR_FD_AlvCnt30Val 4;
BA_ "Description" SG_ 1337 UWB_RR_FD_AlvCnt30Val "For the first transmission request for a data element the counter shall be initialized with 0 and shall be incremented by 1 for every subsequent send request. 

When the counter reaches the maximum value(0xFF), then it shall restart with 0 for the next s";
BA_ "Version" SG_ 1337 UWB_RR_ResetOpsta "24.05.05";
BA_ "UserSigValidity" SG_ 1337 UWB_RR_ResetOpsta 0;
BA_ "GenSigSendType" SG_ 1337 UWB_RR_ResetOpsta 4;
BA_ "Description" SG_ 1337 UWB_RR_ResetOpsta "This signal indicates whether the reset operation has been completed or not";
BA_ "Version" SG_ 1336 UWB_RL_FD_Crc30Val "24.05.07";
BA_ "UserSigValidity" SG_ 1336 UWB_RL_FD_Crc30Val 3;
BA_ "GenSigStartValue" SG_ 1336 UWB_RL_FD_Crc30Val 65535;
BA_ "GenSigSendType" SG_ 1336 UWB_RL_FD_Crc30Val 4;
BA_ "Description" SG_ 1336 UWB_RL_FD_Crc30Val "The data area for CRC calculation is based on the data length (DLC) of the message DB.

The CRC shall be calculated over the entire data block (excluding the CRC bytes) including the user data, alive counter and Data ID



- CRC Polynomial (0x1021) , Ini";
BA_ "Version" SG_ 1336 UWB_RL_FD_AlvCnt30Val "24.05.07";
BA_ "UserSigValidity" SG_ 1336 UWB_RL_FD_AlvCnt30Val 3;
BA_ "GenSigSendType" SG_ 1336 UWB_RL_FD_AlvCnt30Val 4;
BA_ "Description" SG_ 1336 UWB_RL_FD_AlvCnt30Val "For the first transmission request for a data element the counter shall be initialized with 0 and shall be incremented by 1 for every subsequent send request. 

When the counter reaches the maximum value(0xFF), then it shall restart with 0 for the next s";
BA_ "Version" SG_ 1336 UWB_RL_ResetOpsta "24.05.07";
BA_ "UserSigValidity" SG_ 1336 UWB_RL_ResetOpsta 0;
BA_ "GenSigSendType" SG_ 1336 UWB_RL_ResetOpsta 4;
BA_ "Description" SG_ 1336 UWB_RL_ResetOpsta "This signal indicates whether the reset operation has been completed or not";
BA_ "Version" SG_ 850 IAU_FD_Crc5Val "22.11.04";
BA_ "UserSigValidity" SG_ 850 IAU_FD_Crc5Val 0;
BA_ "GenSigStartValue" SG_ 850 IAU_FD_Crc5Val 65535;
BA_ "GenSigSendType" SG_ 850 IAU_FD_Crc5Val 4;
BA_ "Description" SG_ 850 IAU_FD_Crc5Val "The data area for CRC calculation is based on the data length (DLC) of the message DB.

The CRC shall be calculated over the entire data block (excluding the CRC bytes) including the user data, alive counter and Data ID



- CRC Polynomial (0x1021) , Ini";
BA_ "Version" SG_ 850 IAU_DigitalKeyProfileRval_Copy_0 "20.05.02";
BA_ "NetworkRequestHoldingTime" SG_ 850 IAU_DigitalKeyProfileRval_Copy_0 5000;
BA_ "NetworkRequest" SG_ 850 IAU_DigitalKeyProfileRval_Copy_0 0;
BA_ "UserSigValidity" SG_ 850 IAU_DigitalKeyProfileRval_Copy_0 0;
BA_ "GenSigSendType" SG_ 850 IAU_DigitalKeyProfileRval_Copy_0 4;
BA_ "Version" SG_ 850 IAU_SharedPhnRegStat_Copy_0 "20.05.02";
BA_ "NetworkRequestHoldingTime" SG_ 850 IAU_SharedPhnRegStat_Copy_0 5000;
BA_ "NetworkRequest" SG_ 850 IAU_SharedPhnRegStat_Copy_0 0;
BA_ "UserSigValidity" SG_ 850 IAU_SharedPhnRegStat_Copy_0 0;
BA_ "GenSigSendType" SG_ 850 IAU_SharedPhnRegStat_Copy_0 4;
BA_ "Version" SG_ 850 IAU_CardKeyEnblRVal_Copy_0 "20.08.00";
BA_ "NetworkRequestHoldingTime" SG_ 850 IAU_CardKeyEnblRVal_Copy_0 5000;
BA_ "NetworkRequest" SG_ 850 IAU_CardKeyEnblRVal_Copy_0 0;
BA_ "UserSigValidity" SG_ 850 IAU_CardKeyEnblRVal_Copy_0 0;
BA_ "GenSigSendType" SG_ 850 IAU_CardKeyEnblRVal_Copy_0 4;
BA_ "Description" SG_ 850 IAU_CardKeyEnblRVal_Copy_0 "Card Key Function Enable / Disable flag";
BA_ "Version" SG_ 850 IAU_DrvDHLPhnDetect_Copy_0 "21.08.01";
BA_ "NetworkRequestHoldingTime" SG_ 850 IAU_DrvDHLPhnDetect_Copy_0 5000;
BA_ "NetworkRequest" SG_ 850 IAU_DrvDHLPhnDetect_Copy_0 0;
BA_ "UserSigValidity" SG_ 850 IAU_DrvDHLPhnDetect_Copy_0 0;
BA_ "GenSigSendType" SG_ 850 IAU_DrvDHLPhnDetect_Copy_0 4;
BA_ "Description" SG_ 850 IAU_DrvDHLPhnDetect_Copy_0 "Front Door Left Doorhandle";
BA_ "Version" SG_ 850 IAU_AstDHLPhnDetect_Copy_0 "21.08.01";
BA_ "NetworkRequestHoldingTime" SG_ 850 IAU_AstDHLPhnDetect_Copy_0 5000;
BA_ "NetworkRequest" SG_ 850 IAU_AstDHLPhnDetect_Copy_0 0;
BA_ "UserSigValidity" SG_ 850 IAU_AstDHLPhnDetect_Copy_0 0;
BA_ "GenSigSendType" SG_ 850 IAU_AstDHLPhnDetect_Copy_0 4;
BA_ "Description" SG_ 850 IAU_AstDHLPhnDetect_Copy_0 "Front Right Door Handle";
BA_ "Version" SG_ 850 IAU_RLDHLPhnDetect_Copy_0 "21.08.01";
BA_ "NetworkRequestHoldingTime" SG_ 850 IAU_RLDHLPhnDetect_Copy_0 5000;
BA_ "NetworkRequest" SG_ 850 IAU_RLDHLPhnDetect_Copy_0 0;
BA_ "UserSigValidity" SG_ 850 IAU_RLDHLPhnDetect_Copy_0 0;
BA_ "GenSigSendType" SG_ 850 IAU_RLDHLPhnDetect_Copy_0 4;
BA_ "Description" SG_ 850 IAU_RLDHLPhnDetect_Copy_0 "Rear Left Door Handle";
BA_ "Version" SG_ 850 IAU_RRDHLPhnDetect_Copy_0 "21.08.01";
BA_ "NetworkRequestHoldingTime" SG_ 850 IAU_RRDHLPhnDetect_Copy_0 5000;
BA_ "NetworkRequest" SG_ 850 IAU_RRDHLPhnDetect_Copy_0 0;
BA_ "UserSigValidity" SG_ 850 IAU_RRDHLPhnDetect_Copy_0 0;
BA_ "GenSigSendType" SG_ 850 IAU_RRDHLPhnDetect_Copy_0 4;
BA_ "Description" SG_ 850 IAU_RRDHLPhnDetect_Copy_0 "Rear Right Door handle";
BA_ "Version" SG_ 850 IAU_Manufacturer_Copy_0 "21.07.05";
BA_ "NetworkRequestHoldingTime" SG_ 850 IAU_Manufacturer_Copy_0 5000;
BA_ "NetworkRequest" SG_ 850 IAU_Manufacturer_Copy_0 0;
BA_ "UserSigValidity" SG_ 850 IAU_Manufacturer_Copy_0 0;
BA_ "GenSigSendType" SG_ 850 IAU_Manufacturer_Copy_0 4;
BA_ "Description" SG_ 850 IAU_Manufacturer_Copy_0 "The Manufacturer Code of IAU by HMC";
BA_ "Version" SG_ 850 IAU_VendorCode_Copy_0 "21.07.05";
BA_ "NetworkRequestHoldingTime" SG_ 850 IAU_VendorCode_Copy_0 5000;
BA_ "NetworkRequest" SG_ 850 IAU_VendorCode_Copy_0 0;
BA_ "UserSigValidity" SG_ 850 IAU_VendorCode_Copy_0 0;
BA_ "GenSigSendType" SG_ 850 IAU_VendorCode_Copy_0 4;
BA_ "Description" SG_ 850 IAU_VendorCode_Copy_0 "Vendor code of IAU manufacturer";
BA_ "Version" SG_ 850 IAU_FD_AlvCnt5Val "22.11.04";
BA_ "UserSigValidity" SG_ 850 IAU_FD_AlvCnt5Val 0;
BA_ "GenSigSendType" SG_ 850 IAU_FD_AlvCnt5Val 4;
BA_ "Description" SG_ 850 IAU_FD_AlvCnt5Val "For the first transmission request for a data element the counter shall be initialized with 0 and shall be incremented by 1 for every subsequent send request. 

When the counter reaches the maximum value(0xFF), then it shall restart with 0 for the next s";
BA_ "Version" SG_ 850 IAU_Serial_Copy_0 "21.07.05";
BA_ "NetworkRequestHoldingTime" SG_ 850 IAU_Serial_Copy_0 5000;
BA_ "NetworkRequest" SG_ 850 IAU_Serial_Copy_0 0;
BA_ "UserSigValidity" SG_ 850 IAU_Serial_Copy_0 0;
BA_ "GenSigSendType" SG_ 850 IAU_Serial_Copy_0 4;
BA_ "Description" SG_ 850 IAU_Serial_Copy_0 "Production Serial Number of IAU";
BA_ "Version" SG_ 850 IAU_Year_Copy_0 "21.07.05";
BA_ "NetworkRequestHoldingTime" SG_ 850 IAU_Year_Copy_0 5000;
BA_ "NetworkRequest" SG_ 850 IAU_Year_Copy_0 0;
BA_ "UserSigValidity" SG_ 850 IAU_Year_Copy_0 0;
BA_ "GenSigSendType" SG_ 850 IAU_Year_Copy_0 4;
BA_ "Description" SG_ 850 IAU_Year_Copy_0 "The Production Year of IAU";
BA_ "Version" SG_ 850 IAU_Month_Copy_0 "21.07.05";
BA_ "NetworkRequestHoldingTime" SG_ 850 IAU_Month_Copy_0 5000;
BA_ "NetworkRequest" SG_ 850 IAU_Month_Copy_0 0;
BA_ "UserSigValidity" SG_ 850 IAU_Month_Copy_0 0;
BA_ "GenSigSendType" SG_ 850 IAU_Month_Copy_0 4;
BA_ "Description" SG_ 850 IAU_Month_Copy_0 "The Production Month of IAU";
BA_ "Version" SG_ 850 IAU_Date_Copy_0 "21.07.05";
BA_ "NetworkRequestHoldingTime" SG_ 850 IAU_Date_Copy_0 5000;
BA_ "NetworkRequest" SG_ 850 IAU_Date_Copy_0 0;
BA_ "UserSigValidity" SG_ 850 IAU_Date_Copy_0 0;
BA_ "GenSigSendType" SG_ 850 IAU_Date_Copy_0 4;
BA_ "Description" SG_ 850 IAU_Date_Copy_0 "The Production Date of IAU";
BA_ "Version" SG_ 850 IAU_SWVerMajor1_Copy_0 "20.12.04";
BA_ "UserSigValidity" SG_ 850 IAU_SWVerMajor1_Copy_0 0;
BA_ "GenSigSendType" SG_ 850 IAU_SWVerMajor1_Copy_0 4;
BA_ "Description" SG_ 850 IAU_SWVerMajor1_Copy_0 "Indicate the IAU software version as follows:

- The software version is displayed in three digits.

- The Major and Minor digits are separated by '.'

- Signal values are transmitted to ASCII codes.



б╪ Example

IAU_SWVerMajor1 : 0x41 (HEX) -> ASCII C";
BA_ "Version" SG_ 850 IAU_DrvDhsRainStat "24.01.06";
BA_ "UserSigValidity" SG_ 850 IAU_DrvDhsRainStat 0;
BA_ "GenSigSendType" SG_ 850 IAU_DrvDhsRainStat 4;
BA_ "Description" SG_ 850 IAU_DrvDhsRainStat "Routing signal from DHL_Rain_Sta (L-CAN)";
BA_ "Version" SG_ 850 IAU_SWVerMinor1_Copy_0 "18.10.06";
BA_ "UserSigValidity" SG_ 850 IAU_SWVerMinor1_Copy_0 0;
BA_ "GenSigSendType" SG_ 850 IAU_SWVerMinor1_Copy_0 4;
BA_ "Description" SG_ 850 IAU_SWVerMinor1_Copy_0 "Indicate the IAU software version as follows:

- The software version is displayed in three digits.

- The Major and Minor digits are separated by '.'

- Signal values are transmitted to ASCII codes.



б╪ Example

IAU_SWVerMajor1 : 0x41 (HEX) -> ASCII C";
BA_ "Version" SG_ 850 IAU_SWVerMinor2_Copy_0 "18.10.06";
BA_ "UserSigValidity" SG_ 850 IAU_SWVerMinor2_Copy_0 0;
BA_ "GenSigSendType" SG_ 850 IAU_SWVerMinor2_Copy_0 4;
BA_ "Description" SG_ 850 IAU_SWVerMinor2_Copy_0 "Indicate the IAU software version as follows:

- The software version is displayed in three digits.

- The Major and Minor digits are separated by '.'

- Signal values are transmitted to ASCII codes.



б╪ Example

IAU_SWVerMajor1 : 0x41 (HEX) -> ASCII C";
BA_ "Version" SG_ 850 IAU_AstDhsRainStat "24.01.06";
BA_ "UserSigValidity" SG_ 850 IAU_AstDhsRainStat 0;
BA_ "GenSigSendType" SG_ 850 IAU_AstDhsRainStat 4;
BA_ "Description" SG_ 850 IAU_AstDhsRainStat "Routing signal from DHR_Rain_Sta (L-CAN)";
BA_ "Version" SG_ 850 IAU_RLDhsRainStat "24.01.06";
BA_ "UserSigValidity" SG_ 850 IAU_RLDhsRainStat 0;
BA_ "GenSigSendType" SG_ 850 IAU_RLDhsRainStat 4;
BA_ "Description" SG_ 850 IAU_RLDhsRainStat "Routing signal from DHRL_Rain_Sta (L-CAN)";
BA_ "Version" SG_ 850 IAU_RRDhsRainStat "24.01.06";
BA_ "UserSigValidity" SG_ 850 IAU_RRDhsRainStat 0;
BA_ "GenSigSendType" SG_ 850 IAU_RRDhsRainStat 4;
BA_ "Description" SG_ 850 IAU_RRDhsRainStat "Routing signal from DHRR_Rain_Sta (L-CAN)";
BA_ "Version" SG_ 1821 DHR_GST_Byte0 "22.07.01";
BA_ "NetworkRequestHoldingTime" SG_ 1821 DHR_GST_Byte0 5000;
BA_ "NetworkRequest" SG_ 1821 DHR_GST_Byte0 0;
BA_ "UserSigValidity" SG_ 1821 DHR_GST_Byte0 0;
BA_ "UsrSigPurpose" SG_ 1821 DHR_GST_Byte0 4;
BA_ "Description" SG_ 1821 DHR_GST_Byte0 "TP Index : 183";
BA_ "Version" SG_ 1821 DHR_GST_Byte2 "22.07.01";
BA_ "NetworkRequestHoldingTime" SG_ 1821 DHR_GST_Byte2 5000;
BA_ "NetworkRequest" SG_ 1821 DHR_GST_Byte2 0;
BA_ "UserSigValidity" SG_ 1821 DHR_GST_Byte2 0;
BA_ "UsrSigPurpose" SG_ 1821 DHR_GST_Byte2 4;
BA_ "Description" SG_ 1821 DHR_GST_Byte2 "TP Index : 183";
BA_ "Version" SG_ 1821 DHR_GST_Byte3 "22.07.01";
BA_ "NetworkRequestHoldingTime" SG_ 1821 DHR_GST_Byte3 5000;
BA_ "NetworkRequest" SG_ 1821 DHR_GST_Byte3 0;
BA_ "UserSigValidity" SG_ 1821 DHR_GST_Byte3 0;
BA_ "UsrSigPurpose" SG_ 1821 DHR_GST_Byte3 4;
BA_ "Description" SG_ 1821 DHR_GST_Byte3 "TP Index : 183";
BA_ "Version" SG_ 1821 DHR_GST_Byte4 "22.07.01";
BA_ "NetworkRequestHoldingTime" SG_ 1821 DHR_GST_Byte4 5000;
BA_ "NetworkRequest" SG_ 1821 DHR_GST_Byte4 0;
BA_ "UserSigValidity" SG_ 1821 DHR_GST_Byte4 0;
BA_ "UsrSigPurpose" SG_ 1821 DHR_GST_Byte4 4;
BA_ "Description" SG_ 1821 DHR_GST_Byte4 "TP Index : 183";
BA_ "Version" SG_ 1821 DHR_GST_Byte5 "22.07.01";
BA_ "NetworkRequestHoldingTime" SG_ 1821 DHR_GST_Byte5 5000;
BA_ "NetworkRequest" SG_ 1821 DHR_GST_Byte5 0;
BA_ "UserSigValidity" SG_ 1821 DHR_GST_Byte5 0;
BA_ "UsrSigPurpose" SG_ 1821 DHR_GST_Byte5 4;
BA_ "Description" SG_ 1821 DHR_GST_Byte5 "TP Index : 183";
BA_ "Version" SG_ 1821 DHR_GST_Byte6 "22.07.01";
BA_ "NetworkRequestHoldingTime" SG_ 1821 DHR_GST_Byte6 5000;
BA_ "NetworkRequest" SG_ 1821 DHR_GST_Byte6 0;
BA_ "UserSigValidity" SG_ 1821 DHR_GST_Byte6 0;
BA_ "UsrSigPurpose" SG_ 1821 DHR_GST_Byte6 4;
BA_ "Description" SG_ 1821 DHR_GST_Byte6 "TP Index : 183";
BA_ "Version" SG_ 1821 DHR_GST_Byte7 "22.07.01";
BA_ "NetworkRequestHoldingTime" SG_ 1821 DHR_GST_Byte7 5000;
BA_ "NetworkRequest" SG_ 1821 DHR_GST_Byte7 0;
BA_ "UserSigValidity" SG_ 1821 DHR_GST_Byte7 0;
BA_ "UsrSigPurpose" SG_ 1821 DHR_GST_Byte7 4;
BA_ "Description" SG_ 1821 DHR_GST_Byte7 "TP Index : 183";
BA_ "Version" SG_ 1821 DHR_GST_Byte1 "22.07.01";
BA_ "NetworkRequestHoldingTime" SG_ 1821 DHR_GST_Byte1 5000;
BA_ "NetworkRequest" SG_ 1821 DHR_GST_Byte1 0;
BA_ "UserSigValidity" SG_ 1821 DHR_GST_Byte1 0;
BA_ "UsrSigPurpose" SG_ 1821 DHR_GST_Byte1 4;
BA_ "Description" SG_ 1821 DHR_GST_Byte1 "TP Index : 183";
BA_REL_ "GenSigTimeoutTime" BU_SG_REL_ L_UWB_BLE_MST_FD SG_ 830 Warn_RrLftDrSwSta_SBCM_Copy_0 1500;
BA_REL_ "GenSigTimeoutTime" BU_SG_REL_ L_UWB_BLE_MST_FD SG_ 830 DoorLock_RrLftDrUnLkSta_SBCM_Cop 1500;
BA_REL_ "GenSigTimeoutTime" BU_SG_REL_ L_UWB_BLE_MST_FD SG_ 813 Latch_TypeOption_DRV_Copy_0 1500;
BA_REL_ "GenSigTimeoutTime" BU_SG_REL_ L_UWB_BLE_MST_FD SG_ 813 Warn_HoodSwSta_SBCM_Copy_0 1500;
BA_REL_ "GenSigTimeoutTime" BU_SG_REL_ L_UWB_BLE_MST_FD SG_ 813 Hood_TypeOption_Copy_0 1500;
BA_REL_ "GenSigTimeoutTime" BU_SG_REL_ L_UWB_BLE_MST_FD SG_ 813 Warn_DrvDrSwSta_SBCM_Copy_0 1500;
BA_REL_ "GenSigTimeoutTime" BU_SG_REL_ L_UWB_BLE_MST_FD SG_ 813 DoorLock_DrvDrUnLkSta_SBCM_Copy_ 1500;
BA_REL_ "GenSigTimeoutTime" BU_SG_REL_ L_UWB_BLE_MST_FD SG_ 811 Warn_AsstDrSwSta_SBCM_Copy_0 1500;
BA_REL_ "GenSigTimeoutTime" BU_SG_REL_ L_UWB_BLE_MST_FD SG_ 2525341953 FR_SWID_3_IVD_2 0;
BA_REL_ "GenSigTimeoutTime" BU_SG_REL_ L_EDT_FD SG_ 2521141761 MST_DTC 1500;
BA_REL_ "GenSigTimeoutTime" BU_SG_REL_ L_EDT_FD SG_ 2521141761 MST_DTC_BLE 1500;
BA_REL_ "GenSigTimeoutTime" BU_SG_REL_ GW_BDC_FD SG_ 2521141761 Pulse_Shape_Combo_Info 1500;
BA_REL_ "GenSigTimeoutTime" BU_SG_REL_ L_EDT_FD SG_ 2521141761 Pulse_Shape_Combo_Info 1500;
BA_REL_ "GenSigTimeoutTime" BU_SG_REL_ GW_BDC_FD SG_ 2214592770 UWB_RR_Ranging_Enc_Result2 0;
BA_REL_ "GenSigTimeoutTime" BU_SG_REL_ L_UWB_BLE_MST_FD SG_ 2214592770 UWB_RR_Ranging_Enc_Result2 0;
BA_REL_ "GenSigTimeoutTime" BU_SG_REL_ GW_BDC_FD SG_ 2214592770 UWB_RR_Ranging_Enc_Result 0;
BA_REL_ "GenSigTimeoutTime" BU_SG_REL_ L_UWB_BLE_MST_FD SG_ 2214592770 UWB_RR_Ranging_Enc_Result 0;
BA_REL_ "GenSigTimeoutTime" BU_SG_REL_ GW_BDC_FD SG_ 2214592768 UWB_RR_UWB_Decrypt_FB 0;
BA_REL_ "GenSigTimeoutTime" BU_SG_REL_ L_UWB_BLE_MST_FD SG_ 2214592768 UWB_RR_MST_Decrypt_FB 0;
BA_REL_ "GenSigTimeoutTime" BU_SG_REL_ L_UWB_BLE_MST_FD SG_ 2214592768 UWB_RR_OTA_Rsp 0;
BA_REL_ "GenSigTimeoutTime" BU_SG_REL_ L_EDT_FD SG_ 2214592768 UWB_RR_UWB_IC_Status 0;
BA_REL_ "GenSigTimeoutTime" BU_SG_REL_ L_EDT_FD SG_ 2683310106 Devmsg_FD_1_TX 0;
BA_REL_ "GenSigTimeoutTime" BU_SG_REL_ L_UWB_BLE_MST_FD SG_ 2683310106 Devmsg_FD_1_TX 0;
BA_REL_ "GenSigTimeoutTime" BU_SG_REL_ GW_BDC_FD SG_ 2214592769 UWB_RR_FOB_RSD_Enc_Result 0;
BA_REL_ "GenSigTimeoutTime" BU_SG_REL_ L_EDT_FD SG_ 2214592783 UWB_RR_Dvp_Data 0;
BA_REL_ "GenSigTimeoutTime" BU_SG_REL_ L_ROA_FD SG_ 2281701456 BodyType_Sta 1500;
BA_REL_ "GenSigTimeoutTime" BU_SG_REL_ L_ROA_FR_FD SG_ 2281701456 BodyType_Sta 1500;
BA_REL_ "GenSigTimeoutTime" BU_SG_REL_ L_UWB_BLE_MST_FD SG_ 2281701456 BodyType_Sta 1500;
BA_REL_ "GenSigTimeoutTime" BU_SG_REL_ L_UWB_BLE_MST_FD SG_ 2281701456 Trunk_Tailgate_Info 1500;
BA_REL_ "GenSigTimeoutTime" BU_SG_REL_ L_DHL_FD SG_ 2281701456 BDC_TP_CAN_Sta 1500;
BA_REL_ "GenSigTimeoutTime" BU_SG_REL_ L_DHRL_FD SG_ 2281701456 BDC_TP_CAN_Sta 1500;
BA_REL_ "GenSigTimeoutTime" BU_SG_REL_ L_DHRR_FD SG_ 2281701456 BDC_TP_CAN_Sta 1500;
BA_REL_ "GenSigTimeoutTime" BU_SG_REL_ L_DHR_FD SG_ 2281701456 BDC_TP_CAN_Sta 1500;
BA_REL_ "GenSigTimeoutTime" BU_SG_REL_ L_UWB_BLE_MST_FD SG_ 2281701456 BDC_TP_CAN_Sta 1500;
BA_REL_ "GenSigTimeoutTime" BU_SG_REL_ L_UWB_BLE_SLV_FD SG_ 2281701456 BDC_TP_CAN_Sta 1500;
BA_REL_ "GenSigTimeoutTime" BU_SG_REL_ L_UWB_FL_FD SG_ 2281701456 BDC_TP_CAN_Sta 1500;
BA_REL_ "GenSigTimeoutTime" BU_SG_REL_ L_UWB_FRNK_FD SG_ 2281701456 BDC_TP_CAN_Sta 1500;
BA_REL_ "GenSigTimeoutTime" BU_SG_REL_ L_UWB_FR_FD SG_ 2281701456 BDC_TP_CAN_Sta 1500;
BA_REL_ "GenSigTimeoutTime" BU_SG_REL_ L_UWB_RL_FD SG_ 2281701456 BDC_TP_CAN_Sta 1500;
BA_REL_ "GenSigTimeoutTime" BU_SG_REL_ L_UWB_RR_FD SG_ 2281701456 BDC_TP_CAN_Sta 1500;
BA_REL_ "GenSigTimeoutTime" BU_SG_REL_ L_UWB_TRNK_FD SG_ 2281701456 BDC_TP_CAN_Sta 1500;
BA_REL_ "GenSigTimeoutTime" BU_SG_REL_ L_WPC_FD SG_ 2281701456 BDC_TP_CAN_Sta 1500;
BA_REL_ "GenSigTimeoutTime" BU_SG_REL_ L_UWB_BLE_MST_FD SG_ 2281701456 OPAdv_On_Cmd 1500;
BA_REL_ "GenSigTimeoutTime" BU_SG_REL_ L_UWB_BLE_SLV_FD SG_ 2281701456 OPAdv_On_Cmd 1500;
BA_REL_ "GenSigTimeoutTime" BU_SG_REL_ L_WPC_FD SG_ 2281701456 OPAdv_On_Cmd 1500;
BA_REL_ "GenSigTimeoutTime" BU_SG_REL_ L_WPC_FD SG_ 2281701456 WPC_Device_On_Cmd 1500;
BA_REL_ "GenSigTimeoutTime" BU_SG_REL_ L_ROA_FD SG_ 2281701456 RgnTyp_Opt 1500;
BA_REL_ "GenSigTimeoutTime" BU_SG_REL_ L_ROA_FR_FD SG_ 2281701456 RgnTyp_Opt 1500;
BA_REL_ "GenSigTimeoutTime" BU_SG_REL_ L_UWB_BLE_MST_FD SG_ 2281701456 RgnTyp_Opt 1500;
BA_REL_ "GenSigTimeoutTime" BU_SG_REL_ L_UWB_BLE_SLV_FD SG_ 2281701456 RgnTyp_Opt 1500;
BA_REL_ "GenSigTimeoutTime" BU_SG_REL_ L_ROA_FD SG_ 2281701456 SunRoofTyp_Opt 1500;
BA_REL_ "GenSigTimeoutTime" BU_SG_REL_ L_ROA_FR_FD SG_ 2281701456 SunRoofTyp_Opt 1500;
BA_REL_ "GenSigTimeoutTime" BU_SG_REL_ L_UWB_BLE_MST_FD SG_ 2281701456 SunRoofTyp_Opt 1500;
BA_REL_ "GenSigTimeoutTime" BU_SG_REL_ L_UWB_BLE_MST_FD SG_ 2281701456 BDC_RSPA_DKID 1500;
BA_REL_ "GenSigTimeoutTime" BU_SG_REL_ L_UWB_BLE_SLV_FD SG_ 2281701456 BDC_RSPA_DKID 1500;
BA_REL_ "GenSigTimeoutTime" BU_SG_REL_ L_UWB_BLE_MST_FD SG_ 2281701457 UWB_Ranging_RndNum 1500;
BA_REL_ "GenSigTimeoutTime" BU_SG_REL_ GW_BDC_FD SG_ 2683310089 Devmsg_FD_IAU_2_RX 0;
BA_REL_ "GenSigTimeoutTime" BU_SG_REL_ GW_BDC_FD SG_ 2214592786 UWB_TRNK_Ranging_Enc_Result2 0;
BA_REL_ "GenSigTimeoutTime" BU_SG_REL_ L_UWB_BLE_MST_FD SG_ 2214592786 UWB_TRNK_Ranging_Enc_Result2 0;
BA_REL_ "GenSigTimeoutTime" BU_SG_REL_ GW_BDC_FD SG_ 2214592786 UWB_TRNK_Ranging_Enc_Result 0;
BA_REL_ "GenSigTimeoutTime" BU_SG_REL_ L_UWB_BLE_MST_FD SG_ 2214592786 UWB_TRNK_Ranging_Enc_Result 0;
BA_REL_ "GenSigTimeoutTime" BU_SG_REL_ GW_BDC_FD SG_ 2214592785 UWB_TRNK_FOB_RSD_Enc_Result 0;
BA_REL_ "GenSigTimeoutTime" BU_SG_REL_ GW_BDC_FD SG_ 2214592784 UWB_TRNK_UWB_Decrypt_FB 0;
BA_REL_ "GenSigTimeoutTime" BU_SG_REL_ L_UWB_BLE_MST_FD SG_ 2214592784 UWB_TRNK_MST_Decrypt_FB 0;
BA_REL_ "GenSigTimeoutTime" BU_SG_REL_ L_UWB_BLE_MST_FD SG_ 2214592784 UWB_TRNK_OTA_Rsp 0;
BA_REL_ "GenSigTimeoutTime" BU_SG_REL_ L_EDT_FD SG_ 2214592784 UWB_TRNK_UWB_IC_Status 0;
BA_REL_ "GenSigTimeoutTime" BU_SG_REL_ L_EDT_FD SG_ 2214592799 UWB_TRNK_Dvp_Data 0;
BA_REL_ "GenSigTimeoutTime" BU_SG_REL_ GW_BDC_FD SG_ 2683310087 Devmsg_FD_IAU_1_RX 0;
BA_REL_ "GenSigTimeoutTime" BU_SG_REL_ L_UWB_BLE_MST_FD SG_ 2533738497 FRNK_SWID_3_IVD_1 0;
BA_REL_ "GenSigTimeoutTime" BU_SG_REL_ L_UWB_BLE_MST_FD SG_ 2529540097 RR_SWID_3_IVD_1 0;
BA_REL_ "GenSigTimeoutTime" BU_SG_REL_ GW_BDC_FD SG_ 1337 UWB_RR_ResetOpsta 5000;
BA_REL_ "GenSigTimeoutTime" BU_SG_REL_ GW_BDC_FD SG_ 1336 UWB_RL_ResetOpsta 5000;
BA_REL_ "GenSigTimeoutTime" BU_SG_REL_ L_DHL_FD SG_ 850 IAU_SharedPhnRegStat_Copy_0 1500;
BA_REL_ "GenSigTimeoutTime" BU_SG_REL_ L_DHRL_FD SG_ 850 IAU_SharedPhnRegStat_Copy_0 1500;
BA_REL_ "GenSigTimeoutTime" BU_SG_REL_ L_DHRR_FD SG_ 850 IAU_SharedPhnRegStat_Copy_0 1500;
BA_REL_ "GenSigTimeoutTime" BU_SG_REL_ L_DHR_FD SG_ 850 IAU_SharedPhnRegStat_Copy_0 1500;
BA_REL_ "GenSigTimeoutTime" BU_SG_REL_ L_UWB_BLE_MST_FD SG_ 850 IAU_SharedPhnRegStat_Copy_0 1500;
BA_REL_ "GenSigTimeoutTime" BU_SG_REL_ L_UWB_BLE_SLV_FD SG_ 850 IAU_SharedPhnRegStat_Copy_0 1500;
BA_REL_ "GenSigTimeoutTime" BU_SG_REL_ L_UWB_FL_FD SG_ 850 IAU_SharedPhnRegStat_Copy_0 1500;
BA_REL_ "GenSigTimeoutTime" BU_SG_REL_ L_UWB_FRNK_FD SG_ 850 IAU_SharedPhnRegStat_Copy_0 1500;
BA_REL_ "GenSigTimeoutTime" BU_SG_REL_ L_UWB_FR_FD SG_ 850 IAU_SharedPhnRegStat_Copy_0 1500;
BA_REL_ "GenSigTimeoutTime" BU_SG_REL_ L_UWB_RL_FD SG_ 850 IAU_SharedPhnRegStat_Copy_0 1500;
BA_REL_ "GenSigTimeoutTime" BU_SG_REL_ L_UWB_RR_FD SG_ 850 IAU_SharedPhnRegStat_Copy_0 1500;
BA_REL_ "GenSigTimeoutTime" BU_SG_REL_ L_UWB_TRNK_FD SG_ 850 IAU_SharedPhnRegStat_Copy_0 1500;
BA_REL_ "GenSigTimeoutTime" BU_SG_REL_ L_WPC_FD SG_ 850 IAU_SharedPhnRegStat_Copy_0 1500;
BA_REL_ "GenSigTimeoutTime" BU_SG_REL_ L_DHL_FD SG_ 850 IAU_CardKeyEnblRVal_Copy_0 1500;
BA_REL_ "GenSigTimeoutTime" BU_SG_REL_ L_DHRL_FD SG_ 850 IAU_CardKeyEnblRVal_Copy_0 1500;
BA_REL_ "GenSigTimeoutTime" BU_SG_REL_ L_DHRR_FD SG_ 850 IAU_CardKeyEnblRVal_Copy_0 1500;
BA_REL_ "GenSigTimeoutTime" BU_SG_REL_ L_DHR_FD SG_ 850 IAU_CardKeyEnblRVal_Copy_0 1500;
BA_REL_ "GenSigTimeoutTime" BU_SG_REL_ GW_BDC_FD SG_ 1821 DHR_GST_Byte0 0;
BA_REL_ "GenSigTimeoutTime" BU_SG_REL_ GW_BDC_FD SG_ 1821 DHR_GST_Byte2 0;
BA_REL_ "GenSigTimeoutTime" BU_SG_REL_ GW_BDC_FD SG_ 1821 DHR_GST_Byte3 0;
BA_REL_ "GenSigTimeoutTime" BU_SG_REL_ GW_BDC_FD SG_ 1821 DHR_GST_Byte4 0;
BA_REL_ "GenSigTimeoutTime" BU_SG_REL_ GW_BDC_FD SG_ 1821 DHR_GST_Byte5 0;
BA_REL_ "GenSigTimeoutTime" BU_SG_REL_ GW_BDC_FD SG_ 1821 DHR_GST_Byte6 0;
BA_REL_ "GenSigTimeoutTime" BU_SG_REL_ GW_BDC_FD SG_ 1821 DHR_GST_Byte7 0;
BA_REL_ "GenSigTimeoutTime" BU_SG_REL_ GW_BDC_FD SG_ 1821 DHR_GST_Byte1 0;
VAL_ 830 SBCM_RL_FD_Crc1Val 0 "0x0x0~0xFFFF:CRCValue" 65535 "0x0x0~0xFFFF:CRCValue" ;
VAL_ 830 USM_RLGhostDoorSta_Copy_0 0 "Default" 1 "Off" 2 "On" 3 "RESERVED" ;
VAL_ 830 DoorLock_PDSLkSwSta_RL_Copy_0 0 "Lock" 1 "Unlock" 2 "RESERVED" 3 "Error Indicator" ;
VAL_ 830 PDS_TypeOption_RL_Copy_0 0 "Off" 1 "On" 2 "RESERVED" 3 "Error Indicator" ;
VAL_ 830 RL_CrashMRActAlarm_Copy_0 0 "Off" 1 "On" 2 "RESERVED" 3 "Error Indicator" ;
VAL_ 830 PwrDRBuzzerOut_RL_Copy_0 0 "OFF" 1 "Open" 2 "Close" 3 "Warning" ;
VAL_ 830 PwrDRClosingRLDrSta_Copy_0 0 "Default" 1 "Close" 2 "Open" 3 "Stop(during Close)" 4 "Stop(during Open)" 5 "RESERVED" 6 "RESERVED" 7 "Invalid" ;
VAL_ 830 AFH_RL_FldUnfldSta_Copy_0 0 "Invalid" 1 "Fold" 2 "Unfold" 3 "Inprogress" ;
VAL_ 830 SBCM_RL_FD_AlvCnt1Val 0 "0x0x0~0xFF:AlvCntValue" 255 "0x0x0~0xFF:AlvCntValue" ;
VAL_ 830 DoorLock_RrLtLkOutSta_SBCM_Copy_ 0 "Off" 1 "On" 2 "Not Used" 3 "Error Indicator" ;
VAL_ 830 RrLt_DrLkRetryFail_SBCM_Copy_0 0 "Normal" 1 "Fail" 2 "RESERVED" 3 "RESERVED" ;
VAL_ 830 RL_DetectObj_warn 0 "Detect Warning OFF" 1 "Detect Warning ON" 2 "RESERVED" 3 "RESERVED" ;
VAL_ 830 RLRrDrCurtainPosition 0 "Unkown" 1 "Bottom" 2 "Mid" 3 "Top" ;
VAL_ 830 RDC_TypeOption 0 "Off" 1 "On" 2 "RESERVED" 3 "Error Indicator" ;
VAL_ 830 RLRrDrCurtainDownInitState 0 "Decalibrated" 1 "Calibrated" 2 "RESERVED" 3 "Error Indicator" ;
VAL_ 830 PwrDRBuzzerOut_RL_New 0 "OFF" 1 "Open" 2 "Close" 3 "Warning1" 4 "Warning2" ;
VAL_ 830 PwrDrSta_RrLt 0 "Unavailable" 1 "Available" 2 "RESERVED" 3 "Error Indicator" ;
VAL_ 830 SBCM_RL_SlidePosition 0 "0x0x0~0x64:0% - 100%" 100 "0x0x0~0x64:0% - 100%" 101 "0x65~0xFE:RESERVED" 254 "0x65~0xFE:RESERVED" 255 "Unknown" ;
VAL_ 830 SBCM_RL_DoorAngle 0 "0б╞ - 90б╞" 1 "0б╞ - 90б╞" 2 "0б╞ - 90б╞" 3 "0б╞ - 90б╞" 4 "0б╞ - 90б╞" 5 "0б╞ - 90б╞" 6 "0б╞ - 90б╞" 7 "0б╞ - 90б╞" 8 "0б╞ - 90б╞" 9 "0б╞ - 90б╞" 10 "0б╞ - 90б╞" 11 "0б╞ - 90б╞" 12 "0б╞ - 90б╞" 13 "0б╞ - 90б╞" 14 "0б╞ - 90б╞" 15 "0б╞ - 90б╞" 16 "0б╞ - 90б╞" 17 "0б╞ - 90б╞" 18 "0б╞ - 90б╞" 19 "0б╞ - 90б╞" 20 "0б╞ - 90б╞" 21 "0б╞ - 90б╞" 22 "0б╞ - 90б╞" 23 "0б╞ - 90б╞" 24 "0б╞ - 90б╞" 25 "0б╞ - 90б╞" 26 "0б╞ - 90б╞" 27 "0б╞ - 90б╞" 28 "0б╞ - 90б╞" 29 "0б╞ - 90б╞" 30 "0б╞ - 90б╞" 31 "0б╞ - 90б╞" 32 "0б╞ - 90б╞" 33 "0б╞ - 90б╞" 34 "0б╞ - 90б╞" 35 "0б╞ - 90б╞" 36 "0б╞ - 90б╞" 37 "0б╞ - 90б╞" 38 "0б╞ - 90б╞" 39 "0б╞ - 90б╞" 40 "0б╞ - 90б╞" 41 "0б╞ - 90б╞" 42 "0б╞ - 90б╞" 43 "0б╞ - 90б╞" 44 "0б╞ - 90б╞" 45 "0б╞ - 90б╞" 46 "0б╞ - 90б╞" 47 "0б╞ - 90б╞" 48 "0б╞ - 90б╞" 49 "0б╞ - 90б╞" 50 "0б╞ - 90б╞" 51 "0б╞ - 90б╞" 52 "0б╞ - 90б╞" 53 "0б╞ - 90б╞" 54 "0б╞ - 90б╞" 55 "0б╞ - 90б╞" 56 "0б╞ - 90б╞" 57 "0б╞ - 90б╞" 58 "0б╞ - 90б╞" 59 "0б╞ - 90б╞" 60 "0б╞ - 90б╞" 61 "0б╞ - 90б╞" 62 "0б╞ - 90б╞" 63 "0б╞ - 90б╞" 64 "0б╞ - 90б╞" 65 "0б╞ - 90б╞" 66 "0б╞ - 90б╞" 67 "0б╞ - 90б╞" 68 "0б╞ - 90б╞" 69 "0б╞ - 90б╞" 70 "0б╞ - 90б╞" 71 "0б╞ - 90б╞" 72 "0б╞ - 90б╞" 73 "0б╞ - 90б╞" 74 "0б╞ - 90б╞" 75 "0б╞ - 90б╞" 76 "0б╞ - 90б╞" 77 "0б╞ - 90б╞" 78 "0б╞ - 90б╞" 79 "0б╞ - 90б╞" 80 "0б╞ - 90б╞" 81 "0б╞ - 90б╞" 82 "0б╞ - 90б╞" 83 "0б╞ - 90б╞" 84 "0б╞ - 90б╞" 85 "0б╞ - 90б╞" 86 "0б╞ - 90б╞" 87 "0б╞ - 90б╞" 88 "0б╞ - 90б╞" 89 "0б╞ - 90б╞" 90 "0б╞ - 90б╞" 91 "Invalid" 92 "Invalid" 93 "Invalid" 94 "Invalid" 95 "Invalid" 96 "Invalid" 97 "Invalid" 98 "Invalid" 99 "Invalid" 100 "Unknown" 101 "Invalid" 102 "Invalid" 103 "Invalid" 104 "Invalid" 105 "Invalid" 106 "Invalid" 107 "Invalid" 108 "Invalid" 109 "Invalid" 110 "Invalid" 111 "Invalid" 112 "Invalid" 113 "Invalid" 114 "Invalid" 115 "Invalid" 116 "Invalid" 117 "Invalid" 118 "Invalid" 119 "Invalid" 120 "Invalid" 121 "Invalid" 122 "Invalid" 123 "Invalid" 124 "Invalid" 125 "Invalid" 126 "Invalid" 127 "Invalid" ;
VAL_ 830 RLDoorPushAlarm_Copy_0 0 "Off" 1 "On" 2 "RESERVED" 3 "Error Indicator" ;
VAL_ 830 RL_CrashUnlockCmd_Copy_0 0 "Off" 1 "Unlock(Crash)" ;
VAL_ 830 Warn_RrLftDrSwSta_SBCM_Copy_0 0 "Close" 1 "Open" 2 "RESERVED" 3 "Error Indicator" ;
VAL_ 830 DoorLock_RrLftDrUnLkSta_SBCM_Cop 0 "Lock" 1 "Unlock" 2 "RESERVED" 3 "Error Indicator" ;
VAL_ 830 RL_SEAActivated_Copy_0 0 "InActivated" 1 "Activated" 2 "RESERVED" 3 "Error Indicator" ;
VAL_ 830 RL_SEAWarn_Copy_0 0 "SEA Left Warning OFF" 1 "SEA Left Warning ON" 2 "RESERVED" 3 "RESERVED" ;
VAL_ 830 RL_SEWWarn_Copy_0 0 "SEW Left Warning OFF" 1 "SEW Left Warning ON" 2 "RESERVED" 3 "RESERVED" ;
VAL_ 830 RL_ReleaseWarn_Copy_0 0 "Release Warning OFF" 1 "Release Warning ON" 2 "RESERVED" 3 "RESERVED" ;
VAL_ 830 RL_SWFailAlarm_Copy_0 0 "Off" 1 "On" 2 "RESERVED" 3 "Error Indicator" ;
VAL_ 830 RL_ChildLock_ActnFlSta_Copy_0 0 "OK" 1 "Failed" 2 "RESERVED" 3 "Error Indicator" ;
VAL_ 830 RL_MRActivationAlarm_Copy_0 0 "Off" 1 "On" 2 "RESERVED" 3 "Error Indicator" ;
VAL_ 830 RL_ChildLock_Status_Copy_0 0 "ChildLock On" 1 "ChildLock Off" 2 "RESERVED" 3 "RESERVED" ;
VAL_ 813 SBCM_DRV_FD_Crc1Val 0 "0x0x0~0xFFFF:CRCValue" 65535 "0x0x0~0xFFFF:CRCValue" ;
VAL_ 813 Latch_TypeOption_DRV_Copy_0 0 "Off" 1 "On" 2 "RESERVED" 3 "Error Indicator" ;
VAL_ 813 DRV_SWFailAlarm_Copy_0 0 "Off" 1 "On" 2 "RESERVED" 3 "Error Indicator" ;
VAL_ 813 USM_PwrDRApprOpnSetSta_Copy_0 0 "Default" 1 "Off" 2 "On" 3 "RESERVED" ;
VAL_ 813 USM_PwrDRApprOpnSetOpt_Copy_0 0 "Default" 1 "Off" 2 "On" 3 "RESERVED" ;
VAL_ 813 USM_PwrDRCloseByRKELockSta_Copy_ 0 "Default" 1 "Off" 2 "On" 3 "RESERVED" ;
VAL_ 813 USM_PwrDRCloseByRKELockOpt_Copy_ 0 "Default" 1 "Off" 2 "On" 3 "RESERVED" ;
VAL_ 813 USM_PwrDRCloseByBrakeSta_Copy_0 0 "Default" 1 "Off" 2 "On" 3 "RESERVED" ;
VAL_ 813 USM_PwrDRCloseByBrakeOpt_Copy_0 0 "Default" 1 "Off" 2 "On" 3 "RESERVED" ;
VAL_ 813 USM_PwrDRBuzzerSta_Copy_0 0 "Default" 1 "Off" 2 "On" 3 "RESERVED" ;
VAL_ 813 USM_PwrDRBuzzerOpt_Copy_0 0 "Default" 1 "Off" 2 "On" 3 "RESERVED" ;
VAL_ 813 PDS_TypeOption_DRV_Copy_0 0 "Off" 1 "All Door" 2 "Front Only" 3 "Rear Only" ;
VAL_ 813 C_DrvDoorApproachOpen_Copy_0 0 "Default" 1 "Approach Open Request" 2 "Approach Open Stop" 3 "RESERVED" ;
VAL_ 813 C_DrvDoorApproachClose_Copy_0 0 "Default" 1 "Approach Close Request" 2 "Approach Close Stop" 3 "RESERVED" ;
VAL_ 813 DoorLock_PDSLkSwSta_DRV_Copy_0 0 "Default" 1 "Lock" 2 "RESERVED" 3 "Error Indicator" ;
VAL_ 813 SBCM_DRV_DiagSta_Copy_0 0 "Default" 1 "Normal Operation" 2 "DRV Indicator Circuit Failure" 3 "RESERVED" ;
VAL_ 813 DoorLock_CtrlDrLkUnLkSwSta_SBCM_ 0 "Off" 1 "On" 2 "RESERVED" 3 "Error Indicator" ;
VAL_ 813 SBCM_PsvDrLkReq_Copy_0 0 "None" 1 "Lock" 2 "Passive Trunk Lock" 3 "RESERVED" ;
VAL_ 813 CDMAutoWashModeSet_SBCM_Copy_0 0 "Default" 1 "CDM Auto Wash Mode Off" 2 "CDM Auto Wash Mode On" 3 "RESERVED" 4 "RESERVED" 5 "RESERVED" 6 "RESERVED" 7 "Invalid" ;
VAL_ 813 USM_DrvGhostDoorSta_Copy_0 0 "Default" 1 "Off" 2 "On" 3 "RESERVED" ;
VAL_ 813 Mirror_LH_FoldingSta_Copy_0 0 "Off" 1 "Folding" 2 "RESERVED" 3 "Error Indicator" ;
VAL_ 813 Mirror_LH_UnfoldingSta_Copy_0 0 "Off" 1 "Unfolding" 2 "RESERVED" 3 "Error Indicator" ;
VAL_ 813 DRV_CrashMRActAlarm_Copy_0 0 "Off" 1 "On" 2 "RESERVED" 3 "Error Indicator" ;
VAL_ 813 AFH_DRV_FldUnFldSta_Copy_0 0 "Invalid" 1 "Fold" 2 "Unfold" 3 "Inprogress" ;
VAL_ 813 SBCM_DRV_FD_AlvCnt1Val 0 "0x0x0~0xFF:AlvCntValue" 255 "0x0x0~0xFF:AlvCntValue" ;
VAL_ 813 MirrorFldReq_Copy_0 0 "Default" 1 "Folding Request" 2 "Unfolding Request" 3 "RESERVED" ;
VAL_ 813 OMU_TypeOption_DRV_Copy_0 0 "Off" 1 "On" 2 "RESERVED" 3 "Error Indicator" ;
VAL_ 813 IMS_OSMirPlayBackSta_LH_Copy_0 0 "Stop" 1 "Play 1" 2 "Play 2" 3 "Play 3" 4 "SmartIMS" 5 "Profile 1" 6 "Profile 2" 7 "Guest" 8 "RESERVED" 9 "RESERVED" 10 "RESERVED" 11 "RESERVED" 12 "RESERVED" 13 "RESERVED" 14 "RESERVED" 15 "Error Indicator" ;
VAL_ 813 ECMMRR_PLUS_Copy_0 0 "0x0x0~0x7D:0~1.25 V" 125 "0x0x0~0x7D:0~1.25 V" 126 "0x7E~0xFE:RESERVED" 254 "0x7E~0xFE:RESERVED" 255 "RESERVED" ;
VAL_ 813 EHL_TxInfo_SBCM_DRV_Copy_0 0 "Default" 1 "EHL_DRV_Close" 2 "EHL_DRV_Half" 3 "EHL_DRV_Open" 4 "EHL_DRV_RetryFlag" 5 "EHL_DRV_ErrorIndicator" 6 "EHL_DRV_Opening" 7 "Invalid" ;
VAL_ 813 IMS_OSMirPlayBackSta_LH_New_Copy 0 "Stop" 1 "Play 1" 2 "Play 2" 3 "Play 3" 4 "Smart IMS" 5 "Profile 1" 6 "Profile 2" 7 "Profile 3" 8 "Profile 4" 9 "Profile 5" 10 "Profile 6" 11 "Profile 7" 12 "Profile 8" 13 "Profile 9" 14 "Guest" 15 "Error Indicator" ;
VAL_ 813 CDM_InsideOpnSwSta_Copy_0 0 "Off" 1 "On" 2 "RESERVED" 3 "Error Indicator" ;
VAL_ 813 CDM_TypeOption_Copy_0 0 "Off" 1 "On" 2 "On_2EA" 3 "Error Indicator" ;
VAL_ 813 CDM_ImmeChgSw_SBCM_Copy_0 0 "Default" 1 "Off" 2 "On" 3 "RESERVED" ;
VAL_ 813 CDM_FobSrchReq_DRV_Copy_0 0 "Off" 1 "On" 2 "RESERVED" 3 "Error Indicator" ;
VAL_ 813 CDM_OpnClsState_SBCM_Copy_0 0 "Default" 1 "Open" 2 "Close" 3 "RESERVED" ;
VAL_ 813 CDM_WarnMsg_SBCM_Copy_0 0 "Default" 1 "Normal" 2 "ChargeDoorErrorState" 3 "RESERVED" ;
VAL_ 813 CDM_AutoWashModeSta_Copy_0 0 "Default" 1 "CDM Auto Wash Mode Off (Ready)" 2 "CDM Auto Wash Mode Off (Error)" 3 "CDM Auto Wash Mode On" 4 "RESERVED" 5 "RESERVED" 6 "RESERVED" 7 "Invalid" ;
VAL_ 813 CDM_CmdStatus_SBCM_Copy_0 0 "Open (AVN)" 1 "Open (SMK)" 2 "Open (Sensor Switch)" 3 "Open (Command Hard Switch)" 4 "Open (Anti - Pinch)" 5 "Close (AVN)" 6 "Close (SMK)" 7 "Close (Assist Mode)" 8 "Close (Command Hard Switch)" 9 "Close (Connector)" 10 "Close (Gear Position)" 11 "Close (Time Over)" 12 "Close (Anti - Pinch)" 13 "Close (Sensor Switch)" 14 "Stall (Stop)" 15 "Invalid" ;
VAL_ 813 CDM_OutsideOpnSwSta_Copy_0 0 "Default" 1 "Push" 2 "RESERVED" 3 "Invalid" ;
VAL_ 813 PwrDRBuzzerOut_DRV_Copy_0 0 "OFF" 1 "Open" 2 "Close" 3 "Warning" ;
VAL_ 813 Warn_HoodSwSta_SBCM_Copy_0 0 "Off" 1 "On" 2 "RESERVED" 3 "Error Indicator" ;
VAL_ 813 Hood_TypeOption_Copy_0 0 "Off (Mechanical hood latch is applied)" 1 "On (E-Hood latch is applied)" 2 "RESERVED" 3 "Error Indicator" ;
VAL_ 813 SBCM_FrunkSta_Copy_0 0 "Default" 1 "Valid" 2 "RESERVED" 3 "Error Indicator" ;
VAL_ 813 Warn_HoodSwFullSta_SBCM_Copy_0 0 "Off" 1 "On" 2 "RESERVED" 3 "Error Indicator" ;
VAL_ 813 FrunkWarning_SBCM_Copy_0 0 "Off" 1 "On" 2 "RESERVED" 3 "Error Indicator" ;
VAL_ 813 SBCM_Longkey_DRVDrAtClsSwSta_Cop 0 "Default" 1 "Off" 2 "On" 3 "Error Indicator" ;
VAL_ 813 FrunkReleaseSwSta_SBCM 0 "Off" 1 "HalfRelease" 2 "FullRelease" 3 "SwitchError" ;
VAL_ 813 PwrDRClosingDRVDrSta_Copy_0 0 "Default" 1 "Close" 2 "Open" 3 "Stop(during Close)" 4 "Stop(during Open)" 5 "RESERVED" 6 "RESERVED" 7 "Invalid" ;
VAL_ 813 Drv_DrLkRetryFail_SBCM_Copy_0 0 "Normal" 1 "Fail" 2 "RESERVED" 3 "RESERVED" ;
VAL_ 813 CDM_GbtImmeChgSw_SBCM_Copy_0 0 "Default" 1 "Off" 2 "On" 3 "RESERVED" ;
VAL_ 813 CDM_GbtOpnClsState_SBCM_Copy_0 0 "Default" 1 "Open" 2 "Close" 3 "RESERVED" ;
VAL_ 813 CDM_GbtWarnMsg_SBCM_Copy_0 0 "Default" 1 "Normal" 2 "ChargeDoorErrorState" 3 "RESERVED" ;
VAL_ 813 CDM_GbtOutsideOpnSwSta_Copy_0 0 "Default" 1 "Push" 2 "RESERVED" 3 "Invalid" ;
VAL_ 813 DoorLock_DrvLkOutSta_SBCM_Copy_0 0 "Off" 1 "On" 2 "Not Used" 3 "Error Indicator" ;
VAL_ 813 FrunkEmergencySwSta_SBCM 0 "Off" 1 "On" 2 "Not Used" 3 "Error Indicator" ;
VAL_ 813 DRV_DetectObj_warn_LH 0 "Detect Left Warning OFF" 1 "Detect Left Warning ON" 2 "RESERVED" 3 "RESERVED" ;
VAL_ 813 PwrDROpenClosingDdvSdDRSta 0 "Default" 1 "Close" 2 "Open" 3 "Stop(during Close)" 4 "Stop(during Open)" 5 "RESERVED" 6 "RESERVED" 7 "Invalid" ;
VAL_ 813 PwrDRBuzzerOut_DRV_New 0 "OFF" 1 "Open" 2 "Close" 3 "Warning1" 4 "Warning2" ;
VAL_ 813 Coach_TypeOption_DRV 0 "Off" 1 "On" 2 "Not Used" 3 "Error Indicator" ;
VAL_ 813 PwrDrSta_Drv 0 "Unavailable" 1 "Available" 2 "RESERVED" 3 "Error Indicator" ;
VAL_ 813 PwrDrSta_DrvSd 0 "Unavailable" 1 "Available" 2 "RESERVED" 3 "Error Indicator" ;
VAL_ 813 USM_PwrDrOpnTypSta 0 "Default" 1 "Pop-up" 2 "Full Open" 3 "RESERVED" ;
VAL_ 813 DischrgDr_OpnClsState_SBCM 0 "Default" 1 "Open" 2 "Close" 3 "Invalid" ;
VAL_ 813 SBCM_FL_DoorAngle 0 "0б╞ - 90б╞" 1 "0б╞ - 90б╞" 2 "0б╞ - 90б╞" 3 "0б╞ - 90б╞" 4 "0б╞ - 90б╞" 5 "0б╞ - 90б╞" 6 "0б╞ - 90б╞" 7 "0б╞ - 90б╞" 8 "0б╞ - 90б╞" 9 "0б╞ - 90б╞" 10 "0б╞ - 90б╞" 11 "0б╞ - 90б╞" 12 "0б╞ - 90б╞" 13 "0б╞ - 90б╞" 14 "0б╞ - 90б╞" 15 "0б╞ - 90б╞" 16 "0б╞ - 90б╞" 17 "0б╞ - 90б╞" 18 "0б╞ - 90б╞" 19 "0б╞ - 90б╞" 20 "0б╞ - 90б╞" 21 "0б╞ - 90б╞" 22 "0б╞ - 90б╞" 23 "0б╞ - 90б╞" 24 "0б╞ - 90б╞" 25 "0б╞ - 90б╞" 26 "0б╞ - 90б╞" 27 "0б╞ - 90б╞" 28 "0б╞ - 90б╞" 29 "0б╞ - 90б╞" 30 "0б╞ - 90б╞" 31 "0б╞ - 90б╞" 32 "0б╞ - 90б╞" 33 "0б╞ - 90б╞" 34 "0б╞ - 90б╞" 35 "0б╞ - 90б╞" 36 "0б╞ - 90б╞" 37 "0б╞ - 90б╞" 38 "0б╞ - 90б╞" 39 "0б╞ - 90б╞" 40 "0б╞ - 90б╞" 41 "0б╞ - 90б╞" 42 "0б╞ - 90б╞" 43 "0б╞ - 90б╞" 44 "0б╞ - 90б╞" 45 "0б╞ - 90б╞" 46 "0б╞ - 90б╞" 47 "0б╞ - 90б╞" 48 "0б╞ - 90б╞" 49 "0б╞ - 90б╞" 50 "0б╞ - 90б╞" 51 "0б╞ - 90б╞" 52 "0б╞ - 90б╞" 53 "0б╞ - 90б╞" 54 "0б╞ - 90б╞" 55 "0б╞ - 90б╞" 56 "0б╞ - 90б╞" 57 "0б╞ - 90б╞" 58 "0б╞ - 90б╞" 59 "0б╞ - 90б╞" 60 "0б╞ - 90б╞" 61 "0б╞ - 90б╞" 62 "0б╞ - 90б╞" 63 "0б╞ - 90б╞" 64 "0б╞ - 90б╞" 65 "0б╞ - 90б╞" 66 "0б╞ - 90б╞" 67 "0б╞ - 90б╞" 68 "0б╞ - 90б╞" 69 "0б╞ - 90б╞" 70 "0б╞ - 90б╞" 71 "0б╞ - 90б╞" 72 "0б╞ - 90б╞" 73 "0б╞ - 90б╞" 74 "0б╞ - 90б╞" 75 "0б╞ - 90б╞" 76 "0б╞ - 90б╞" 77 "0б╞ - 90б╞" 78 "0б╞ - 90б╞" 79 "0б╞ - 90б╞" 80 "0б╞ - 90б╞" 81 "0б╞ - 90б╞" 82 "0б╞ - 90б╞" 83 "0б╞ - 90б╞" 84 "0б╞ - 90б╞" 85 "0б╞ - 90б╞" 86 "0б╞ - 90б╞" 87 "0б╞ - 90б╞" 88 "0б╞ - 90б╞" 89 "0б╞ - 90б╞" 90 "0б╞ - 90б╞" 91 "Invalid" 92 "Invalid" 93 "Invalid" 94 "Invalid" 95 "Invalid" 96 "Invalid" 97 "Invalid" 98 "Invalid" 99 "Invalid" 100 "Unknown" 101 "Invalid" 102 "Invalid" 103 "Invalid" 104 "Invalid" 105 "Invalid" 106 "Invalid" 107 "Invalid" 108 "Invalid" 109 "Invalid" 110 "Invalid" 111 "Invalid" 112 "Invalid" 113 "Invalid" 114 "Invalid" 115 "Invalid" 116 "Invalid" 117 "Invalid" 118 "Invalid" 119 "Invalid" 120 "Invalid" 121 "Invalid" 122 "Invalid" 123 "Invalid" 124 "Invalid" 125 "Invalid" 126 "Invalid" 127 "Invalid" ;
VAL_ 813 SBCM_DoorType_DRV 0 "Two Door" 1 "Four Door" 2 "Not Used" 3 "Error Indicator" ;
VAL_ 813 CDM_DrType_DRV 0 "None" 1 "Electric" 2 "Manual" 3 "RESERVED" ;
VAL_ 813 DRVDoorPushAlarm_Copy_0 0 "Off" 1 "On" 2 "RESERVED" 3 "Error Indicator" ;
VAL_ 813 DRV_CrashUnlockCmd_Copy_0 0 "Off" 1 "Unlock(Crash)" ;
VAL_ 813 C_ApprOpenStatus_Copy_0 0 "Approach Open Off" 1 "Approach Open On" ;
VAL_ 813 DoorLock_DrvKeyLkSwSta_SBCM_Copy 0 "Off" 1 "Lock" 2 "RESERVED" 3 "Error Indicator" ;
VAL_ 813 DoorLock_DrvKeyUnLkSwSta_SBCM_Co 0 "Off" 1 "Unlock" 2 "RESERVED" 3 "Error Indicator" ;
VAL_ 813 Warn_DrvDrSwSta_SBCM_Copy_0 0 "Close" 1 "Open" 2 "RESERVED" 3 "Error Indicator" ;
VAL_ 813 DoorLock_DrvDrUnLkSta_SBCM_Copy_ 0 "Lock" 1 "Unlock" 2 "RESERVED" 3 "Error Indicator" ;
VAL_ 813 DRV_SEAWarn_LH_Copy_0 0 "SEA Left Warning OFF" 1 "SEA Left Warning ON" 2 "RESERVED" 3 "RESERVED" ;
VAL_ 813 DRV_SEAWarn_RH_Copy_0 0 "SEA Right Warning OFF" 1 "SEA Right  Warning ON" 2 "RESERVED" 3 "RESERVED" ;
VAL_ 813 DRV_SEWWarn_LH_Copy_0 0 "SEW Left Warning OFF" 1 "SEW Left Warning ON" 2 "RESERVED" 3 "RESERVED" ;
VAL_ 813 DRV_SEWWarn_RH_Copy_0 0 "SEW Right Warning OFF" 1 "SEW Right Warning ON" 2 "RESERVED" 3 "RESERVED" ;
VAL_ 813 DRV_MRActivationAlarm_Copy_0 0 "Off" 1 "On" 2 "RESERVED" 3 "Error Indicator" ;
VAL_ 813 DRV_ReleaseWarn_Copy_0 0 "Release Warning OFF" 1 "Release Warning ON" 2 "RESERVED" 3 "RESERVED" ;
VAL_ 811 SBCM_AST_FD_Crc1Val 0 "0x0x0~0xFFFF:CRCValue" 65535 "0x0x0~0xFFFF:CRCValue" ;
VAL_ 811 USM_AstGhostDoorSta_Copy_0 0 "Default" 1 "Off" 2 "On" 3 "RESERVED" ;
VAL_ 811 AST_SWFailAlarm_Copy_0 0 "Off" 1 "On" 2 "RESERVED" 3 "Error Indicator" ;
VAL_ 811 DoorLock_PDSLkSwSta_AST_Copy_0 0 "Lock" 1 "Unlock" 2 "RESERVED" 3 "Error Indicator" ;
VAL_ 811 PDS_TypeOption_AST_Copy_0 0 "Off" 1 "On" 2 "RESERVED" 3 "Error Indicator" ;
VAL_ 811 AFCU_AutoWashModeSta_SBCM_AST_Co 0 "Default" 1 "AFCU Auto Wash Mode Off (Ready)" 2 "AFCU Auto Wash Mode Off (Error)" 3 "AFCU Auto Wash Mode On" 4 "RESERVED" 5 "RESERVED" 6 "RESERVED" 7 "Invalid" ;
VAL_ 811 CDM_AutoWashModeSta_SBCM_AST_Cop 0 "Default" 1 "CDM Auto Wash Mode Off (Ready)" 2 "CDM Auto Wash Mode Off (Error)" 3 "CDM Auto Wash Mode On" 4 "RESERVED" 5 "RESERVED" 6 "RESERVED" 7 "Invalid" ;
VAL_ 811 AFH_AST_FldUnFldSta_Copy_0 0 "Invalid" 1 "Fold" 2 "Unfold" 3 "Inprogress" ;
VAL_ 811 SBCM_AST_DiagSta_Copy_0 0 "Default" 1 "Normal Operation" 2 "AST Indicator Circuit Failure" 3 "RESERVED" ;
VAL_ 811 CDM_TypeOption_AST_Copy_0 0 "Off" 1 "On" 2 "On_2EA" 3 "Error Indicator" ;
VAL_ 811 CDM_ImmeChgSw_AST_Copy_0 0 "Default" 1 "Off" 2 "On" 3 "RESERVED" ;
VAL_ 811 CDM_FobSrchReq_AST_Copy_0 0 "Off" 1 "On" 2 "RESERVED" 3 "Error Indicator" ;
VAL_ 811 CDM_OpnClsState_AST_Copy_0 0 "Default" 1 "Open" 2 "Close" 3 "RESERVED" ;
VAL_ 811 CDM_WarnMsg_AST_Copy_0 0 "Default" 1 "Normal" 2 "ChargeDoorErrorState" 3 "RESERVED" ;
VAL_ 811 Mirror_RH_FoldingSta_Copy_0 0 "Off" 1 "Folding" 2 "RESERVED" 3 "Error Indicator" ;
VAL_ 811 Mirror_RH_UnfoldingSta_Copy_0 0 "Off" 1 "Unfolding" 2 "RESERVED" 3 "Error Indicator" ;
VAL_ 811 CDM_CmdStatus_AST_Copy_0 0 "Open (AVN)" 1 "Open (SMK)" 2 "Open (Sensor Switch)" 3 "Open (Command Hard Switch)" 4 "Open (Anti - Pinch)" 5 "Close (AVN)" 6 "Close (SMK)" 7 "Close (Assist Mode)" 8 "Close (Command Hard Switch)" 9 "Close (Connector)" 10 "Close (Gear Position)" 11 "Close (Time Over)" 12 "Close (Anti - Pinch)" 13 "Close (Sensor Switch)" 14 "Stall (Stop)" 15 "Invalid" ;
VAL_ 811 SBCM_AST_FD_AlvCnt1Val 0 "0x0x0~0xFF:AlvCntValue" 255 "0x0x0~0xFF:AlvCntValue" ;
VAL_ 811 AST_CrashMRActAlarm_Copy_0 0 "Off" 1 "On" 2 "RESERVED" 3 "Error Indicator" ;
VAL_ 811 PwrDRBuzzerOut_AST_Copy_0 0 "OFF" 1 "Open" 2 "Close" 3 "Warning" ;
VAL_ 811 IMS_OSMirPlayBackSta_RH_Copy_0 0 "Stop" 1 "Play 1" 2 "Play 2" 3 "Play 3" 4 "Smart IMS" 5 "Profile 1" 6 "Profile 2" 7 "Guest" 8 "RESERVED" 9 "RESERVED" 10 "RESERVED" 11 "RESERVED" 12 "RESERVED" 13 "RESERVED" 14 "RESERVED" 15 "Error Indicator" ;
VAL_ 811 PwrDRClosingASTDrSta_Copy_0 0 "Default" 1 "Close" 2 "Open" 3 "Stop(during Close)" 4 "Stop(during Open)" 5 "RESERVED" 6 "RESERVED" 7 "Invalid" ;
VAL_ 811 CDM_OutsideOpnSwSta_AST_Copy_0 0 "Default" 1 "Push" 2 "RESERVED" 3 "Invalid" ;
VAL_ 811 SBCM_Longkey_ASTDrAtClsSwSta_Cop 0 "Default" 1 "Off" 2 "On" 3 "Error Indicator" ;
VAL_ 811 Hood_TypeOption_AST_Copy_0 0 "Off (Mechanical hood latch is applied)" 1 "On (E-Hood latch is applied)" 2 "RESERVED" 3 "Error Indicator" ;
VAL_ 811 Warn_HoodSwSta_AST_Copy_0 0 "Off" 1 "On" 2 "RESERVED" 3 "Error Indicator" ;
VAL_ 811 FrunkWarning_AST_Copy_0 0 "Off" 1 "On" 2 "RESERVED" 3 "Error Indicator" ;
VAL_ 811 SBCM_FrunkSta_AST_Copy_0 0 "Default" 1 "Valid" 2 "RESERVED" 3 "Error Indicator" ;
VAL_ 811 IMS_OSMirPlayBackSta_RH_New_Copy 0 "Stop" 1 "Play 1" 2 "Play 2" 3 "Play 3" 4 "Smart IMS" 5 "Profile 1" 6 "Profile 2" 7 "Profile 3" 8 "Profile 4" 9 "Profile 5" 10 "Profile 6" 11 "Profile 7" 12 "Profile 8" 13 "Profile 9" 14 "Guest" 15 "Error Indicator" ;
VAL_ 811 Ast_DrLkRetryFail_SBCM_Copy_0 0 "Normal" 1 "Fail" 2 "RESERVED" 3 "RESERVED" ;
VAL_ 811 DoorLock_AstLkOutSta_SBCM_Copy_0 0 "Off" 1 "On" 2 "Not Used" 3 "Error Indicator" ;
VAL_ 811 FrunkReleaseSwSta_SBCM_AST 0 "Off" 1 "HalfRelease" 2 "FullRelease" 3 "SwitchError" ;
VAL_ 811 FrunkInsideRelSwSta_SBCM_AST 0 "Off" 1 "On" 2 "Not Used" 3 "Error Indicator" ;
VAL_ 811 FrunkEmergencySwSta_SBCM_AST 0 "Off" 1 "On" 2 "Not Used" 3 "Error Indicator" ;
VAL_ 811 PwrDrSta_Ast 0 "Unavailable" 1 "Available" 2 "RESERVED" 3 "Error Indicator" ;
VAL_ 811 PwrDrSta_AstSd 0 "Unavailable" 1 "Available" 2 "RESERVED" 3 "Error Indicator" ;
VAL_ 811 DischrgDr_OpnClsState_SBCM_AST 0 "Default" 1 "Open" 2 "Close" 3 "Invalid" ;
VAL_ 811 AST_DetectObj_warn_LH 0 "Detect Left Warning OFF" 1 "Detect Left Warning ON" 2 "RESERVED" 3 "RESERVED" ;
VAL_ 811 PwrDROpenClosingAstSdDRSta 0 "Default" 1 "Close" 2 "Open" 3 "Stop(during Close)" 4 "Stop(during Open)" 5 "RESERVED" 6 "RESERVED" 7 "Invalid" ;
VAL_ 811 PwrDRBuzzerOut_AST_New 0 "OFF" 1 "Open" 2 "Close" 3 "Warning1" 4 "Warning2" ;
VAL_ 811 SBCM_FR_DoorAngle 0 "0б╞ - 90б╞" 1 "0б╞ - 90б╞" 2 "0б╞ - 90б╞" 3 "0б╞ - 90б╞" 4 "0б╞ - 90б╞" 5 "0б╞ - 90б╞" 6 "0б╞ - 90б╞" 7 "0б╞ - 90б╞" 8 "0б╞ - 90б╞" 9 "0б╞ - 90б╞" 10 "0б╞ - 90б╞" 11 "0б╞ - 90б╞" 12 "0б╞ - 90б╞" 13 "0б╞ - 90б╞" 14 "0б╞ - 90б╞" 15 "0б╞ - 90б╞" 16 "0б╞ - 90б╞" 17 "0б╞ - 90б╞" 18 "0б╞ - 90б╞" 19 "0б╞ - 90б╞" 20 "0б╞ - 90б╞" 21 "0б╞ - 90б╞" 22 "0б╞ - 90б╞" 23 "0б╞ - 90б╞" 24 "0б╞ - 90б╞" 25 "0б╞ - 90б╞" 26 "0б╞ - 90б╞" 27 "0б╞ - 90б╞" 28 "0б╞ - 90б╞" 29 "0б╞ - 90б╞" 30 "0б╞ - 90б╞" 31 "0б╞ - 90б╞" 32 "0б╞ - 90б╞" 33 "0б╞ - 90б╞" 34 "0б╞ - 90б╞" 35 "0б╞ - 90б╞" 36 "0б╞ - 90б╞" 37 "0б╞ - 90б╞" 38 "0б╞ - 90б╞" 39 "0б╞ - 90б╞" 40 "0б╞ - 90б╞" 41 "0б╞ - 90б╞" 42 "0б╞ - 90б╞" 43 "0б╞ - 90б╞" 44 "0б╞ - 90б╞" 45 "0б╞ - 90б╞" 46 "0б╞ - 90б╞" 47 "0б╞ - 90б╞" 48 "0б╞ - 90б╞" 49 "0б╞ - 90б╞" 50 "0б╞ - 90б╞" 51 "0б╞ - 90б╞" 52 "0б╞ - 90б╞" 53 "0б╞ - 90б╞" 54 "0б╞ - 90б╞" 55 "0б╞ - 90б╞" 56 "0б╞ - 90б╞" 57 "0б╞ - 90б╞" 58 "0б╞ - 90б╞" 59 "0б╞ - 90б╞" 60 "0б╞ - 90б╞" 61 "0б╞ - 90б╞" 62 "0б╞ - 90б╞" 63 "0б╞ - 90б╞" 64 "0б╞ - 90б╞" 65 "0б╞ - 90б╞" 66 "0б╞ - 90б╞" 67 "0б╞ - 90б╞" 68 "0б╞ - 90б╞" 69 "0б╞ - 90б╞" 70 "0б╞ - 90б╞" 71 "0б╞ - 90б╞" 72 "0б╞ - 90б╞" 73 "0б╞ - 90б╞" 74 "0б╞ - 90б╞" 75 "0б╞ - 90б╞" 76 "0б╞ - 90б╞" 77 "0б╞ - 90б╞" 78 "0б╞ - 90б╞" 79 "0б╞ - 90б╞" 80 "0б╞ - 90б╞" 81 "0б╞ - 90б╞" 82 "0б╞ - 90б╞" 83 "0б╞ - 90б╞" 84 "0б╞ - 90б╞" 85 "0б╞ - 90б╞" 86 "0б╞ - 90б╞" 87 "0б╞ - 90б╞" 88 "0б╞ - 90б╞" 89 "0б╞ - 90б╞" 90 "0б╞ - 90б╞" 91 "Invalid" 92 "Invalid" 93 "Invalid" 94 "Invalid" 95 "Invalid" 96 "Invalid" 97 "Invalid" 98 "Invalid" 99 "Invalid" 100 "Unknown" 101 "Invalid" 102 "Invalid" 103 "Invalid" 104 "Invalid" 105 "Invalid" 106 "Invalid" 107 "Invalid" 108 "Invalid" 109 "Invalid" 110 "Invalid" 111 "Invalid" 112 "Invalid" 113 "Invalid" 114 "Invalid" 115 "Invalid" 116 "Invalid" 117 "Invalid" 118 "Invalid" 119 "Invalid" 120 "Invalid" 121 "Invalid" 122 "Invalid" 123 "Invalid" 124 "Invalid" 125 "Invalid" 126 "Invalid" 127 "Invalid" ;
VAL_ 811 EHL_TxInfo_SBCM_AST 0 "Default" 1 "EHL_AST_Close" 2 "EHL_AST_Half" 3 "EHL_AST_Open" 4 "EHL_AST_RetryFlag" 5 "EHL_AST_ErrorIndicator" 6 "EHL_AST_Opening" 7 "Invalid" ;
VAL_ 811 CDM_DrType_AST 0 "None" 1 "Electric" 2 "Manual" 3 "RESERVED" ;
VAL_ 811 ASTDoorPushAlarm_Copy_0 0 "Off" 1 "On" 2 "RESERVED" 3 "Error Indicator" ;
VAL_ 811 AST_CrashUnlockCmd_Copy_0 0 "Off" 1 "Unlock (Crash)" ;
VAL_ 811 DoorLock_CtrlDrLkSwSta_SBCM_Copy 0 "Off" 1 "On (Lock On)" 2 "RESERVED" 3 "Error Indicator" ;
VAL_ 811 DoorLock_CtrlDrUnLkSwSta_SBCM_Co 0 "Off" 1 "On (Unlock On)" 2 "RESERVED" 3 "Error Indicator" ;
VAL_ 811 Warn_AsstDrSwSta_SBCM_Copy_0 0 "Close" 1 "Open" 2 "RESERVED" 3 "Error Indicator" ;
VAL_ 811 DoorLock_AsstDrUnLkSta_SBCM_Copy 0 "Lock" 1 "Unlock" 2 "RESERVED" 3 "Error Indicator" ;
VAL_ 811 AST_SEAWarn_RH_Copy_0 0 "SEA Right Warning OFF" 1 "SEA Right Warning ON" 2 "RESERVED" 3 "RESERVED" ;
VAL_ 811 AST_SEAWarn_LH_Copy_0 0 "SEA Left Warning OFF" 1 "SEA Left Warning ON" 2 "RESERVED" 3 "RESERVED" ;
VAL_ 811 AST_SEWWarn_LH_Copy_0 0 "SEW Left Warning OFF" 1 "SEW Left Warning ON" 2 "RESERVED" 3 "RESERVED" ;
VAL_ 811 AST_SEWWarn_RH_Copy_0 0 "SEW Right Warning OFF" 1 "SEW Right Warning ON" 2 "RESERVED" 3 "RESERVED" ;
VAL_ 811 AST_MRActivationAlarm_Copy_0 0 "Off" 1 "On" 2 "RESERVED" 3 "Error Indicator" ;
VAL_ 811 AST_ReleaseWarn_Copy_0 0 "Release Warning OFF" 1 "Release Warning ON" 2 "RESERVED" 3 "RESERVED" ;
VAL_ 2525341953 L_UWB_FR_FD_Crc5Val 0 "0x0x0~0xFFFF:CRCValue" 65535 "0x0x0~0xFFFF:CRCValue" ;
VAL_ 2525341953 L_UWB_FR_FD_AlvCnt5Val 0 "0x0x0~0xFF:AlvCntValue" 255 "0x0x0~0xFF:AlvCntValue" ;
VAL_ 2521141761 L_UWB_BLE_MST_FD_Crc23Val 0 "0x0x0~0xFFFF:CRCValue" 65535 "0x0x0~0xFFFF:CRCValue" ;
VAL_ 2521141761 L_UWB_BLE_MST_FD_AlvCnt23Val 0 "0x0x0~0xFF:AlvCntValue" 255 "0x0x0~0xFF:AlvCntValue" ;
VAL_ 2521141761 MST_DTC 0 "0x0x0~0xFF:flag value" 255 "0x0x0~0xFF:flag value" ;
VAL_ 2521141761 MST_DTC_BLE 0 "0x0x0~0xFF:flag value" 255 "0x0x0~0xFF:flag value" ;
VAL_ 2521141761 Pulse_Shape_Combo_Info 0 "0x0x0~0x1FF:flag value" 511 "0x0x0~0x1FF:flag value" ;
VAL_ 2214592770 L_UWB_RR_FD_Crc3Val 0 "0x0x0~0xFFFF:CRCValue" 65535 "0x0x0~0xFFFF:CRCValue" ;
VAL_ 2214592770 L_UWB_RR_FD_AlvCnt3Val 0 "0x0x0~0xFF:AlvCntValue" 255 "0x0x0~0xFF:AlvCntValue" ;
VAL_ 2214592768 L_UWB_RR_FD_Crc1Val 0 "0x0x0~0xFFFF:CRCValue" 65535 "0x0x0~0xFFFF:CRCValue" ;
VAL_ 2214592768 L_UWB_RR_FD_AlvCnt1Val 0 "0x0x0~0xFF:AlvCntValue" 255 "0x0x0~0xFF:AlvCntValue" ;
VAL_ 2214592768 UWB_RR_UWB_Decrypt_FB 0 "Default" 1 "Positive" 2 "Negative" 3 "RESERVED" 4 "RESERVED" 5 "RESERVED" 6 "RESERVED" 7 "RESERVED" 8 "RESERVED" 9 "RESERVED" 10 "RESERVED" 11 "RESERVED" 12 "RESERVED" 13 "RESERVED" 14 "RESERVED" 15 "RESERVED" ;
VAL_ 2214592768 UWB_RR_MST_Decrypt_FB 0 "Default" 1 "Positive" 2 "Negative" 3 "RESERVED" 4 "RESERVED" 5 "RESERVED" 6 "RESERVED" 7 "RESERVED" 8 "RESERVED" 9 "RESERVED" 10 "RESERVED" 11 "RESERVED" 12 "RESERVED" 13 "RESERVED" 14 "RESERVED" 15 "RESERVED" ;
VAL_ 2214592768 UWB_RR_OTA_Rsp 0 "Default" 1 "Request_Success" 2 "Request_Fail" 3 "Erase_Success" 4 "Erase_Fail" 5 "RESERVED" 6 "RESERVED" 7 "Verify_Success" 8 "Verify_Fail" 9 "RESERVED" 10 "RESERVED" 11 "Pause_Response" 12 "RESERVED" 13 "RESERVED" 14 "RESERVED" 15 "RESERVED" ;
VAL_ 2214592768 UWB_RR_UWB_IC_Status 0 "Status_OK" 1 "Status_Rejected" 2 "Status_Failed" 3 "Status_Syntax_Error" 4 "Status_Invalid_Param" 5 "Status_Invalid_Range" 6 "Status_Invalid_Message" 7 "Status_Unknow_GID" 8 "Status_Unknow_OID" 9 "Status_Read_Only" 10 "Status_Com_Retry" 11 "RESERVED" 12 "RESERVED" 13 "RESERVED" 14 "RESERVED" 15 "RESERVED" 17 "Session_Not_Exist" 18 "Session_Duplicate" 19 "Session_Active" 20 "Session_Max" 21 "Session_Not_Config" 22 "Session_Ongonig" 23 "RESERVED" 24 "RESERVED" 25 "RESERVED" 26 "Error_Slot_Len" 27 "Error_Slot_Per_RR" 28 "Error_STS_IDX" 29 "RESERVED" 30 "RESERVED" 31 "RESERVED" 32 "RESERVED" 33 "Init_Rejected" 34 "Init_Failed" 35 "Start_Rejected" 36 "Start_Failed" 37 "0x25~0xFF:RESERVED" 255 "0x25~0xFF:RESERVED" ;
VAL_ 2214592769 L_UWB_RR_FD_Crc2Val 0 "0x0x0~0xFFFF:CRCValue" 65535 "0x0x0~0xFFFF:CRCValue" ;
VAL_ 2214592769 L_UWB_RR_FD_AlvCnt2Val 0 "0x0x0~0xFF:AlvCntValue" 255 "0x0x0~0xFF:AlvCntValue" ;
VAL_ 2281701456 L_BDC_FD_IAU_Crc10Val 0 "0x0x0~0xFFFF:CRCValue" 65535 "0x0x0~0xFFFF:CRCValue" ;
VAL_ 2281701456 L_BDC_FD_IAU_AlvCnt10Val 0 "0x0x0~0xFF:AlvCntValue" 255 "0x0x0~0xFF:AlvCntValue" ;
VAL_ 2281701456 BodyType_Sta 0 "Body Type 1" 1 "Body Type 2" 2 "Body Type 3" 3 "Body Type 4" 4 "Body Type 5" 5 "Body Type 6" 6 "Body Type 7" 7 "Body Type 8" ;
VAL_ 2281701456 Trunk_Tailgate_Info 0 "Trunk" 1 "Tailgate" 2 "RESERVED" 3 "Error Indicator" ;
VAL_ 2281701456 BDC_TP_CAN_Sta 0 "Idle" 1 "Process for WPC" 2 "Process for DHL" 3 "Process for DHR" 4 "Process for BLE_TRX" 5 "Process for DHRL" 6 "Process for DHRR" 7 "Process for BLE2_TRX" ;
VAL_ 2281701456 OPAdv_On_Cmd 0 "Default(Stop)" 1 "StartEnable" 2 "Reserve" 3 "Invalid" ;
VAL_ 2281701456 WPC_Device_On_Cmd 0 "Not key device" 1 "Phone key" 2 "Card key" 3 "Invaild" ;
VAL_ 2281701456 RgnTyp_Opt 0 "Domestic" 1 "General" 2 "MiddleEast" 3 "Europe" 4 "Australia" 5 "Canada" 6 "USA" 7 "China" 8 "India" 9 "Mexico" 10 "Brazil" 11 "Russia" 12 "Japan" 13 "RESERVED" 14 "RESERVED" 15 "RESERVED" ;
VAL_ 2281701456 SunRoofTyp_Opt 0 "NotApplied(Normal Roof)" 1 "Type1(Basic Sunroof)" 2 "Type2" 3 "Type3" 4 "RESERVED" 5 "RESERVED" 6 "RESERVED" 7 "Error Indicator" ;
VAL_ 2281701456 BDC_RSPA_DKID 0 "Default(Stop)" 1 "#1" 2 "#2" 3 "#3" 4 "#4" 5 "#5" 6 "#6" 7 "#7" 8 "#8" 9 "#9" 10 "#10" 11 "#11" 12 "#12" 13 "#13" 14 "#14" 15 "#15" 16 "#16" 17 "Reserve" 18 "Reserve" 19 "Reserve" 20 "Reserve" 21 "Reserve" 22 "Reserve" 23 "Reserve" 24 "Reserve" 25 "Reserve" 26 "Reserve" 27 "Reserve" 28 "Reserve" 29 "Reserve" 30 "Reserve" 31 "Invalid" ;
VAL_ 2281701457 L_BDC_FD_IAU_Crc11Val 0 "0x0x0~0xFFFF:CRCValue" 65535 "0x0x0~0xFFFF:CRCValue" ;
VAL_ 2281701457 L_BDC_FD_IAU_AlvCnt11Val 0 "0x0x0~0xFF:AlvCntValue" 255 "0x0x0~0xFF:AlvCntValue" ;
VAL_ 2214592786 L_UWB_TRNK_FD_Crc3Val 0 "0x0x0~0xFFFF:CRCValue" 65535 "0x0x0~0xFFFF:CRCValue" ;
VAL_ 2214592786 L_UWB_TRNK_FD_AlvCnt3Val 0 "0x0x0~0xFF:AlvCntValue" 255 "0x0x0~0xFF:AlvCntValue" ;
VAL_ 2214592785 L_UWB_TRNK_FD_Crc2Val 0 "0x0x0~0xFFFF:CRCValue" 65535 "0x0x0~0xFFFF:CRCValue" ;
VAL_ 2214592785 L_UWB_TRNK_FD_AlvCnt2Val 0 "0x0x0~0xFF:AlvCntValue" 255 "0x0x0~0xFF:AlvCntValue" ;
VAL_ 2214592784 L_UWB_TRNK_FD_Crc1Val 0 "0x0x0~0xFFFF:CRCValue" 65535 "0x0x0~0xFFFF:CRCValue" ;
VAL_ 2214592784 L_UWB_TRNK_FD_AlvCnt1Val 0 "0x0x0~0xFF:AlvCntValue" 255 "0x0x0~0xFF:AlvCntValue" ;
VAL_ 2214592784 UWB_TRNK_UWB_Decrypt_FB 0 "Default" 1 "Positive" 2 "Negative" 3 "RESERVED" 4 "RESERVED" 5 "RESERVED" 6 "RESERVED" 7 "RESERVED" 8 "RESERVED" 9 "RESERVED" 10 "RESERVED" 11 "RESERVED" 12 "RESERVED" 13 "RESERVED" 14 "RESERVED" 15 "RESERVED" ;
VAL_ 2214592784 UWB_TRNK_MST_Decrypt_FB 0 "Default" 1 "Positive" 2 "Negative" 3 "RESERVED" 4 "RESERVED" 5 "RESERVED" 6 "RESERVED" 7 "RESERVED" 8 "RESERVED" 9 "RESERVED" 10 "RESERVED" 11 "RESERVED" 12 "RESERVED" 13 "RESERVED" 14 "RESERVED" 15 "RESERVED" ;
VAL_ 2214592784 UWB_TRNK_OTA_Rsp 0 "Default" 1 "Request_Success" 2 "Request_Fail" 3 "Erase_Success" 4 "Erase_Fail" 5 "RESERVED" 6 "RESERVED" 7 "Verify_Success" 8 "Verify_Fail" 9 "RESERVED" 10 "RESERVED" 11 "Pause_Response" 12 "RESERVED" 13 "RESERVED" 14 "RESERVED" 15 "RESERVED" ;
VAL_ 2214592784 UWB_TRNK_UWB_IC_Status 0 "Status_OK" 1 "Status_Rejected" 2 "Status_Failed" 3 "Status_Syntax_Error" 4 "Status_Invalid_Param" 5 "Status_Invalid_Range" 6 "Status_Invalid_Message" 7 "Status_Unknow_GID" 8 "Status_Unknow_OID" 9 "Status_Read_Only" 10 "Status_Com_Retry" 11 "RESERVED" 12 "RESERVED" 13 "RESERVED" 14 "RESERVED" 15 "RESERVED" 17 "Session_Not_Exist" 18 "Session_Duplicate" 19 "Session_Active" 20 "Session_Max" 21 "Session_Not_Config" 22 "Session_Ongonig" 23 "RESERVED" 24 "RESERVED" 25 "RESERVED" 26 "Error_Slot_Len" 27 "Error_Slot_Per_RR" 28 "Error_STS_IDX" 29 "RESERVED" 30 "RESERVED" 31 "RESERVED" 32 "RESERVED" 33 "Init_Rejected" 34 "Init_Failed" 35 "Start_Rejected" 36 "Start_Failed" 37 "0x25~0xFF:RESERVED" 255 "0x25~0xFF:RESERVED" ;
VAL_ 2533738497 L_UWB_FRNK_FD_Crc4Val 0 "0x0x0~0xFFFF:CRCValue" 65535 "0x0x0~0xFFFF:CRCValue" ;
VAL_ 2533738497 L_UWB_FRNK_FD_AlvCnt4Val 0 "0x0x0~0xFF:AlvCntValue" 255 "0x0x0~0xFF:AlvCntValue" ;
VAL_ 2529540097 L_UWB_RR_FD_Crc4Val 0 "0x0x0~0xFFFF:CRCValue" 65535 "0x0x0~0xFFFF:CRCValue" ;
VAL_ 2529540097 L_UWB_RR_FD_AlvCnt4Val 0 "0x0x0~0xFF:AlvCntValue" 255 "0x0x0~0xFF:AlvCntValue" ;
VAL_ 1337 UWB_RR_FD_Crc30Val 0 "0x0x0~0xFFFF:CRCValue" 65535 "0x0x0~0xFFFF:CRCValue" ;
VAL_ 1337 UWB_RR_FD_AlvCnt30Val 0 "0x0x0~0xFF:AlvCntValue" 255 "0x0x0~0xFF:AlvCntValue" ;
VAL_ 1337 UWB_RR_ResetOpsta 0 "Normal" 1 "Reset Complete" 2 "Reset Fail" 3 "RESERVED" ;
VAL_ 1336 UWB_RL_FD_Crc30Val 0 "0x0x0~0xFFFF:CRCValue" 65535 "0x0x0~0xFFFF:CRCValue" ;
VAL_ 1336 UWB_RL_FD_AlvCnt30Val 0 "0x0x0~0xFF:AlvCntValue" 255 "0x0x0~0xFF:AlvCntValue" ;
VAL_ 1336 UWB_RL_ResetOpsta 0 "Normal" 1 "Reset Complete" 2 "Reset Fail" 3 "RESERVED" ;
VAL_ 850 IAU_FD_Crc5Val 0 "0x0x0~0xFFFF:CRCValue" 65535 "0x0x0~0xFFFF:CRCValue" ;
VAL_ 850 IAU_DigitalKeyProfileRval_Copy_0 0 "Default" 1 "1st digital key (owner)" 2 "2nd digital key" 3 "3rd digital key" 4 "4th digital key" 5 "5th digital key" 6 "6th digital key" 7 "7th digital key" 8 "8th digital key" 9 "reserved" 10 "reserved" 11 "reserved" 12 "reserved" 13 "reserved" 14 "reserved" 15 "Invalid" ;
VAL_ 850 IAU_SharedPhnRegStat_Copy_0 0 "Defautl (Not Exist)" 1 "Exist" 2 "Reserve" 3 "Invalid" ;
VAL_ 850 IAU_CardKeyEnblRVal_Copy_0 0 "Default" 1 "Disable" 2 "Enable" 3 "Invalid" ;
VAL_ 850 IAU_DrvDHLPhnDetect_Copy_0 0 "Default(Off)" 1 "On" 2 "Not used" 3 "Invalid" ;
VAL_ 850 IAU_AstDHLPhnDetect_Copy_0 0 "Default(Off)" 1 "On" 2 "Not used" 3 "Invalid" ;
VAL_ 850 IAU_RLDHLPhnDetect_Copy_0 0 "Default(Off)" 1 "On" 2 "Not used" 3 "Invalid" ;
VAL_ 850 IAU_RRDHLPhnDetect_Copy_0 0 "Defualt(Off)" 1 "On" 2 "Not used" 3 "Invalid" ;
VAL_ 850 IAU_Manufacturer_Copy_0 0 "0x0x00~0xFF:ASCII Code Value (HEX)" 255 "0x0x00~0xFF:ASCII Code Value (HEX)" ;
VAL_ 850 IAU_VendorCode_Copy_0 0 "0x0x000000~0xFFFFFF:ASCII Code Value (HEX)" 16777215 "0x0x000000~0xFFFFFF:ASCII Code Value (HEX)" ;
VAL_ 850 IAU_FD_AlvCnt5Val 0 "0x0x0~0xFF:AlvCntValue" 255 "0x0x0~0xFF:AlvCntValue" ;
VAL_ 850 IAU_Serial_Copy_0 0 "0x0x00000000~0xFFFFFFFF:ASCII Code Value (HEX)" 2147483647 "0x0x00000000~0xFFFFFFFF:ASCII Code Value (HEX)" ;
VAL_ 850 IAU_Year_Copy_0 0 "0x0x0000~0xFFFF:ASCII Code Value (HEX)" 65535 "0x0x0000~0xFFFF:ASCII Code Value (HEX)" ;
VAL_ 850 IAU_Month_Copy_0 0 "0x0x00~0xFF:ASCII Code Value (HEX)" 255 "0x0x00~0xFF:ASCII Code Value (HEX)" ;
VAL_ 850 IAU_Date_Copy_0 0 "0x0x0000~0xFFFF:ASCII Code Value (HEX)" 65535 "0x0x0000~0xFFFF:ASCII Code Value (HEX)" ;
VAL_ 850 IAU_SWVerMajor1_Copy_0 0 "0x0x0~0x7F:ASCII Code Value (HEX)" 127 "0x0x0~0x7F:ASCII Code Value (HEX)" ;
VAL_ 850 IAU_DrvDhsRainStat 0 "Off" 1 "Rain" ;
VAL_ 850 IAU_SWVerMinor1_Copy_0 0 "0x0x0~0x7F:ASCII Code Value (HEX)" 127 "0x0x0~0x7F:ASCII Code Value (HEX)" ;
VAL_ 850 IAU_SWVerMinor2_Copy_0 0 "0x0x0~0x7F:ASCII Code Value (HEX)" 127 "0x0x0~0x7F:ASCII Code Value (HEX)" ;
VAL_ 850 IAU_AstDhsRainStat 0 "Off" 1 "Rain" ;
VAL_ 850 IAU_RLDhsRainStat 0 "Off" 1 "Rain" ;
VAL_ 850 IAU_RRDhsRainStat 0 "Off" 1 "Rain" ;
